VERSION ""

NS_ :

BS_:

BU_: CH DIPF DIPR ETH FC HVI HVS PARTY SDCV VEH VIRT

BO_ 1824 DAS_debug: 8 CH
 SG_ DAS_ACC_BCW m20 : 63|1@1+ (1,0) [0|1] ""  X
 SG_ DAS_driver_interaction_detected m45 : 63|1@1+ (1,0) [0|1] ""  X
 SG_ DAS_LC_Hands_On_Caused_By_Curve m40 : 63|1@1+ (1,0) [0|1] ""  X
 SG_ DAS_FCM_SL_radarMatchConfOK m32 : 62|1@1+ (1,0) [0|1] ""  X
 SG_ DAS_ACC_BCW_decelCheck m20 : 62|1@1+ (1,0) [0|1] ""  X
 SG_ DAS_FCM_CIPV_radarMatchConfOK m30 : 62|1@1+ (1,0) [0|1] ""  X
 SG_ DAS_pp_laneChange_freesp_avail_r m48 : 62|1@1+ (1,0) [0|1] ""  X
 SG_ DAS_VL_egoLaneChange m51 : 62|2@1+ (1,0) [0|3] ""  X
 SG_ DAS_LCM_CIPV_valid m37 : 62|1@1+ (1,0) [0|1] ""  X
 SG_ DAS_FCM_MCP_radarMatchConfOK m31 : 62|1@1+ (1,0) [0|1] ""  X
 SG_ DAS_SCA_egoCentered m45 : 62|1@1+ (1,0) [0|1] ""  X
 SG_ DAS_FCM_TA_mode m33 : 62|2@1+ (1,0) [0|3] ""  X
 SG_ DAS_FCM_MCP_valid m31 : 61|1@1+ (1,0) [0|1] ""  X
 SG_ DAS_HmVlNoInputsOAL m42 : 61|3@1+ (1,0) [0|7] ""  X
 SG_ DAS_FCM_SL_valid m32 : 61|1@1+ (1,0) [0|1] ""  X
 SG_ DAS_VL_V5_fuse m51 : 61|1@1+ (1,0) [0|1] ""  X
 SG_ DAS_pp_laneChange_freesp_avail_l m48 : 61|1@1+ (1,0) [0|1] ""  X
 SG_ DAS_accTimeGap m6 : 61|3@1+ (0.2,0.8) [0.8|2.2] "s"  X
 SG_ DAS_SCA_polyValid m45 : 61|1@1+ (1,0) [0|1] ""  X
 SG_ DAS_FCM_CIPV_valid m30 : 61|1@1+ (1,0) [0|1] ""  X
 SG_ DAS_ACC_tgt_mcvl_delay m24 : 60|4@1+ (20,0) [0|300] "ms"  X
 SG_ DAS_VL_LinePreference m50 : 60|3@1+ (1,0) [0|7] ""  X
 SG_ DAS_SCA_egoMovingRight m45 : 60|1@1+ (1,0) [0|1] ""  X
 SG_ DAS_ACC_tgt_cutin_delay m26 : 60|4@1+ (20,0) [0|300] "ms"  X
 SG_ DAS_ACC_tgt_cipv_delay m22 : 60|4@1+ (20,0) [0|300] "ms"  X
 SG_ DAS_ACC_tgt_cipv2_delay m23 : 60|4@1+ (20,0) [0|300] "ms"  X
 SG_ DAS_freespaceRightNearZ m2 : 60|4@1+ (4,0) [0|60] "m"  X
 SG_ DAS_LCM_CIPV_type m37 : 60|2@1+ (1,0) [0|3] ""  X
 SG_ DAS_ACC_tgt_mcvr_delay m25 : 60|4@1+ (20,0) [0|300] "ms"  X
 SG_ DAS_VL_V4_fuse m51 : 60|1@1+ (1,0) [0|1] ""  X
 SG_ DAS_ACC_overtakeMode m20 : 59|2@1+ (1,0) [0|3] ""  X
 SG_ DAS_ACC_tgt_cipv_blinkerRight m22 : 59|1@1+ (1,0) [0|1] ""  X
 SG_ DAS_ACC_Activate_pedestrian m28 : 59|1@1+ (1,0) [0|1] ""  X
 SG_ DAS_ACC_tgt_cipv2_blinkerRight m23 : 59|1@1+ (1,0) [0|1] ""  X
 SG_ DAS_VL_V3_fuse m51 : 59|1@1+ (1,0) [0|1] ""  X
 SG_ DAS_ACC_tgt_cutin_blinkerRight m26 : 59|1@1+ (1,0) [0|1] ""  X
 SG_ DAS_ACC_Target6_delay m27 : 59|4@1+ (20,0) [0|300] "ms"  X
 SG_ DAS_ACC_tgt_mcvr_blinkerRight m25 : 59|1@1+ (1,0) [0|1] ""  X
 SG_ DAS_ACC_tgt_mcvl_blinkerRight m24 : 59|1@1+ (1,0) [0|1] ""  X
 SG_ DAS_hands_on_warning_cipv_valid m45 : 59|1@1+ (1,0) [0|1] ""  X
 SG_ DAS_ACC_Activate_freespace m28 : 58|1@1+ (1,0) [0|1] ""  X
 SG_ DAS_ACC_tgt_cipv2_blinkerLeft m23 : 58|1@1+ (1,0) [0|1] ""  X
 SG_ DAS_ACC_Target6_stop_line_raw m27 : 58|1@1+ (1,0) [0|1] ""  X
 SG_ DAS_ACC_tgt_cipv_blinkerLeft m22 : 58|1@1+ (1,0) [0|1] ""  X
 SG_ DAS_LCM_CIPV_headway_time m38 : 58|6@1+ (0.1,0) [0|6.3] "s"  X
 SG_ DAS_ACC_tgt_mcvr_blinkerLeft m25 : 58|1@1+ (1,0) [0|1] ""  X
 SG_ DAS_ACC_tgt_cutin_blinkerLeft m26 : 58|1@1+ (1,0) [0|1] ""  X
 SG_ DAS_VL_V2_fuse m51 : 58|1@1+ (1,0) [0|1] ""  X
 SG_ DAS_ACC_tgt_mcvl_blinkerLeft m24 : 58|1@1+ (1,0) [0|1] ""  X
 SG_ DAS_hands_on_detected_offset m45 : 58|1@1+ (1,0) [0|1] ""  X
 SG_ DAS_ACC_tgt_cipv_brakeLights m22 : 57|1@1+ (1,0) [0|1] ""  X
 SG_ DAS_ACC_Target6_new m27 : 57|1@1+ (1,0) [0|1] ""  X
 SG_ DAS_hands_on_detected_default m45 : 57|1@1+ (1,0) [0|1] ""  X
 SG_ DAS_ACC_tgt_cutin_brakeLights m26 : 57|1@1+ (1,0) [0|1] ""  X
 SG_ DAS_VL_V1_fuse m51 : 57|1@1+ (1,0) [0|1] ""  X
 SG_ DAS_ACC_tgt_mcvl_brakeLights m24 : 57|1@1+ (1,0) [0|1] ""  X
 SG_ DAS_ACC_Activate_ultra_obs m28 : 57|1@1+ (1,0) [0|1] ""  X
 SG_ DAS_ACC_tgt_mcvr_brakeLights m25 : 57|1@1+ (1,0) [0|1] ""  X
 SG_ DAS_ACC_tgt_cipv2_brakeLights m23 : 57|1@1+ (1,0) [0|1] ""  X
 SG_ DAS_VWall_Right_c3 m44 : 56|8@1+ (2.4e-07,-3e-05) [-3e-05|3e-05] "m-2"  X
 SG_ DAS_ACC_tgt_mcvr_copied m25 : 56|1@1+ (1,0) [0|1] ""  X
 SG_ DAS_LCM_required_driver_accel m39 : 56|8@1- (0.1,-6.3) [-12.7|0] "m/s^2"  X
 SG_ DAS_freespaceLeftNearZ m2 : 56|4@1+ (4,0) [0|60] "m"  X
 SG_ DAS_appMobileyeStatus m0 : 56|8@1+ (1,0) [0|255] ""  X
 SG_ DAS_ACC_tgt_mcvl_copied m24 : 56|1@1+ (1,0) [0|1] ""  X
 SG_ DAS_ACC_controlType m20 : 56|3@1+ (1,0) [0|4] ""  X
 SG_ DAS_csa_desiredVelMeas m47 : 56|8@1+ (0.29,15) [15|88.95] "MPH"  X
 SG_ DAS_Planner_c3 m46 : 56|8@1+ (2.4e-07,-3e-05) [-3e-05|3e-05] "m-2"  X
 SG_ DAS_ACC_tgt_cutin_copied m26 : 56|1@1+ (1,0) [0|1] ""  X
 SG_ DAS_ACC_Target6_valid m27 : 56|1@1+ (1,0) [0|1] ""  X
 SG_ DAS_TFL_mainID m4 : 56|8@1+ (1,0) [0|255] ""  X
 SG_ DAS_ACC_tgt_cipv_copied m22 : 56|1@1+ (1,0) [0|1] ""  X
 SG_ DAS_FCM_DBG_ass_age m35 : 56|6@1+ (100,0) [0|6300] "FIXME"  X
 SG_ DAS_ACC_tgt_cipv2_copied m23 : 56|1@1+ (1,0) [0|1] ""  X
 SG_ DAS_unusedW0 m3 : 56|8@1+ (1,0) [0|255] ""  X
 SG_ DAS_VL_NAV_fuse m51 : 56|1@1+ (1,0) [0|1] ""  X
 SG_ DAS_VL_Mode m50 : 56|4@1+ (1,0) [0|15] ""  X
 SG_ DAS_ACC_Activate_rad_tar_5 m28 : 56|1@1+ (1,0) [0|1] ""  X
 SG_ DAS_ACC_tgt_cutin_new m26 : 55|1@1+ (1,0) [0|1] ""  X
 SG_ DAS_ACC_tgt_mcvr_new m25 : 55|1@1+ (1,0) [0|1] ""  X
 SG_ DAS_VL_HPP_fuse m51 : 55|1@1+ (1,0) [0|1] ""  X
 SG_ DAS_ACC_tgt_mcvl_new m24 : 55|1@1+ (1,0) [0|1] ""  X
 SG_ DAS_ACC_Activate_stw_angle m28 : 55|1@1+ (1,0) [0|1] ""  X
 SG_ DAS_ACC_tgt_cipv_new m22 : 55|1@1+ (1,0) [0|1] ""  X
 SG_ DAS_VL_V5_quality m50 : 55|1@1+ (1,0) [0|1] ""  X
 SG_ DAS_ACC_tgt_cipv2_new m23 : 55|1@1+ (1,0) [0|1] ""  X
 SG_ DAS_ACC_tgt_cipv2_valid m23 : 54|1@1+ (1,0) [0|1] ""  X
 SG_ DAS_FCM_TA_distDiffSteerAeb m33 : 54|8@1+ (0.1,0) [0|25.5] "m"  X
 SG_ DAS_TFL_warning m4 : 54|1@1+ (1,0) [0|1] ""  X
 SG_ DAS_ACC_tgt_cipv_valid m22 : 54|1@1+ (1,0) [0|1] ""  X
 SG_ DAS_ACC_tgt_mcvr_valid m25 : 54|1@1+ (1,0) [0|1] ""  X
 SG_ DAS_ACC_tgt_cutin_valid m26 : 54|1@1+ (1,0) [0|1] ""  X
 SG_ DAS_ACC_Activate_road_class m28 : 54|1@1+ (1,0) [0|1] ""  X
 SG_ DAS_VL_RL_fuse m51 : 54|1@1+ (1,0) [0|1] ""  X
 SG_ DAS_ACC_radInFrontOfCIPVRel m20 : 54|1@1+ (1,0) [0|1] ""  X
 SG_ DAS_ACC_tgt_mcvl_valid m24 : 54|1@1+ (1,0) [0|1] ""  X
 SG_ DAS_laneMerge m2 : 54|2@1+ (1,0) [0|3] ""  X
 SG_ DAS_VL_V4_quality m50 : 54|1@1+ (1,0) [0|1] ""  X
 SG_ DAS_eldw m2 : 53|1@1+ (1,0) [0|1] ""  X
 SG_ DAS_ACC_camInFrontOfCIPVRel m20 : 53|1@1+ (1,0) [0|1] ""  X
 SG_ DAS_ACC_pathOverlapWTarget m21 : 53|5@1+ (0.2,-2) [-2|4.2] "m"  X
 SG_ DAS_VL_LL_fuse m51 : 53|1@1+ (1,0) [0|1] ""  X
 SG_ DAS_VL_V3_quality m50 : 53|1@1+ (1,0) [0|1] ""  X
 SG_ DAS_ACC_Activate_travel_dist m28 : 53|1@1+ (1,0) [0|1] ""  X
 SG_ DAS_ACC_rightLaneExists m20 : 52|1@1+ (1,0) [0|1] ""  X
 SG_ DAS_LC_EgoPitchMotionRate m29 : 52|10@1+ (0.05,-25) [-25|25] "deg/s"  X
 SG_ DAS_LCM_fcw_unavailable_reason m36 : 52|4@1+ (1,0) [0|13] ""  X
 SG_ DAS_VL_V4_V5_crossCheck m51 : 52|1@1+ (1,0) [0|1] ""  X
 SG_ DAS_ACC_camPedestriansPresent m21 : 52|1@1+ (1,0) [0|1] ""  X
 SG_ DAS_ACC_Activate_healthy m28 : 52|1@1+ (1,0) [0|1] ""  X
 SG_ DAS_LCM_CIPV_ttc m38 : 52|6@1+ (0.05,0) [0|3.15] "s"  X
 SG_ DAS_LCM_CIPV_vy m37 : 52|8@1- (0.1,0.0) [-12.8|12.7] "m/s"  X
 SG_ DAS_VL_V2_quality m50 : 52|1@1+ (1,0) [0|1] ""  X
 SG_ DAS_lanesValid m2 : 52|1@1+ (1,0) [0|1] ""  X
 SG_ DAS_ACC_Target6_type m27 : 52|4@1+ (1,0) [0|11] ""  X
 SG_ DAS_FCM_CIPV_relAccel m30 : 51|10@1+ (0.03125,-16) [-16|15.96875] "m/s^2"  X
 SG_ DAS_ACC_camRightCloseCutin m21 : 51|1@1+ (1,0) [0|1] ""  X
 SG_ DAS_VL_V3_V5_crossCheck m51 : 51|1@1+ (1,0) [0|1] ""  X
 SG_ DAS_ACC_leftLaneExists m20 : 51|1@1+ (1,0) [0|1] ""  X
 SG_ DAS_FCM_MCP_relAccel m31 : 51|10@1+ (0.03125,-16) [-16|15.96875] "m/s^2"  X
 SG_ DAS_VL_NAV_rejectCounter m50 : 51|1@1+ (1,0) [0|1] ""  X
 SG_ DAS_FCM_SL_relAccel m32 : 51|10@1+ (0.03125,-16) [-16|15.96875] "m/s^2"  X
 SG_ DAS_resumeSpeed m6 : 51|10@1+ (0.2,0) [0|102.2] "mph"  X
 SG_ DAS_ACC_tgt_cipv2_type m23 : 50|4@1+ (1,0) [0|11] ""  X
 SG_ DAS_FCM_DBG_dist_check m35 : 50|6@1+ (0.05,0) [0|3.15] "probability"  X
 SG_ DAS_PF_PercentConsistency m41 : 50|14@1+ (0.01,0) [0|163.83] "%"  X
 SG_ DAS_ACC_tgt_mcvl_type m24 : 50|4@1+ (1,0) [0|11] ""  X
 SG_ DAS_VL_NAV_rejectAge m50 : 50|1@1+ (1,0) [0|1] ""  X
 SG_ DAS_freespaceLDW m2 : 50|2@1+ (1,0) [0|3] ""  X
 SG_ DAS_VL_V3_V4_crossCheck m51 : 50|1@1+ (1,0) [0|1] ""  X
 SG_ DAS_ACC_camLeftCloseCutin m21 : 50|1@1+ (1,0) [0|1] ""  X
 SG_ DAS_ACC_tgt_cutin_type m26 : 50|4@1+ (1,0) [0|11] ""  X
 SG_ DAS_ACC_tgt_mcvr_type m25 : 50|4@1+ (1,0) [0|11] ""  X
 SG_ DAS_PMM_rearThreat m11 : 50|2@1+ (1,0) [0|3] ""  X
 SG_ DAS_ACC_tgt_cipv_type m22 : 50|4@1+ (1,0) [0|11] ""  X
 SG_ DAS_VL_NAV_rejectHealth m50 : 49|1@1+ (1,0) [0|1] ""  X
 SG_ DAS_VL_V2_V5_crossCheck m51 : 49|1@1+ (1,0) [0|1] ""  X
 SG_ DAS_VL_HPP_rejectCipvClose m50 : 48|1@1+ (1,0) [0|1] ""  X
 SG_ DAS_VWall_Right_c2 m44 : 48|8@1+ (2e-05,-0.0025) [-0.0025|0.0025] "m-1"  X
 SG_ DAS_i2c_sensor_cmd m12 : 48|16@1+ (1,0) [0|65535] ""  X
 SG_ DAS_Planner_c2 m46 : 48|8@1+ (2e-05,-0.0025) [-0.0025|0.0025] "m-1"  X
 SG_ DAS_csa_measuredLatAccel m47 : 48|8@1+ (0.08,-10.24) [-10.24|10] "m/s^2"  X
 SG_ DAS_rawLDW m2 : 48|2@1+ (1,0) [0|3] ""  X
 SG_ DAS_ACC_camStopAndGoStatus m21 : 48|2@1+ (1,0) [0|3] ""  X
 SG_ DAS_PMM_frontThreat m11 : 48|2@1+ (1,0) [0|3] ""  X
 SG_ DAS_pp_offset_objDurationRight m49 : 48|8@1+ (4,0) [0|1000] "s"  X
 SG_ DAS_numOfCrcErrs m3 : 48|8@1+ (1,0) [0|255] ""  X
 SG_ DAS_VL_V2_V4_crossCheck m51 : 48|1@1+ (1,0) [0|1] ""  X
 SG_ DAS_LCM_aeb_evading_distance m39 : 48|8@1- (0.1,0.1) [-12.7|12.8] "m"  X
 SG_ DAS_ACC_Target6_controlState m27 : 48|4@1+ (1,0) [0|10] ""  X
 SG_ DAS_pp_offset_desired m0 : 48|8@1- (0.01,0.0) [-1.28|1.27] "m"  X
 SG_ DAS_VL_HPP_rejectNight m50 : 47|1@1+ (1,0) [0|1] ""  X
 SG_ DAS_VL_V2_V3_crossCheck m51 : 47|1@1+ (1,0) [0|1] ""  X
 SG_ DAS_LC_Crit_Right_Lane m40 : 47|8@1+ (0.2,-25.5) [-25.5|25.5] "m"  X
 SG_ DAS_FCM_DBG_ID m34 : 47|16@1+ (1,0) [0|65535] ""  X
 SG_ DAS_LCM_aeb_unavailable_reason m36 : 47|5@1+ (1,0) [0|17] ""  X
 SG_ DAS_ACC_tgt_cipv2_controlState m23 : 46|4@1+ (1,0) [0|10] ""  X
 SG_ DAS_VL_HPP_rejectWiper m50 : 46|1@1+ (1,0) [0|1] ""  X
 SG_ DAS_ACC_tgt_mcvl_controlState m24 : 46|4@1+ (1,0) [0|10] ""  X
 SG_ DAS_FCM_TA_distDiffSteerDrvr m33 : 46|8@1+ (0.1,0) [0|25.5] "m"  X
 SG_ DAS_ACC_camCIPVFreeSpace m21 : 46|2@1+ (1,0) [0|3] ""  X
 SG_ DAS_VL_V1_V5_crossCheck m51 : 46|1@1+ (1,0) [0|1] ""  X
 SG_ DAS_ACC_tgt_cutin_controlState m26 : 46|4@1+ (1,0) [0|10] ""  X
 SG_ DAS_ACC_tgt_mcvr_controlState m25 : 46|4@1+ (1,0) [0|10] ""  X
 SG_ DAS_FCM_DBG_ACC5_fused m34 : 46|1@1+ (1,0) [0|1] ""  X
 SG_ DAS_ACC_tgt_cipv_controlState m22 : 46|4@1+ (1,0) [0|10] ""  X
 SG_ DAS_VL_V1_V4_crossCheck m51 : 45|1@1+ (1,0) [0|1] ""  X
 SG_ DAS_TFL_ttc m4 : 45|9@1+ (0.01,0) [0|5.11] "seconds"  X
 SG_ DAS_VL_HPP_rejectRange m50 : 45|1@1+ (1,0) [0|1] ""  X
 SG_ DAS_IDF_measurementState m36 : 45|2@1+ (1,0) [0|2] ""  X
 SG_ DAS_csa_offramp_usage_duration m48 : 45|8@1+ (256,0) [0|65535] "FIXME"  X
 SG_ DAS_TBT_offset m45 : 45|11@1+ (0.001,-1) [-1|1] "Nm"  X
 SG_ DAS_FCM_DBG_ACC1_fused m34 : 45|1@1+ (1,0) [0|1] ""  X
 SG_ DAS_FCM_DBG_rvl_check m35 : 44|6@1+ (0.05,0) [0|3.15] "probability"  X
 SG_ DAS_ACC_deadbandMultiplier m20 : 44|7@1+ (0.008,0) [0|1.016] "1"  X
 SG_ DAS_freespaceRightFarZ m2 : 44|4@1+ (4,0) [0|60] "m"  X
 SG_ DAS_VL_V1_V3_crossCheck m51 : 44|1@1+ (1,0) [0|1] ""  X
 SG_ DAS_FCM_DBG_aeb_fault m34 : 44|1@1+ (1,0) [0|1] ""  X
 SG_ DAS_ACC_camCIPVLost m21 : 44|2@1+ (1,0) [0|3] ""  X
 SG_ DAS_IDF_checkLateralAcceleration m36 : 44|1@1+ (1,0) [0|1] ""  X
 SG_ DAS_SP_endPosY m8 : 44|12@1+ (0.01,-20.48) [-20.48|20.48] "m"  X
 SG_ DAS_hands_on_detected m45 : 44|1@1+ (1,0) [0|1] ""  X
 SG_ DAS_LCM_CIPV_overlap m38 : 44|8@1- (0.05,0.05) [-6.3|6.4] "m"  X
 SG_ DAS_VL_HPP_rejectError m50 : 44|1@1+ (1,0) [0|1] ""  X
 SG_ DAS_FCM_DBG_aeb_cancel m34 : 43|1@1+ (1,0) [0|1] ""  X
 SG_ DAS_VL_V1_V2_crossCheck m51 : 43|1@1+ (1,0) [0|1] ""  X
 SG_ DAS_IDF_checkCameraTTC m36 : 43|1@1+ (1,0) [0|1] ""  X
 SG_ DAS_VL_RL_rejectCounter m50 : 43|1@1+ (1,0) [0|1] ""  X
 SG_ DAS_ACC_Restrict_deltaV_deriv m29 : 42|10@1+ (0.01,-5) [-5|5.23] "m/s^2"  X
 SG_ DAS_IDF_checkImpactVelocity m36 : 42|1@1+ (1,0) [0|1] ""  X
 SG_ DAS_VL_NAV_V5_crossCheck m51 : 42|1@1+ (1,0) [0|1] ""  X
 SG_ DAS_VL_RL_rejectHWExit m50 : 42|1@1+ (1,0) [0|1] ""  X
 SG_ DAS_ACC_Control_deltaV_deriv m28 : 42|10@1+ (0.01,-5) [-5|5.23] "m/s^2"  X
 SG_ DAS_estimatedSpeedLimit m6 : 41|10@1+ (0.2,0) [0|102.2] "mph"  X
 SG_ DAS_FCM_DBG_me_flag m34 : 41|1@1+ (1,0) [0|1] ""  X
 SG_ DAS_VL_NAV_V4_crossCheck m51 : 41|1@1+ (1,0) [0|1] ""  X
 SG_ DAS_LCM_required_system_accel m39 : 41|7@1- (0.20158730158730157,-6.249206349206348) [-12.7|0] "m/s^2"  X
 SG_ DAS_VL_RL_rejectPrediction m50 : 41|1@1+ (1,0) [0|1] ""  X
 SG_ DAS_ACC_camCIPVMotionStatus m21 : 40|4@1+ (1,0) [0|15] ""  X
 SG_ DAS_pp_offset_objDurationLeft m49 : 40|8@1+ (4,0) [0|1000] "s"  X
 SG_ DAS_Planner_c1 m46 : 40|8@1+ (0.0016,-0.2) [-0.2|0.2] "rad"  X
 SG_ DAS_csa_desiredVelPred m47 : 40|8@1+ (0.29,15) [15|88.95] "MPH"  X
 SG_ DAS_PMM_totalThreat m11 : 40|8@1+ (1,0) [0|255] ""  X
 SG_ DAS_ACC_Target6_accel m27 : 40|8@1+ (0.06,-10) [-10|5.3] "m/s^2"  X
 SG_ DAS_SYNC_DASLocalTimeStamp m100 : 47|24@0+ (1,0) [0|16777215] ""  X
 SG_ DAS_LCM_CIPV_vx m37 : 40|12@1- (0.0625,0.0) [-128|127.9375] "m/s"  X
 SG_ DAS_SP_cDesired m7 : 40|8@1+ (0.0025,-0.32) [-0.32|0.31] "1/m"  X
 SG_ DAS_VWall_Right_c1 m44 : 40|8@1+ (0.0016,-0.2) [-0.2|0.2] "rad"  X
 SG_ DAS_VL_NAV_V3_crossCheck m51 : 40|1@1+ (1,0) [0|1] ""  X
 SG_ DAS_VL_RL_rejectLatDiffAtCP m50 : 40|1@1+ (1,0) [0|1] ""  X
 SG_ DAS_FCM_DBG_suppressed m34 : 40|1@1+ (1,0) [0|1] ""  X
 SG_ DAS_freespaceLeftFarZ m2 : 40|4@1+ (4,0) [0|60] "m"  X
 SG_ DAS_HmLaneViewRangeOAL m42 : 40|3@1+ (1,0) [0|7] ""  X
 SG_ DAS_i2c_bytes_written m12 : 40|8@1+ (1,0) [0|255] ""  X
 SG_ DAS_numOfSeqErrs m3 : 40|8@1+ (1,0) [0|255] ""  X
 SG_ DAS_VL_NAV_V2_crossCheck m51 : 39|1@1+ (1,0) [0|1] ""  X
 SG_ DAS_FCM_MCP_relSpeed m31 : 39|12@1+ (0.0625,-128) [-128|127.9375] "m/s"  X
 SG_ DAS_rampType m6 : 39|2@1+ (1,0) [0|3] ""  X
 SG_ DAS_FCM_TA_reqAccelAeb m33 : 39|7@1+ (0.1,-12.7) [-12.7|0] "m/s^2"  X
 SG_ DAS_VL_RL_rejectDyingLine m50 : 39|1@1+ (1,0) [0|1] ""  X
 SG_ DAS_FCM_CIPV_relSpeed m30 : 39|12@1+ (0.0625,-128) [-128|127.9375] "m/s"  X
 SG_ DAS_FCM_SL_relSpeed m32 : 39|12@1+ (0.0625,-128) [-128|127.9375] "m/s"  X
 SG_ DAS_ACC_tgt_cipv2_accel m23 : 38|8@1+ (0.06,-10) [-10|5.3] "m/s^2"  X
 SG_ DAS_ACC_tgt_cutin_accel m26 : 38|8@1+ (0.06,-10) [-10|5.3] "m/s^2"  X
 SG_ DAS_VL_NAV_V1_crossCheck m51 : 38|1@1+ (1,0) [0|1] ""  X
 SG_ DAS_ACC_tgt_mcvl_accel m24 : 38|8@1+ (0.06,-10) [-10|5.3] "m/s^2"  X
 SG_ DAS_FCM_DBG_trust m35 : 38|6@1+ (0.05,0) [0|3.15] "probability"  X
 SG_ DAS_ACC_tgt_mcvr_accel m25 : 38|8@1+ (0.06,-10) [-10|5.3] "m/s^2"  X
 SG_ DAS_VL_RL_rejectFreespace m50 : 38|1@1+ (1,0) [0|1] ""  X
 SG_ DAS_ACC_tgt_cipv_accel m22 : 38|8@1+ (0.06,-10) [-10|5.3] "m/s^2"  X
 SG_ DAS_csa_mpp_jump_up_distance m48 : 37|8@1+ (10,0) [0|2550] "m"  X
 SG_ DAS_LCM_state m39 : 37|4@1+ (1,0) [0|10] ""  X
 SG_ DAS_VL_RL_rejectRange m50 : 37|1@1+ (1,0) [0|1] ""  X
 SG_ DAS_VL_HPP_V5_crossCheck m51 : 37|1@1+ (1,0) [0|1] ""  X
 SG_ DAS_PF_VirtualLane_STW m41 : 37|13@1+ (0.1,-409.6) [-409.6|409.5] "deg"  X
 SG_ DAS_VL_HPP_V4_crossCheck m51 : 36|1@1+ (1,0) [0|1] ""  X
 SG_ DAS_VL_RL_rejectType m50 : 36|1@1+ (1,0) [0|1] ""  X
 SG_ DAS_csa_mpp_jumped_up m48 : 36|1@1+ (1,0) [0|1] ""  X
 SG_ DAS_ACC_Ego_accel m20 : 36|8@1+ (0.06,-10) [-10|5.3] "m/s^2"  X
 SG_ DAS_ACC_camCIPVBrakeLight m21 : 36|4@1+ (1,0) [0|15] ""  X
 SG_ DAS_LCM_fcw_rel_vel m39 : 36|1@1+ (1,0) [0|1] ""  X
 SG_ DAS_VL_HPP_V3_crossCheck m51 : 35|1@1+ (1,0) [0|1] ""  X
 SG_ DAS_VL_RL_rejectQuality m50 : 35|1@1+ (1,0) [0|1] ""  X
 SG_ DAS_LCM_fcw_evading_dist m39 : 35|1@1+ (1,0) [0|1] ""  X
 SG_ DAS_csa_using_frozen_offramp m48 : 35|1@1+ (1,0) [0|1] ""  X
 SG_ DAS_VL_LL_rejectCounter m50 : 34|1@1+ (1,0) [0|1] ""  X
 SG_ DAS_VL_HPP_V2_crossCheck m51 : 34|1@1+ (1,0) [0|1] ""  X
 SG_ DAS_ACC_Target6_radID m27 : 34|6@1+ (1,0) [0|63] ""  X
 SG_ DAS_LCM_fcw_delayed_accel m39 : 34|1@1+ (1,0) [0|1] ""  X
 SG_ DAS_IDF_predictedOverlap m36 : 34|8@1+ (0.5,0) [0|127.5] "percent"  X
 SG_ DAS_csa_using_offramp m48 : 34|1@1+ (1,0) [0|1] ""  X
 SG_ DAS_TFL_stop_line_dist m4 : 34|11@1+ (0.1,-50) [-50|102.3] "m"  X
 SG_ DAS_estimatedSpeedLimitType m6 : 33|3@1+ (1,0) [0|7] ""  X
 SG_ DAS_VL_HPP_V1_crossCheck m51 : 33|1@1+ (1,0) [0|1] ""  X
 SG_ DAS_VL_LL_rejectHWExit m50 : 33|1@1+ (1,0) [0|1] ""  X
 SG_ DAS_LCM_fcw_current_accel m39 : 33|1@1+ (1,0) [0|1] ""  X
 SG_ DAS_PMM_radarDistance m11 : 32|8@1+ (1,0) [0|255] "m"  X
 SG_ DAS_SP_collisionDist m9 : 32|12@1+ (0.01,-20.48) [-20.48|20.48] "m"  X
 SG_ DAS_VL_LL_rejectPrediction m50 : 32|1@1+ (1,0) [0|1] ""  X
 SG_ DAS_LCM_CIPV_width m37 : 32|8@1+ (0.05,0) [0|12.7] "m"  X
 SG_ DAS_SP_interCMax m7 : 32|8@1+ (0.0025,-0.32) [-0.32|0.31] "1/m"  X
 SG_ DAS_ACC_tgt_mcvl_radID m24 : 32|6@1+ (1,0) [0|63] ""  X
 SG_ DAS_FCM_CIPV_width m30 : 32|7@1+ (0.05,0) [0|6.35] "m"  X
 SG_ DAS_freespaceRightC1 m2 : 32|8@1+ (0.0016,-0.2) [-0.2|0.2] "rad"  X
 SG_ DAS_FCM_TA_reqAccelDrvr m33 : 32|7@1+ (0.1,-12.7) [-12.7|0] "m/s^2"  X
 SG_ DAS_ACC_tgt_mcvr_radID m25 : 32|6@1+ (1,0) [0|63] ""  X
 SG_ DAS_FCM_DBG_probability m35 : 32|6@1+ (0.05,0) [0|3.15] "probability"  X
 SG_ DAS_VL_HPP_NAV_crossCheck m51 : 32|1@1+ (1,0) [0|1] ""  X
 SG_ DAS_LCM_fcw_overlap m39 : 32|1@1+ (1,0) [0|1] ""  X
 SG_ DAS_autoWipersValid m60 : 32|1@1+ (1,0) [0|1] ""  X
 SG_ DAS_ACC_Restrict_severity m29 : 32|10@1+ (0.005,-2.56) [-2.56|2.555] "1"  X
 SG_ DAS_ACC_Control_severity m28 : 32|10@1+ (0.005,-2.56) [-2.56|2.555] "1"  X
 SG_ DAS_ACC_tgt_cipv2_radID m23 : 32|6@1+ (1,0) [0|63] ""  X
 SG_ DAS_torque_filt_0p5Hz m45 : 32|12@1+ (0.01,-20.5) [-20.5|20.45] "Nm"  X
 SG_ DAS_FCM_MCP_width m31 : 32|7@1+ (0.05,0) [0|6.35] "m"  X
 SG_ DAS_SP_endPosX m8 : 32|12@1+ (0.01,-20.48) [-20.48|20.48] "m"  X
 SG_ DAS_ACC_tgt_cipv_radID m22 : 32|6@1+ (1,0) [0|63] ""  X
 SG_ DAS_FCM_TA_stage3Checks m34 : 32|8@1+ (1,0) [0|255] ""  X
 SG_ DAS_ACC_camCIPVLaneStatus m21 : 32|4@1+ (1,0) [0|15] ""  X
 SG_ DAS_numOfOldPktErrs m3 : 32|8@1+ (1,0) [0|255] ""  X
 SG_ DAS_FCM_SL_width m32 : 32|7@1+ (0.05,0) [0|6.35] "m"  X
 SG_ DAS_VWall_Right_c0 m44 : 32|8@1+ (0.035,0) [0|7] "m"  X
 SG_ DAS_ACC_tgt_cutin_radID m26 : 32|6@1+ (1,0) [0|63] ""  X
 SG_ DAS_Planner_c0 m46 : 32|8@1- (0.1,0.0) [-12.8|12.7] "m"  X
 SG_ DAS_LCM_CIPV_track_age m38 : 32|12@1+ (0.01,0) [0|40.95] "s"  X
 SG_ DAS_pp_offset_offsetObjectRight m49 : 32|8@1- (0.01,0.0) [-1.28|1.27] "m"  X
 SG_ DAS_SP_autoSummonRequest m6 : 32|1@1+ (1,0) [0|1] ""  X
 SG_ DAS_VL_RL_V5_crossCheck m51 : 31|1@1+ (1,0) [0|1] ""  X
 SG_ DAS_LCM_fcw_abs_accel m39 : 31|1@1+ (1,0) [0|1] ""  X
 SG_ DAS_VL_LL_rejectLatDiffAtCP m50 : 31|1@1+ (1,0) [0|1] ""  X
 SG_ DAS_LC_Crit_Left_Lane m40 : 31|8@1+ (0.2,-25.5) [-25.5|25.5] "m"  X
 SG_ DAS_LCM_jerk_rel_vel m39 : 30|1@1+ (1,0) [0|1] ""  X
 SG_ DAS_LC_Speed_Ctrl_Active m40 : 30|1@1+ (1,0) [0|1] ""  X
 SG_ DAS_VL_LL_rejectDyingLine m50 : 30|1@1+ (1,0) [0|1] ""  X
 SG_ DAS_VL_RL_V4_crossCheck m51 : 30|1@1+ (1,0) [0|1] ""  X
 SG_ DAS_LCM_jerk_evading_dist m39 : 29|1@1+ (1,0) [0|1] ""  X
 SG_ DAS_VL_RL_V3_crossCheck m51 : 29|1@1+ (1,0) [0|1] ""  X
 SG_ DAS_VL_LL_rejectFreespace m50 : 29|1@1+ (1,0) [0|1] ""  X
 SG_ DAS_SP_status m6 : 28|4@1+ (1,0) [0|15] ""  X
 SG_ DAS_LCM_jerk_delayed_accel m39 : 28|1@1+ (1,0) [0|1] ""  X
 SG_ DAS_VL_RL_V2_crossCheck m51 : 28|1@1+ (1,0) [0|1] ""  X
 SG_ DAS_ACC_camCIPVLane m21 : 28|4@1+ (1,0) [0|15] ""  X
 SG_ DAS_VL_LL_rejectRange m50 : 28|1@1+ (1,0) [0|1] ""  X
 SG_ DAS_IDF_predictedImpactVelocity m36 : 27|7@1+ (0.5,0) [0|63.5] "m/s"  X
 SG_ DAS_LCM_jerk_current_accel m39 : 27|1@1+ (1,0) [0|1] ""  X
 SG_ DAS_VL_RL_V1_crossCheck m51 : 27|1@1+ (1,0) [0|1] ""  X
 SG_ DAS_VL_LL_rejectType m50 : 27|1@1+ (1,0) [0|1] ""  X
 SG_ DAS_VL_RL_NAV_crossCheck m51 : 26|1@1+ (1,0) [0|1] ""  X
 SG_ DAS_VL_LL_rejectQuality m50 : 26|1@1+ (1,0) [0|1] ""  X
 SG_ DAS_LCM_jerk_overlap m39 : 26|1@1+ (1,0) [0|1] ""  X
 SG_ DAS_LC_AutopilotInternalState m40 : 26|4@1+ (1,0) [0|15] ""  X
 SG_ DAS_ACC_Ego_speed m20 : 26|10@1+ (0.05,0) [0|51.15] "m/s"  X
 SG_ DAS_VL_RL_HPP_crossCheck m51 : 25|1@1+ (1,0) [0|1] ""  X
 SG_ DAS_LCM_jerk_abs_accel m39 : 25|1@1+ (1,0) [0|1] ""  X
 SG_ DAS_VL_Reinitialized m50 : 25|1@1+ (1,0) [0|1] ""  X
 SG_ DAS_ACC_camCIPVRelevancy m21 : 24|4@1+ (1,0) [0|15] ""  X
 SG_ DAS_PMM_radarConfidence m11 : 24|8@1+ (1,0) [0|255] ""  X
 SG_ DAS_autofixYaw m1 : 24|8@1- (1,0) [-128|127] ""  X
 SG_ DAS_i2c_cmd_idx m12 : 24|16@1+ (1,0) [0|65535] ""  X
 SG_ DAS_csa_filteredCurvature m47 : 24|16@1- (1e-06,0.0) [-0.032768|0.032767] "1/m"  X
 SG_ DAS_ACC_tgt_mcvl_speed m24 : 24|8@1+ (0.2,-5) [-5|46] "m/s"  X
 SG_ DAS_ACC_Target6_speed m27 : 24|8@1+ (0.2,-5) [-5|46] "m/s"  X
 SG_ DAS_SP_interCMin m7 : 24|8@1+ (0.0025,-0.32) [-0.32|0.31] "1/m"  X
 SG_ DAS_SP_instruction m6 : 24|4@1+ (1,0) [0|15] ""  X
 SG_ DAS_freespaceRightC0 m2 : 24|8@1+ (0.1,-12.8) [-12.8|12.7] "m"  X
 SG_ DAS_ACC_tgt_cutin_speed m26 : 24|8@1+ (0.2,-5) [-5|46] "m/s"  X
 SG_ DAS_TFL_jnc_dist m4 : 24|10@1+ (0.25,-50) [-50|205.75] "m"  X
 SG_ DAS_FCM_TA_stage2Checks m34 : 24|8@1+ (1,0) [0|255] ""  X
 SG_ DAS_pp_offset_offsetObjectLeft m49 : 24|8@1- (0.01,0.0) [-1.28|1.27] "m"  X
 SG_ DAS_ACC_tgt_cipv2_speed m23 : 24|8@1+ (0.2,-5) [-5|46] "m/s"  X
 SG_ DAS_IDF_objectClass m36 : 24|3@1+ (1,0) [0|5] ""  X
 SG_ DAS_LCM_aeb_rel_vel m39 : 24|1@1+ (1,0) [0|1] ""  X
 SG_ DAS_LC_PathFollowerAngle m42 : 24|13@1- (0.1,0.0) [-409.6|409.5] "deg"  X
 SG_ DAS_ACC_tgt_cipv_speed m22 : 24|8@1+ (0.2,-5) [-5|46] "m/s"  X
 SG_ DAS_SCA_TWC_Right m45 : 24|8@1+ (0.01,0) [0|2.55] "s"  X
 SG_ DAS_ACC_tgt_mcvr_speed m25 : 24|8@1+ (0.2,-5) [-5|46] "m/s"  X
 SG_ DAS_FCM_TA_rstCollStRsn m33 : 24|8@1+ (1,0) [0|255] ""  X
 SG_ DAS_autoWipersPerMinute m60 : 24|8@1+ (1,0) [0|100] ""  X
 SG_ DAS_PF_Navigation_STW m41 : 24|13@1+ (0.1,-409.6) [-409.6|409.5] "deg"  X
 SG_ DAS_LCM_CIPV_id m38 : 24|8@1+ (1,0) [0|255] ""  X
 SG_ DAS_VL_LL_V5_crossCheck m51 : 24|1@1+ (1,0) [0|1] ""  X
 SG_ DAS_VL_LL_V4_crossCheck m51 : 23|1@1+ (1,0) [0|1] ""  X
 SG_ DAS_LCM_aeb_evading_dist m39 : 23|1@1+ (1,0) [0|1] ""  X
 SG_ DAS_pp_offset_activeRight m49 : 23|1@1+ (1,0) [0|1] ""  X
 SG_ DAS_HmSecondaryVlInput m41 : 23|1@1+ (1,0) [0|1] ""  X
 SG_ DAS_pp_offset_activeLeft m49 : 22|1@1+ (1,0) [0|1] ""  X
 SG_ DAS_ACC_Control_ve_d m28 : 22|10@1+ (0.05,0) [0|51.15] "m/s"  X
 SG_ DAS_ACC_Restrict_ve_d m29 : 22|10@1+ (0.05,0) [0|51.15] "m/s"  X
 SG_ DAS_VL_LL_V3_crossCheck m51 : 22|1@1+ (1,0) [0|1] ""  X
 SG_ DAS_torque_filt_0p05Hz m48 : 22|12@1+ (0.01,-20.5) [-20.5|20.45] "Nm"  X
 SG_ DAS_LCM_aeb_delayed_accel m39 : 22|1@1+ (1,0) [0|1] ""  X
 SG_ DAS_VL_WidthMeasType m50 : 22|3@1+ (1,0) [0|7] ""  X
 SG_ DAS_VL_V1_quality m50 : 21|1@1+ (1,0) [0|1] ""  X
 SG_ DAS_LCM_aeb_current_accel m39 : 21|1@1+ (1,0) [0|1] ""  X
 SG_ DAS_VL_LL_V2_crossCheck m51 : 21|1@1+ (1,0) [0|1] ""  X
 SG_ DAS_ACC_drivingOnHighway m20 : 21|1@1+ (1,0) [0|1] ""  X
 SG_ DAS_Planner_externalstate m46 : 21|4@1+ (1,0) [0|15] ""  X
 SG_ DAS_pp_laneChange_blinkerCheck m48 : 21|1@1+ (1,0) [0|1] ""  X
 SG_ DAS_TFL_jnc_status m4 : 21|3@1+ (1,0) [0|7] ""  X
 SG_ DAS_LCM_aeb_overlap m39 : 20|1@1+ (1,0) [0|1] ""  X
 SG_ DAS_SP_vehPosY m8 : 20|12@1+ (0.01,-20.48) [-20.48|20.48] "m"  X
 SG_ DAS_VL_LL_V1_crossCheck m51 : 20|1@1+ (1,0) [0|1] ""  X
 SG_ DAS_Stop_Sign_warning m4 : 20|1@1+ (1,0) [0|1] ""  X
 SG_ DAS_FCM_MCP_latDistance m31 : 20|12@1- (0.05,0.0) [-102.4|102.35] "m"  X
 SG_ DAS_ACC_camCIPVClass m21 : 20|4@1+ (1,0) [0|15] ""  X
 SG_ DAS_LCM_CIPV_dy m37 : 20|12@1- (0.05,0.0) [-102.4|102.35] "m"  X
 SG_ DAS_VL_NAV_quality m50 : 20|1@1+ (1,0) [0|1] ""  X
 SG_ DAS_FCM_DBG_cam_relvel m35 : 20|12@1+ (0.0625,-128) [-128|127.9375] "m/s"  X
 SG_ DAS_FCM_SL_latDistance m32 : 20|12@1- (0.05,0.0) [-102.4|102.35] "m"  X
 SG_ DAS_pp_laneChange_LC_healthy m48 : 20|1@1+ (1,0) [0|1] ""  X
 SG_ DAS_SP_sprecordY m9 : 20|12@1+ (0.01,-20.48) [-20.48|20.48] "m"  X
 SG_ DAS_errorFrameNum m3 : 20|12@1+ (1,0) [0|4095] ""  X
 SG_ DAS_FCM_CIPV_latDistance m30 : 20|12@1- (0.05,0.0) [-102.4|102.35] "m"  X
 SG_ DAS_VL_HPP_quality m50 : 19|1@1+ (1,0) [0|1] ""  X
 SG_ DAS_LCM_aeb_abs_accel m39 : 19|1@1+ (1,0) [0|1] ""  X
 SG_ DAS_ACC_pedestrianStatus m20 : 19|2@1+ (1,0) [0|3] ""  X
 SG_ DAS_pp_offset_objectStateRight m49 : 19|3@1+ (1,0) [0|7] ""  X
 SG_ DAS_pp_laneChange_closeObstacle m48 : 19|1@1+ (1,0) [0|1] ""  X
 SG_ DAS_VL_LL_NAV_crossCheck m51 : 19|1@1+ (1,0) [0|1] ""  X
 SG_ DAS_Stop_Sign_detected m4 : 19|1@1+ (1,0) [0|1] ""  X
 SG_ DAS_LCM_override_brake_aeb m39 : 18|1@1+ (1,0) [0|1] ""  X
 SG_ DAS_ACC_tgt_cipv_camID m22 : 18|6@1+ (1,0) [0|63] ""  X
 SG_ DAS_pp_laneChange_anyObstacle m48 : 18|1@1+ (1,0) [0|1] ""  X
 SG_ DAS_ACC_Target6_camID m27 : 18|6@1+ (1,0) [0|63] ""  X
 SG_ DAS_ACC_radObstacleRelevant m20 : 18|1@1+ (1,0) [0|1] ""  X
 SG_ DAS_ACC_tgt_cutin_camID m26 : 18|6@1+ (1,0) [0|63] ""  X
 SG_ DAS_ACC_tgt_mcvl_camID m24 : 18|6@1+ (1,0) [0|63] ""  X
 SG_ DAS_LC_VirtualLaneWidth m40 : 18|8@1+ (0.025,0) [0|6.375] "m"  X
 SG_ DAS_VL_RL_quality m50 : 18|1@1+ (1,0) [0|1] ""  X
 SG_ DAS_ACC_tgt_mcvr_camID m25 : 18|6@1+ (1,0) [0|63] ""  X
 SG_ DAS_VL_LL_HPP_crossCheck m51 : 18|1@1+ (1,0) [0|1] ""  X
 SG_ DAS_ACC_tgt_cipv2_camID m23 : 18|6@1+ (1,0) [0|63] ""  X
 SG_ DAS_VL_LL_RL_crossCheck m51 : 17|1@1+ (1,0) [0|1] ""  X
 SG_ DAS_Planner_internalstate m46 : 17|4@1+ (1,0) [0|15] ""  X
 SG_ DAS_LCM_override_accelerator_aeb m39 : 17|1@1+ (1,0) [0|1] ""  X
 SG_ DAS_VL_LL_quality m50 : 17|1@1+ (1,0) [0|1] ""  X
 SG_ DAS_pp_laneChange_egoLaneValid m48 : 17|1@1+ (1,0) [0|1] ""  X
 SG_ DAS_FCM_state m33 : 16|8@1+ (1,0) [0|255] ""  X
 SG_ DAS_absoluteFrame m0 : 16|32@1+ (1,0) [0|4294967295] ""  X
 SG_ DAS_SCA_TWC_Left m45 : 16|8@1+ (0.01,0) [0|2.55] "s"  X
 SG_ DAS_freespaceLeftC1 m2 : 16|8@1+ (0.0016,-0.2) [-0.2|0.2] "rad"  X
 SG_ DAS_IDF_timeToCollision m36 : 16|8@1+ (10,0) [0|2550] "ms"  X
 SG_ DAS_SP_cMax m7 : 16|8@1+ (0.0025,-0.32) [-0.32|0.31] "1/m"  X
 SG_ DAS_VWall_Right_ultra_dist m44 : 16|9@1+ (0.01,0) [0|5.11] "m"  X
 SG_ DAS_LCM_CIPV_ay m38 : 16|8@1- (0.1,0.0) [-12.8|12.7] "m/s^2"  X
 SG_ DAS_pp_laneChange_destLanesValid m48 : 16|1@1+ (1,0) [0|1] ""  X
 SG_ DAS_autofixHorizon m1 : 16|8@1- (1,0) [-128|127] ""  X
 SG_ DAS_i2c_dev_data m12 : 16|8@1+ (1,0) [0|255] ""  X
 SG_ DAS_HmGeneralActivationCtr m41 : 16|7@1+ (1,0) [0|127] ""  X
 SG_ DAS_PMM_ussDistance m11 : 16|8@1+ (1,0) [0|255] "m"  X
 SG_ DAS_pp_offset_objectStateLeft m49 : 16|3@1+ (1,0) [0|7] ""  X
 SG_ DAS_csa_predictedLatAccel m47 : 16|8@1+ (0.08,-10.24) [-10.24|10] "m/s^2"  X
 SG_ DAS_VL_M_V5_crossCheck m51 : 16|1@1+ (1,0) [0|1] ""  X
 SG_ DAS_LCM_override_blinker m39 : 16|1@1+ (1,0) [0|1] ""  X
 SG_ DAS_dbg_image_data m10 : 16|48@1+ (1,0) [0|281474976710655] ""  X
 SG_ DAS_VL_rightFsParallelRightLane m50 : 16|1@1+ (1,0) [0|1] ""  X
 SG_ DAS_ACC_camCIPVRadMatchConf m21 : 16|4@1+ (1,0) [0|15] ""  X
 SG_ DAS_IDF_checkEgoSpeed m36 : 15|1@1+ (1,0) [0|1] ""  X
 SG_ DAS_VL_M_V4_crossCheck m51 : 15|1@1+ (1,0) [0|1] ""  X
 SG_ DAS_SCA_egoMovingLeft m45 : 15|1@1+ (1,0) [0|1] ""  X
 SG_ DAS_VL_rightFsParallelLeftLane m50 : 15|1@1+ (1,0) [0|1] ""  X
 SG_ DAS_ACC_radCIPVStatus m20 : 15|3@1+ (1,0) [0|7] ""  X
 SG_ DAS_LCM_override_brake m39 : 15|1@1+ (1,0) [0|1] ""  X
 SG_ DAS_SCA_egoLeftOfCenter m45 : 14|1@1+ (1,0) [0|1] ""  X
 SG_ DAS_LCM_override_accelerator m39 : 14|1@1+ (1,0) [0|1] ""  X
 SG_ DAS_pp_lanechange_side m48 : 14|2@1+ (1,0) [0|3] ""  X
 SG_ DAS_IDF_checkBrakingAvoidance m36 : 14|1@1+ (1,0) [0|1] ""  X
 SG_ DAS_VL_leftFsParallelRightLane m50 : 14|1@1+ (1,0) [0|1] ""  X
 SG_ DAS_VL_M_V3_crossCheck m51 : 14|1@1+ (1,0) [0|1] ""  X
 SG_ DAS_VL_M_V2_crossCheck m51 : 13|1@1+ (1,0) [0|1] ""  X
 SG_ DAS_LCM_override_stw_rate m39 : 13|1@1+ (1,0) [0|1] ""  X
 SG_ DAS_SCA_egoRightOfCenter m45 : 13|1@1+ (1,0) [0|1] ""  X
 SG_ DAS_IDF_checkSteeringAvoidance m36 : 13|1@1+ (1,0) [0|1] ""  X
 SG_ DAS_pp_lanechange_inputsValid m48 : 13|1@1+ (1,0) [0|1] ""  X
 SG_ DAS_VL_leftFsParallelLeftLane m50 : 13|1@1+ (1,0) [0|1] ""  X
 SG_ DAS_ACC_camCIPVStatus m20 : 12|3@1+ (1,0) [0|7] ""  X
 SG_ DAS_SCA_angleActive m45 : 12|1@1+ (1,0) [0|1] ""  X
 SG_ DAS_IDF_checkTargetProbability m36 : 12|1@1+ (1,0) [0|1] ""  X
 SG_ DAS_LCM_override_stw_angle m39 : 12|1@1+ (1,0) [0|1] ""  X
 SG_ DAS_VL_M_V1_crossCheck m51 : 12|1@1+ (1,0) [0|1] ""  X
 SG_ DAS_pp_lanechange_fwdObst m48 : 12|1@1+ (1,0) [0|1] ""  X
 SG_ DAS_SP_distance m6 : 12|12@1+ (1,0) [0|4095] "cm"  X
 SG_ DAS_ACC_Control_sl_d m28 : 12|10@1+ (0.2,0) [0|204.6] "m"  X
 SG_ DAS_ACC_Restrict_sl_d m29 : 12|10@1+ (0.2,0) [0|204.6] "m"  X
 SG_ DAS_calType m1 : 12|4@1+ (1,0) [0|15] ""  X
 SG_ DAS_IDF_checkTimeToCollision m36 : 11|1@1+ (1,0) [0|1] ""  X
 SG_ DAS_VL_M_NAV_crossCheck m51 : 11|1@1+ (1,0) [0|1] ""  X
 SG_ DAS_VL_exitChecks_BLINKER_RGHT m52 : 11|1@1+ (1,0) [0|1] ""  X
 SG_ DAS_VL_M_HPP_crossCheck m51 : 10|1@1+ (1,0) [0|1] ""  X
 SG_ DAS_IDF_checkOverlap m36 : 10|1@1+ (1,0) [0|1] ""  X
 SG_ DAS_FCM_TA_collisionOverlap m33 : 10|6@1+ (0.1,0) [0|6.3] "m"  X
 SG_ DAS_VL_exitChecks_BLINKER_LEFT m52 : 10|1@1+ (1,0) [0|1] ""  X
 SG_ DAS_IDF_checkClass m36 : 9|1@1+ (1,0) [0|1] ""  X
 SG_ DAS_VL_M_RL_crossCheck m51 : 9|1@1+ (1,0) [0|1] ""  X
 SG_ DAS_VL_exitChecks_EGO_LNE_RGHT m52 : 9|1@1+ (1,0) [0|1] ""  X
 SG_ DAS_VWall_Right_type m44 : 8|3@1+ (1,0) [0|7] ""  X
 SG_ DAS_freespaceLeftC0 m2 : 8|8@1+ (0.1,-12.8) [-12.8|12.7] "m"  X
 SG_ DAS_SYNC_EyeQGlobalFrameNum m100 : 15|32@0+ (1,0) [0|4294967295] ""  X
 SG_ DAS_VWall_Left_ultra_dist m43 : 8|9@1+ (0.01,0) [0|5.11] "m"  X
 SG_ DAS_ACC_tgt_cipv_dist m22 : 8|10@1+ (0.2,0) [0|204.6] "m"  X
 SG_ DAS_FCM_TA_collisionStage m33 : 8|2@1+ (1,0) [0|3] ""  X
 SG_ DAS_IDF_checkSensors m36 : 8|1@1+ (1,0) [0|1] ""  X
 SG_ DAS_i2c_dev_reg m12 : 8|8@1+ (1,0) [0|255] ""  X
 SG_ DAS_ACC_intState m20 : 8|4@1+ (1,0) [0|11] ""  X
 SG_ DAS_LCM_CIPV_dx m37 : 8|12@1+ (0.0625,0) [0|255.9375] "m"  X
 SG_ DAS_ACC_Control_targetID m28 : 8|4@1+ (1,0) [0|15] ""  X
 SG_ DAS_Stop_Sign_dist m4 : 8|11@1+ (0.1,-50) [-50|102.3] "m"  X
 SG_ DAS_VL_HPP_rejectCounter m50 : 8|1@1+ (1,0) [0|1] ""  X
 SG_ DAS_csa_internal_state m48 : 8|4@1+ (1,0) [0|15] ""  X
 SG_ DAS_ACC_Restrict_targetID m29 : 8|4@1+ (1,0) [0|15] ""  X
 SG_ DAS_FCM_SL_distance m32 : 8|12@1+ (0.0625,0) [0|255.9375] "m"  X
 SG_ DAS_autofixStatus m1 : 8|2@1+ (1,0) [0|3] ""  X
 SG_ DAS_SP_vehPosX m8 : 8|12@1+ (0.01,-20.48) [-20.48|20.48] "m"  X
 SG_ DAS_dbg_msg_count m10 : 8|8@1+ (1,0) [0|255] ""  X
 SG_ DAS_eyeQMode m0 : 8|8@1+ (1,0) [0|255] ""  X
 SG_ DAS_LC_SteeringOffsetEstimate m42 : 8|8@1- (0.1,0.0) [-12.8|12.7] "deg"  X
 SG_ DAS_PMM_ussConfidence m11 : 8|8@1+ (1,0) [0|255] ""  X
 SG_ DAS_VL_exitChecks_EGO_LNE_LEFT m52 : 8|1@1+ (1,0) [0|1] ""  X
 SG_ DAS_csa_accel_max m47 : 8|8@1+ (0.08,-10.24) [-10.24|10] "m/s^2"  X
 SG_ DAS_VL_M_LL_crossCheck m51 : 8|1@1+ (1,0) [0|1] ""  X
 SG_ DAS_highestSeqRcvd m3 : 8|12@1+ (1,0) [0|4095] ""  X
 SG_ DAS_ACC_camCIPVRadObjID m21 : 8|8@1+ (1,0) [0|255] ""  X
 SG_ DAS_LCM_CIPV_ax m38 : 8|8@1- (0.1,0.0) [-12.8|12.7] "m/s^2"  X
 SG_ DAS_ACC_tgt_mcvl_dist m24 : 8|10@1+ (0.2,0) [0|204.6] "m"  X
 SG_ DAS_FCM_CIPV_distance m30 : 8|12@1+ (0.0625,0) [0|255.9375] "m"  X
 SG_ DAS_LCM_driver_reaction_time m39 : 8|4@1+ (0.1,0.8) [0.8|2.3] "s"  X
 SG_ DAS_Planner_viewRange m46 : 8|9@1+ (0.5,0) [0|255.5] "m"  X
 SG_ DAS_SP_sprecordX m9 : 8|12@1+ (0.01,-20.48) [-20.48|20.48] "m"  X
 SG_ DAS_ACC_tgt_mcvr_dist m25 : 8|10@1+ (0.2,0) [0|204.6] "m"  X
 SG_ DAS_SCA_state m45 : 8|4@1+ (1,0) [0|15] ""  X
 SG_ DAS_tbt_filtered m5 : 8|12@1+ (0.01,-20.5) [-20.5|20.45] "Nm"  X
 SG_ DAS_ACC_Target6_dist m27 : 8|10@1+ (0.2,0) [0|204.6] "m"  X
 SG_ DAS_FCM_DBG_cam_dist m35 : 8|12@1+ (0.0625,0) [0|255.9375] "m"  X
 SG_ DAS_autoWipersNetwork m60 : 8|16@1+ (0.01,0) [0|1] "probability"  X
 SG_ DAS_HmViewRangeActivationCtr m41 : 8|7@1+ (1,0) [0|127] ""  X
 SG_ DAS_apcIntState m6 : 8|4@1+ (1,0) [0|15] ""  X
 SG_ DAS_ACC_tgt_cutin_dist m26 : 8|10@1+ (0.2,0) [0|204.6] "m"  X
 SG_ DAS_SP_cMin m7 : 8|8@1+ (0.0025,-0.32) [-0.32|0.31] "1/m"  X
 SG_ DAS_ACC_tgt_cipv2_dist m23 : 8|10@1+ (0.2,0) [0|204.6] "m"  X
 SG_ DAS_FCM_MCP_distance m31 : 8|12@1+ (0.0625,0) [0|255.9375] "m"  X
 SG_ DAS_LC_VirtualLaneViewRange m40 : 8|10@1+ (0.5,0) [0|511.5] "m"  X
 SG_ DAS_debugMultiplexer M : 0|8@1+ (1,0) [0|100] ""  X

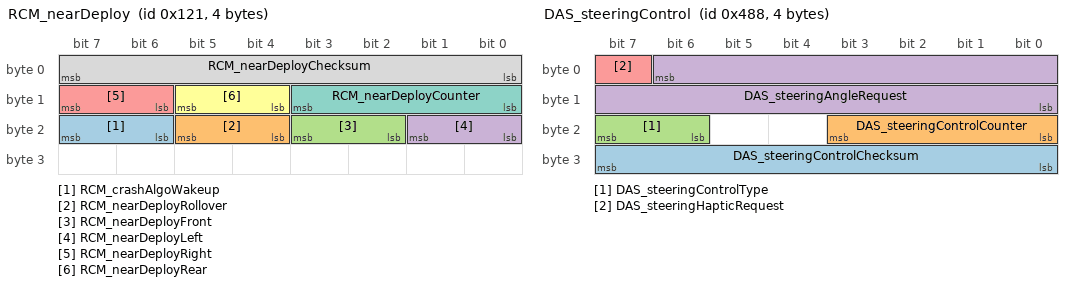
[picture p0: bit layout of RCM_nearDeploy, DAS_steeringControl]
BO_ 289 RCM_nearDeploy: 4 CH
 SG_ RCM_crashAlgoWakeup : 22|2@1+ (1,0) [0|3] ""  gtw
 SG_ RCM_nearDeployRollover : 20|2@1+ (1,0) [0|3] ""  das
 SG_ RCM_nearDeployFront : 18|2@1+ (1,0) [0|3] ""  das
 SG_ RCM_nearDeployLeft : 16|2@1+ (1,0) [0|3] ""  das
 SG_ RCM_nearDeployRight : 14|2@1+ (1,0) [0|3] ""  das
 SG_ RCM_nearDeployRear : 12|2@1+ (1,0) [0|3] ""  das
 SG_ RCM_nearDeployCounter : 8|4@1+ (1,0) [0|15] ""  gtw
 SG_ RCM_nearDeployChecksum : 0|8@1+ (1,0) [0|255] ""  gtw

BO_ 1293 TAS_alertLog: 8 CH
 SG_ TAS_a107_UsageNVMMTask m107 : 56|8@1+ (1,0) [0|255] ""  gtw
 SG_ TAS_a106_CPULoadNVMMTask m106 : 56|8@1+ (1,0) [0|255] ""  gtw
 SG_ TAS_a022_TaskInitError4 m22 : 56|8@1+ (1,0) [0|255] ""  gtw
 SG_ TAS_a031_PWMfaultFR m31 : 48|3@1+ (1,0) [0|6] ""  gtw
 SG_ TAS_a038_PWMfaultFL m38 : 48|3@1+ (1,0) [0|6] ""  gtw
 SG_ TAS_a229_PWMfaultRR m229 : 48|3@1+ (1,0) [0|6] ""  gtw
 SG_ TAS_a032_PWMfaultRL m32 : 48|3@1+ (1,0) [0|6] ""  gtw
 SG_ TAS_a033_PWMfaultRR m33 : 48|3@1+ (1,0) [0|6] ""  gtw
 SG_ TAS_a039_PWMfaultFR m39 : 48|3@1+ (1,0) [0|6] ""  gtw
 SG_ TAS_a228_PWMfaultRL m228 : 48|3@1+ (1,0) [0|6] ""  gtw
 SG_ TAS_a030_PWMfaultFL m30 : 48|3@1+ (1,0) [0|6] ""  gtw
 SG_ TAS_a037_PWMfaultRR m37 : 48|3@1+ (1,0) [0|6] ""  gtw
 SG_ TAS_a107_UsageUDSTask m107 : 48|8@1+ (1,0) [0|255] ""  gtw
 SG_ TAS_a022_TaskInitError3 m22 : 48|8@1+ (1,0) [0|255] ""  gtw
 SG_ TAS_a226_PWMfaultFL m226 : 48|3@1+ (1,0) [0|6] ""  gtw
 SG_ TAS_a013_signalX3 m13 : 48|16@1+ (1,0) [0|65535] ""  gtw
 SG_ TAS_a035_PWMfaultFR m35 : 48|3@1+ (1,0) [0|6] ""  gtw
 SG_ TAS_a040_PWMfaultRL m40 : 48|3@1+ (1,0) [0|6] ""  gtw
 SG_ TAS_a106_CPULoad1000msTask m106 : 48|8@1+ (1,0) [0|255] ""  gtw
 SG_ TAS_a034_PWMfaultFL m34 : 48|3@1+ (1,0) [0|6] ""  gtw
 SG_ TAS_a041_PWMfaultRR m41 : 48|3@1+ (1,0) [0|6] ""  gtw
 SG_ TAS_a000_alertDataW2 m0 : 48|16@1+ (1,0) [0|65535] ""  X
 SG_ TAS_a036_PWMfaultRL m36 : 48|3@1+ (1,0) [0|6] ""  gtw
 SG_ TAS_a227_PWMfaultFR m227 : 48|3@1+ (1,0) [0|6] ""  gtw
 SG_ TAS_a160_valveCurrent m160 : 40|16@1+ (0.001,0) [0|32] "A"  gtw
 SG_ TAS_a142_valveCurrent m142 : 40|16@1+ (0.001,0) [0|32] "A"  gtw
 SG_ TAS_a107_Usage1000msTask m107 : 40|8@1+ (1,0) [0|255] ""  gtw
 SG_ TAS_a145_valveCurrent m145 : 40|16@1+ (0.001,0) [0|32] "A"  gtw
 SG_ TAS_a151_valveCurrent m151 : 40|16@1+ (0.001,0) [0|32] "A"  gtw
 SG_ TAS_a148_valveCurrent m148 : 40|16@1+ (0.001,0) [0|32] "A"  gtw
 SG_ TAS_a137_valveCurrent m137 : 40|16@1+ (0.001,0) [0|32] "A"  gtw
 SG_ TAS_a152_valveCurrent m152 : 40|16@1+ (0.001,0) [0|32] "A"  gtw
 SG_ TAS_a134_valveCurrent m134 : 40|16@1+ (0.001,0) [0|32] "A"  gtw
 SG_ TAS_a157_valveCurrent m157 : 40|16@1+ (0.001,0) [0|32] "A"  gtw
 SG_ TAS_a131_valveCurrent m131 : 40|16@1+ (0.001,0) [0|32] "A"  gtw
 SG_ TAS_a141_valveCurrent m141 : 40|16@1+ (0.001,0) [0|32] "A"  gtw
 SG_ TAS_a158_valveCurrent m158 : 40|16@1+ (0.001,0) [0|32] "A"  gtw
 SG_ TAS_a106_CPULoad100msTask m106 : 40|8@1+ (1,0) [0|255] ""  gtw
 SG_ TAS_a144_valveCurrent m144 : 40|16@1+ (0.001,0) [0|32] "A"  gtw
 SG_ TAS_a147_valveCurrent m147 : 40|16@1+ (0.001,0) [0|32] "A"  gtw
 SG_ TAS_a138_valveCurrent m138 : 40|16@1+ (0.001,0) [0|32] "A"  gtw
 SG_ TAS_a135_valveCurrent m135 : 40|16@1+ (0.001,0) [0|32] "A"  gtw
 SG_ TAS_a153_valveCurrent m153 : 40|16@1+ (0.001,0) [0|32] "A"  gtw
 SG_ TAS_a132_valveCurrent m132 : 40|16@1+ (0.001,0) [0|32] "A"  gtw
 SG_ TAS_a154_valveCurrent m154 : 40|16@1+ (0.001,0) [0|32] "A"  gtw
 SG_ TAS_a140_valveCurrent m140 : 40|16@1+ (0.001,0) [0|32] "A"  gtw
 SG_ TAS_a159_valveCurrent m159 : 40|16@1+ (0.001,0) [0|32] "A"  gtw
 SG_ TAS_a143_valveCurrent m143 : 40|16@1+ (0.001,0) [0|32] "A"  gtw
 SG_ TAS_a146_valveCurrent m146 : 40|16@1+ (0.001,0) [0|32] "A"  gtw
 SG_ TAS_a139_valveCurrent m139 : 40|16@1+ (0.001,0) [0|32] "A"  gtw
 SG_ TAS_a210_heightSensorDeltaRR m210 : 40|8@1+ (1,-128) [-128|127] "mm"  gtw
 SG_ TAS_a022_TaskInitError2 m22 : 40|8@1+ (1,0) [0|255] ""  gtw
 SG_ TAS_a150_valveCurrent m150 : 40|16@1+ (0.001,0) [0|32] "A"  gtw
 SG_ TAS_a149_valveCurrent m149 : 40|16@1+ (0.001,0) [0|32] "A"  gtw
 SG_ TAS_a136_valveCurrent m136 : 40|16@1+ (0.001,0) [0|32] "A"  gtw
 SG_ TAS_a133_valveCurrent m133 : 40|16@1+ (0.001,0) [0|32] "A"  gtw
 SG_ TAS_a155_valveCurrent m155 : 40|16@1+ (0.001,0) [0|32] "A"  gtw
 SG_ TAS_a156_valveCurrent m156 : 40|16@1+ (0.001,0) [0|32] "A"  gtw
 SG_ TAS_a130_valveCurrent m130 : 40|16@1+ (0.001,0) [0|32] "A"  gtw
 SG_ TAS_a129_valveCurrent m129 : 40|16@1+ (0.001,0) [0|32] "A"  gtw
 SG_ TAS_a123_12VtoValve m123 : 32|16@1+ (0.001,0) [0|32] "V"  gtw
 SG_ TAS_a022_TaskInitError1 m22 : 32|8@1+ (1,0) [0|255] ""  gtw
 SG_ TAS_a032_PWMfrequencyRL m32 : 32|16@1+ (0.025,0) [0|1000] "Hz"  gtw
 SG_ TAS_a124_12VtoValve m124 : 32|16@1+ (0.001,0) [0|32] "V"  gtw
 SG_ TAS_a210_heightSensorDeltaRL m210 : 32|8@1+ (1,-128) [-128|127] "mm"  gtw
 SG_ TAS_a035_PWMfrequencyFR m35 : 32|16@1+ (0.025,0) [0|1000] "Hz"  gtw
 SG_ TAS_a040_PWMfrequencyRL m40 : 32|16@1+ (0.025,0) [0|1000] "Hz"  gtw
 SG_ TAS_a229_PWMfrequencyRR m229 : 32|16@1+ (0.025,0) [0|1000] "%"  gtw
 SG_ TAS_a038_PWMfrequencyFL m38 : 32|16@1+ (0.025,0) [0|1000] "Hz"  gtw
 SG_ TAS_a037_PWMfrequencyRR m37 : 32|16@1+ (0.025,0) [0|1000] "Hz"  gtw
 SG_ TAS_a226_PWMfrequencyFL m226 : 32|16@1+ (0.025,0) [0|1000] "%"  gtw
 SG_ TAS_a227_PWMfrequencyFR m227 : 32|16@1+ (0.025,0) [0|1000] "%"  gtw
 SG_ TAS_a036_PWMfrequencyRL m36 : 32|16@1+ (0.025,0) [0|1000] "Hz"  gtw
 SG_ TAS_a039_PWMfrequencyFR m39 : 32|16@1+ (0.025,0) [0|1000] "Hz"  gtw
 SG_ TAS_a000_alertDataW1 m0 : 32|16@1+ (1,0) [0|65535] ""  X
 SG_ TAS_a228_PWMfrequencyRL m228 : 32|16@1+ (0.025,0) [0|1000] "%"  gtw
 SG_ TAS_a125_12VtoValve m125 : 32|16@1+ (0.001,0) [0|32] "V"  gtw
 SG_ TAS_a034_PWMfrequencyFL m34 : 32|16@1+ (0.025,0) [0|1000] "Hz"  gtw
 SG_ TAS_a041_PWMfrequencyRR m41 : 32|16@1+ (0.025,0) [0|1000] "Hz"  gtw
 SG_ TAS_a126_12VtoValve m126 : 32|16@1+ (0.001,0) [0|32] "V"  gtw
 SG_ TAS_a013_signalX2 m13 : 32|16@1+ (1,0) [0|65535] ""  gtw
 SG_ TAS_a033_PWMfrequencyRR m33 : 32|16@1+ (0.025,0) [0|1000] "Hz"  gtw
 SG_ TAS_a107_Usage100msTask m107 : 32|8@1+ (1,0) [0|255] ""  gtw
 SG_ TAS_a121_12VtoValve m121 : 32|16@1+ (0.001,0) [0|32] "V"  gtw
 SG_ TAS_a030_PWMfrequencyFL m30 : 32|16@1+ (0.025,0) [0|1000] "Hz"  gtw
 SG_ TAS_a122_12VtoValve m122 : 32|16@1+ (0.001,0) [0|32] "V"  gtw
 SG_ TAS_a078_sensorRefVoltage m78 : 32|16@1+ (0.001,0) [0|32] "V"  gtw
 SG_ TAS_a127_12VtoValve m127 : 32|16@1+ (0.001,0) [0|32] "V"  gtw
 SG_ TAS_a077_sensorRefVoltage m77 : 32|16@1+ (0.001,0) [0|32] "V"  gtw
 SG_ TAS_a106_CPULoad10msTask m106 : 32|8@1+ (1,0) [0|255] ""  gtw
 SG_ TAS_a128_12VtoValve m128 : 32|16@1+ (0.001,0) [0|32] "V"  gtw
 SG_ TAS_a031_PWMfrequencyFR m31 : 32|16@1+ (0.025,0) [0|1000] "Hz"  gtw
 SG_ TAS_a223_valveOnReservoir m223 : 28|1@1+ (1,0) [0|1] ""  gtw
 SG_ TAS_a224_valveOnReservoir m224 : 28|1@1+ (1,0) [0|1] ""  gtw
 SG_ TAS_a223_valveOnRR m223 : 27|1@1+ (1,0) [0|1] ""  gtw
 SG_ TAS_a224_valveOnRR m224 : 27|1@1+ (1,0) [0|1] ""  gtw
 SG_ TAS_a021_Task1000msMissed m21 : 27|1@1+ (1,0) [0|1] ""  gtw
 SG_ TAS_a223_valveOnRL m223 : 26|1@1+ (1,0) [0|1] ""  gtw
 SG_ TAS_a021_Task1000msStarved m21 : 26|1@1+ (1,0) [0|1] ""  gtw
 SG_ TAS_a224_valveOnRL m224 : 26|1@1+ (1,0) [0|1] ""  gtw
 SG_ TAS_a224_valveOnFR m224 : 25|1@1+ (1,0) [0|1] ""  gtw
 SG_ TAS_a223_valveOnFR m223 : 25|1@1+ (1,0) [0|1] ""  gtw
 SG_ TAS_a021_Task1000msLate m21 : 25|1@1+ (1,0) [0|1] ""  gtw
 SG_ TAS_a121_ambientTemperature m121 : 24|8@1+ (1,-40) [-40|215] "degC"  gtw
 SG_ TAS_a149_valveVoltage m149 : 24|16@1+ (0.001,0) [0|32] "V"  gtw
 SG_ TAS_a136_valveVoltage m136 : 24|16@1+ (0.001,0) [0|32] "V"  gtw
 SG_ TAS_a210_heightSensorDeltaFR m210 : 24|8@1+ (1,-128) [-128|127] "mm"  gtw
 SG_ TAS_a150_valveVoltage m150 : 24|16@1+ (0.001,0) [0|32] "V"  gtw
 SG_ TAS_a157_valveVoltage m157 : 24|16@1+ (0.001,0) [0|32] "V"  gtw
 SG_ TAS_a131_valveVoltage m131 : 24|16@1+ (0.001,0) [0|32] "V"  gtw
 SG_ TAS_a107_Usage10msTask m107 : 24|8@1+ (1,0) [0|255] ""  gtw
 SG_ TAS_a126_ambientTemperature m126 : 24|8@1+ (1,-40) [-40|215] "degC"  gtw
 SG_ TAS_a143_valveVoltage m143 : 24|16@1+ (0.001,0) [0|32] "V"  gtw
 SG_ TAS_a022_TaskInitError0 m22 : 24|8@1+ (1,0) [0|255] ""  gtw
 SG_ TAS_a224_valveOnFL m224 : 24|1@1+ (1,0) [0|1] ""  gtw
 SG_ TAS_a140_valveVoltage m140 : 24|16@1+ (0.001,0) [0|32] "V"  gtw
 SG_ TAS_a159_valveVoltage m159 : 24|16@1+ (0.001,0) [0|32] "V"  gtw
 SG_ TAS_a128_ambientTemperature m128 : 24|8@1+ (1,-40) [-40|215] "degC"  gtw
 SG_ TAS_a145_valveVoltage m145 : 24|16@1+ (0.001,0) [0|32] "V"  gtw
 SG_ TAS_a106_CPULoad1msTask m106 : 24|8@1+ (1,0) [0|255] ""  gtw
 SG_ TAS_a135_valveVoltage m135 : 24|16@1+ (0.001,0) [0|32] "V"  gtw
 SG_ TAS_a122_ambientTemperature m122 : 24|8@1+ (1,-40) [-40|215] "degC"  gtw
 SG_ TAS_a153_valveVoltage m153 : 24|16@1+ (0.001,0) [0|32] "V"  gtw
 SG_ TAS_a130_valveVoltage m130 : 24|16@1+ (0.001,0) [0|32] "V"  gtw
 SG_ TAS_a223_valveOnFL m223 : 24|1@1+ (1,0) [0|1] ""  gtw
 SG_ TAS_a129_valveVoltage m129 : 24|16@1+ (0.001,0) [0|32] "V"  gtw
 SG_ TAS_a156_valveVoltage m156 : 24|16@1+ (0.001,0) [0|32] "V"  gtw
 SG_ TAS_a127_ambientTemperature m127 : 24|8@1+ (1,-40) [-40|215] "degC"  gtw
 SG_ TAS_a133_valveVoltage m133 : 24|16@1+ (0.001,0) [0|32] "V"  gtw
 SG_ TAS_a124_ambientTemperature m124 : 24|8@1+ (1,-40) [-40|215] "degC"  gtw
 SG_ TAS_a155_valveVoltage m155 : 24|16@1+ (0.001,0) [0|32] "V"  gtw
 SG_ TAS_a158_valveVoltage m158 : 24|16@1+ (0.001,0) [0|32] "V"  gtw
 SG_ TAS_a141_valveVoltage m141 : 24|16@1+ (0.001,0) [0|32] "V"  gtw
 SG_ TAS_a146_valveVoltage m146 : 24|16@1+ (0.001,0) [0|32] "V"  gtw
 SG_ TAS_a139_valveVoltage m139 : 24|16@1+ (0.001,0) [0|32] "V"  gtw
 SG_ TAS_a021_Task100msMissed m21 : 24|1@1+ (1,0) [0|1] ""  gtw
 SG_ TAS_a134_valveVoltage m134 : 24|16@1+ (0.001,0) [0|32] "V"  gtw
 SG_ TAS_a152_valveVoltage m152 : 24|16@1+ (0.001,0) [0|32] "V"  gtw
 SG_ TAS_a123_ambientTemperature m123 : 24|8@1+ (1,-40) [-40|215] "degC"  gtw
 SG_ TAS_a137_valveVoltage m137 : 24|16@1+ (0.001,0) [0|32] "V"  gtw
 SG_ TAS_a148_valveVoltage m148 : 24|16@1+ (0.001,0) [0|32] "V"  gtw
 SG_ TAS_a151_valveVoltage m151 : 24|16@1+ (0.001,0) [0|32] "V"  gtw
 SG_ TAS_a221_timeInIdle m221 : 24|32@1+ (1,0) [0|4294967295] ""  gtw
 SG_ TAS_a154_valveVoltage m154 : 24|16@1+ (0.001,0) [0|32] "V"  gtw
 SG_ TAS_a125_ambientTemperature m125 : 24|8@1+ (1,-40) [-40|215] "degC"  gtw
 SG_ TAS_a025_lastCrashEvent m25 : 24|32@1+ (1,0) [0|4294967295] ""  gtw
 SG_ TAS_a132_valveVoltage m132 : 24|16@1+ (0.001,0) [0|32] "V"  gtw
 SG_ TAS_a160_valveVoltage m160 : 24|16@1+ (0.001,0) [0|32] "V"  gtw
 SG_ TAS_a142_valveVoltage m142 : 24|16@1+ (0.001,0) [0|32] "V"  gtw
 SG_ TAS_a147_valveVoltage m147 : 24|16@1+ (0.001,0) [0|32] "V"  gtw
 SG_ TAS_a138_valveVoltage m138 : 24|16@1+ (0.001,0) [0|32] "V"  gtw
 SG_ TAS_a144_valveVoltage m144 : 24|16@1+ (0.001,0) [0|32] "V"  gtw
 SG_ TAS_a164_calibrationVersion m164 : 24|8@1+ (1,0) [0|255] ""  gtw
 SG_ TAS_a021_Task100msStarved m21 : 23|1@1+ (1,0) [0|1] ""  gtw
 SG_ TAS_a021_Task100msLate m21 : 22|1@1+ (1,0) [0|1] ""  gtw
 SG_ TAS_a012_ExternalReset m12 : 21|1@1+ (1,0) [0|1] ""  gtw
 SG_ TAS_a021_Task10msMissed m21 : 21|1@1+ (1,0) [0|1] ""  gtw
 SG_ TAS_a015_NVMMWriteFailed m15 : 21|1@1+ (1,0) [0|1] ""  gtw
 SG_ TAS_a012_DebugReset m12 : 20|1@1+ (1,0) [0|1] ""  gtw
 SG_ TAS_a098_VCFRONT_systemStatus_MI m98 : 20|1@1+ (1,0) [0|1] ""  gtw
 SG_ TAS_a021_Task10msStarved m21 : 20|1@1+ (1,0) [0|1] ""  gtw
 SG_ TAS_a015_NVMMMemOverflow m15 : 20|1@1+ (1,0) [0|1] ""  gtw
 SG_ TAS_a098_VCFRONT_status_MIA m98 : 19|1@1+ (1,0) [0|1] ""  gtw
 SG_ TAS_a021_Task10msLate m21 : 19|1@1+ (1,0) [0|1] ""  gtw
 SG_ TAS_a015_NVMMRecordUpgraded m15 : 19|1@1+ (1,0) [0|1] ""  gtw
 SG_ TAS_a012_CheckstopReset m12 : 19|1@1+ (1,0) [0|1] ""  gtw
 SG_ TAS_a014_BridgeSPIError m14 : 19|1@1+ (1,0) [0|1] ""  gtw
 SG_ TAS_a012_SoftwareReset m12 : 18|1@1+ (1,0) [0|1] ""  gtw
 SG_ TAS_a015_NVMMVersionMismatch m15 : 18|1@1+ (1,0) [0|1] ""  gtw
 SG_ TAS_a098_VCFRONT_sensors_MIA m98 : 18|1@1+ (1,0) [0|1] ""  gtw
 SG_ TAS_a025_appCrashIsActive m25 : 18|1@1+ (1,0) [0|1] ""  gtw
 SG_ TAS_a014_BridgeInitChannel m14 : 18|1@1+ (1,0) [0|1] ""  gtw
 SG_ TAS_a021_Task1msMissed m21 : 18|1@1+ (1,0) [0|1] ""  gtw
 SG_ TAS_a079_GTW m79 : 18|2@1+ (1,0) [0|2] ""  gtw
 SG_ TAS_a025_CANCrashIsActive m25 : 17|1@1+ (1,0) [0|1] ""  gtw
 SG_ TAS_a002_PowerOnReset m2 : 17|1@1+ (1,0) [0|1] ""  gtw
 SG_ TAS_a015_NVMMCRCMismatch m15 : 17|1@1+ (1,0) [0|1] ""  gtw
 SG_ TAS_a014_BridgeInitSPIDev m14 : 17|1@1+ (1,0) [0|1] ""  gtw
 SG_ TAS_a093_IVOR2Exception m93 : 17|1@1+ (1,0) [0|1] ""  gtw
 SG_ TAS_a098_VCFRONT_okToUseHighPowe m98 : 17|1@1+ (1,0) [0|1] ""  gtw
 SG_ TAS_a103_GTW_chNm_MIA m103 : 17|1@1+ (1,0) [0|1] ""  gtw
 SG_ TAS_a021_Task1msStarved m21 : 17|1@1+ (1,0) [0|1] ""  gtw
 SG_ TAS_a102_DI_systemStatus_MIA m102 : 17|1@1+ (1,0) [0|1] ""  gtw
 SG_ TAS_a012_FlashError m12 : 17|1@1+ (1,0) [0|1] ""  gtw
 SG_ TAS_a075_voltage5VOffBoard m75 : 16|16@1+ (0.001,0) [0|32] "V"  gtw
 SG_ TAS_a141_valveFaultType m141 : 16|3@1+ (1,0) [0|7] ""  gtw
 SG_ TAS_a223_galleryPressure m223 : 16|8@1+ (0.1,0) [0|25.5] "bar"  gtw
 SG_ TAS_a002_CPUUndervoltage m2 : 16|1@1+ (1,0) [0|1] ""  gtw
 SG_ TAS_a033_PWMdutyCycleRR m33 : 16|16@1+ (0.0025,0) [0|100] "%"  gtw
 SG_ TAS_a158_valveFaultType m158 : 16|3@1+ (1,0) [0|7] ""  gtw
 SG_ TAS_a073_voltage5VOnBoard m73 : 16|16@1+ (0.001,0) [0|32] "V"  gtw
 SG_ TAS_a164_valveFaultType m164 : 16|3@1+ (1,0) [0|7] ""  gtw
 SG_ TAS_a139_valveFaultType m139 : 16|3@1+ (1,0) [0|7] ""  gtw
 SG_ TAS_a146_valveFaultType m146 : 16|3@1+ (1,0) [0|7] ""  gtw
 SG_ TAS_a102_DI_speed_MIA m102 : 16|1@1+ (1,0) [0|1] ""  gtw
 SG_ TAS_a152_valveFaultType m152 : 16|3@1+ (1,0) [0|7] ""  gtw
 SG_ TAS_a221_galleryPressureDelta m221 : 16|8@1+ (0.1,0) [0|25.5] "bar"  gtw
 SG_ TAS_a022_TaskInitErrorCount m22 : 16|8@1+ (1,0) [0|255] ""  gtw
 SG_ TAS_a291_frontAxleHeight m291 : 16|8@1+ (1,-128) [-128|127] "mm"  gtw
 SG_ TAS_a134_valveFaultType m134 : 16|3@1+ (1,0) [0|7] ""  gtw
 SG_ TAS_a121_dutyCycleFL m121 : 16|8@1+ (1,0) [0|100] "%"  gtw
 SG_ TAS_a077_sensorVoltage m77 : 16|16@1+ (0.001,0) [0|32] "V"  gtw
 SG_ TAS_a151_valveFaultType m151 : 16|3@1+ (1,0) [0|7] ""  gtw
 SG_ TAS_a030_PWMdutyCycleFL m30 : 16|16@1+ (0.0025,0) [0|100] "%"  gtw
 SG_ TAS_a126_dutyCycleExhaust m126 : 16|8@1+ (1,0) [0|100] "%"  gtw
 SG_ TAS_a222_galleryPressureDelta m222 : 16|8@1+ (0.1,0) [0|25.5] "bar"  gtw
 SG_ TAS_a074_voltage5VOffBoard m74 : 16|16@1+ (0.001,0) [0|32] "V"  gtw
 SG_ TAS_a148_valveFaultType m148 : 16|3@1+ (1,0) [0|7] ""  gtw
 SG_ TAS_a137_valveFaultType m137 : 16|3@1+ (1,0) [0|7] ""  gtw
 SG_ TAS_a123_dutyCycleRL m123 : 16|8@1+ (1,0) [0|100] "%"  gtw
 SG_ TAS_a132_valveFaultType m132 : 16|3@1+ (1,0) [0|7] ""  gtw
 SG_ TAS_a015_NVMMRecordNotFound m15 : 16|1@1+ (1,0) [0|1] ""  gtw
 SG_ TAS_a098_VCFRONT_LVPowerState_MI m98 : 16|1@1+ (1,0) [0|1] ""  gtw
 SG_ TAS_a154_valveFaultType m154 : 16|3@1+ (1,0) [0|7] ""  gtw
 SG_ TAS_a106_CPULoadTotal m106 : 16|8@1+ (1,0) [0|255] ""  gtw
 SG_ TAS_a127_dutyCycleBoost m127 : 16|8@1+ (1,0) [0|100] "%"  gtw
 SG_ TAS_a013_signalX1 m13 : 16|16@1+ (1,0) [0|65535] ""  gtw
 SG_ TAS_a160_valveFaultType m160 : 16|3@1+ (1,0) [0|7] ""  gtw
 SG_ TAS_a142_valveFaultType m142 : 16|3@1+ (1,0) [0|7] ""  gtw
 SG_ TAS_a290_twistLevel m290 : 16|8@1+ (1,-128) [-128|127] "mm"  gtw
 SG_ TAS_a147_valveFaultType m147 : 16|3@1+ (1,0) [0|7] ""  gtw
 SG_ TAS_a031_PWMdutyCycleFR m31 : 16|16@1+ (0.0025,0) [0|100] "%"  gtw
 SG_ TAS_a138_valveFaultType m138 : 16|3@1+ (1,0) [0|7] ""  gtw
 SG_ TAS_a295_targetHeight m295 : 16|8@1+ (1,-128) [-128|127] "mm"  gtw
 SG_ TAS_a225_galleryPressure m225 : 16|8@1+ (0.1,0) [0|25.5] "bar"  gtw
 SG_ TAS_a014_BridgeInitInvldCfg m14 : 16|1@1+ (1,0) [0|1] ""  gtw
 SG_ TAS_a144_valveFaultType m144 : 16|3@1+ (1,0) [0|7] ""  gtw
 SG_ TAS_a012_ClockError m12 : 16|1@1+ (1,0) [0|1] ""  gtw
 SG_ TAS_a293_frontAxleHeight m293 : 16|8@1+ (1,-128) [-128|127] "mm"  gtw
 SG_ TAS_a099_UI_chassisControl_MIA m99 : 16|1@1+ (1,0) [0|1] ""  gtw
 SG_ TAS_a150_valveFaultType m150 : 16|3@1+ (1,0) [0|7] ""  gtw
 SG_ TAS_a149_valveFaultType m149 : 16|3@1+ (1,0) [0|7] ""  gtw
 SG_ TAS_a136_valveFaultType m136 : 16|3@1+ (1,0) [0|7] ""  gtw
 SG_ TAS_a032_PWMdutyCycleRL m32 : 16|16@1+ (0.0025,0) [0|100] "%"  gtw
 SG_ TAS_a131_valveFaultType m131 : 16|3@1+ (1,0) [0|7] ""  gtw
 SG_ TAS_a071_voltage12V m71 : 16|16@1+ (0.001,0) [0|32] "V"  gtw
 SG_ TAS_a122_dutyCycleFR m122 : 16|8@1+ (1,0) [0|100] "%"  gtw
 SG_ TAS_a107_Usage1msTask m107 : 16|8@1+ (1,0) [0|255] ""  gtw
 SG_ TAS_a224_galleryPressure m224 : 16|8@1+ (0.1,0) [0|25.5] "bar"  gtw
 SG_ TAS_a157_valveFaultType m157 : 16|3@1+ (1,0) [0|7] ""  gtw
 SG_ TAS_a000_alertDataW0 m0 : 16|16@1+ (1,0) [0|65535] ""  X
 SG_ TAS_a143_valveFaultType m143 : 16|3@1+ (1,0) [0|7] ""  gtw
 SG_ TAS_a128_dutyCycleCompressor m128 : 16|8@1+ (1,0) [0|100] "%"  gtw
 SG_ TAS_a103_GTW_carState_MIA m103 : 16|1@1+ (1,0) [0|1] ""  gtw
 SG_ TAS_a040_PWMdutyCycleRL m40 : 16|16@1+ (0.0025,0) [0|100] "%"  gtw
 SG_ TAS_a035_PWMdutyCycleFR m35 : 16|16@1+ (0.0025,0) [0|100] "%"  gtw
 SG_ TAS_a101_ESP_wheelRotation_MIA m101 : 16|1@1+ (1,0) [0|1] ""  gtw
 SG_ TAS_a294_rearAxleHeight m294 : 16|8@1+ (1,-128) [-128|127] "mm"  gtw
 SG_ TAS_a159_valveFaultType m159 : 16|3@1+ (1,0) [0|7] ""  gtw
 SG_ TAS_a038_PWMdutyCycleFL m38 : 16|16@1+ (0.0025,0) [0|100] "%"  gtw
 SG_ TAS_a140_valveFaultType m140 : 16|3@1+ (1,0) [0|7] ""  gtw
 SG_ TAS_a229_PWMdutyCycleRR m229 : 16|16@1+ (0.0025,0) [0|100] "%"  gtw
 SG_ TAS_a072_voltage5VOnBoard m72 : 16|16@1+ (0.001,0) [0|32] "V"  gtw
 SG_ TAS_a145_valveFaultType m145 : 16|3@1+ (1,0) [0|7] ""  gtw
 SG_ TAS_a292_rearAxleHeight m292 : 16|8@1+ (1,-128) [-128|127] "mm"  gtw
 SG_ TAS_a226_PWMdutyCycleFL m226 : 16|16@1+ (0.0025,0) [0|100] "%"  gtw
 SG_ TAS_a025_vehicleLockAtCrash m25 : 16|1@1+ (1,0) [0|1] ""  gtw
 SG_ TAS_a037_PWMdutyCycleRR m37 : 16|16@1+ (0.0025,0) [0|100] "%"  gtw
 SG_ TAS_a100_RCM_inertial2_MIA m100 : 16|1@1+ (1,0) [0|1] ""  gtw
 SG_ TAS_a135_valveFaultType m135 : 16|3@1+ (1,0) [0|7] ""  gtw
 SG_ TAS_a227_PWMdutyCycleFR m227 : 16|16@1+ (0.0025,0) [0|100] "%"  gtw
 SG_ TAS_a153_valveFaultType m153 : 16|3@1+ (1,0) [0|7] ""  gtw
 SG_ TAS_a036_PWMdutyCycleRL m36 : 16|16@1+ (0.0025,0) [0|100] "%"  gtw
 SG_ TAS_a076_voltage5VOffBoard m76 : 16|16@1+ (0.001,0) [0|32] "V"  gtw
 SG_ TAS_a220_galleryPressure m220 : 16|8@1+ (0.1,0) [0|25.5] "bar"  gtw
 SG_ TAS_a021_Task1msLate m21 : 16|1@1+ (1,0) [0|1] ""  gtw
 SG_ TAS_a129_valveFaultType m129 : 16|3@1+ (1,0) [0|7] ""  gtw
 SG_ TAS_a070_voltage12V m70 : 16|16@1+ (0.001,0) [0|32] "V"  gtw
 SG_ TAS_a210_heightSensorDeltaFL m210 : 16|8@1+ (1,-128) [-128|127] "mm"  gtw
 SG_ TAS_a130_valveFaultType m130 : 16|3@1+ (1,0) [0|7] ""  gtw
 SG_ TAS_a079_NVRAM m79 : 16|2@1+ (1,0) [0|2] ""  gtw
 SG_ TAS_a156_valveFaultType m156 : 16|3@1+ (1,0) [0|7] ""  gtw
 SG_ TAS_a039_PWMdutyCycleFR m39 : 16|16@1+ (0.0025,0) [0|100] "%"  gtw
 SG_ TAS_a093_readError m93 : 16|1@1+ (1,0) [0|1] ""  gtw
 SG_ TAS_a228_PWMdutyCycleRL m228 : 16|16@1+ (0.0025,0) [0|100] "%"  gtw
 SG_ TAS_a034_PWMdutyCycleFL m34 : 16|16@1+ (0.0025,0) [0|100] "%"  gtw
 SG_ TAS_a125_dutyCycleReservoir m125 : 16|8@1+ (1,0) [0|100] "%"  gtw
 SG_ TAS_a001_InternalWatchdog m1 : 16|1@1+ (1,0) [0|1] ""  gtw
 SG_ TAS_a041_PWMdutyCycleRR m41 : 16|16@1+ (0.0025,0) [0|100] "%"  gtw
 SG_ TAS_a155_valveFaultType m155 : 16|3@1+ (1,0) [0|7] ""  gtw
 SG_ TAS_a133_valveFaultType m133 : 16|3@1+ (1,0) [0|7] ""  gtw
 SG_ TAS_a078_sensorVoltage m78 : 16|16@1+ (0.001,0) [0|32] "V"  gtw
 SG_ TAS_a124_dutyCycleRR m124 : 16|8@1+ (1,0) [0|100] "%"  gtw
 SG_ TAS_alertType : 15|1@1+ (1,0) [0|1] ""  gtw
 SG_ TAS_alertID M : 0|9@1+ (1,0) [0|295] ""  gtw

BO_ 1817 DAS_IsotermAP: 8 CH
 SG_ DAS_IsotermAP : 7|64@0+ (1,0) [0|18446744073709551615] ""  dbg

BO_ 1429 OCS1P_alertLog: 8 CH
 SG_ OCS1P_a000_alertDataW2 m0 : 48|16@1+ (1,0) [0|65535] ""  X
 SG_ OCS1P_a000_alertDataW1 m0 : 32|16@1+ (1,0) [0|65535] ""  X
 SG_ OCS1P_a122_sandwichFreq m122 : 16|32@1+ (1,0) [0|4294967295] ""  gtw
 SG_ OCS1P_a126_cushionSelfFreq m126 : 16|32@1+ (1,0) [0|4294967295] ""  gtw
 SG_ OCS1P_a128_seatbackSelfFreq m128 : 16|32@1+ (1,0) [0|4294967295] ""  gtw
 SG_ OCS1P_a135_tempNoCalib m135 : 16|1@1+ (1,0) [0|1] ""  gtw
 SG_ OCS1P_a121_sandwichFreq m121 : 16|32@1+ (1,0) [0|4294967295] ""  gtw
 SG_ OCS1P_a140_tempInvalidCalib m140 : 16|1@1+ (1,0) [0|1] ""  gtw
 SG_ OCS1P_a132_seatbackSelfNoCalib m132 : 16|1@1+ (1,0) [0|1] ""  gtw
 SG_ OCS1P_a137_cushionSelfDuty m137 : 16|32@1+ (1,0) [0|4294967295] ""  gtw
 SG_ OCS1P_a127_seatbackSelfFreq m127 : 16|32@1+ (1,0) [0|4294967295] ""  gtw
 SG_ OCS1P_a139_seatbackSelfDuty m139 : 16|32@1+ (1,0) [0|4294967295] ""  gtw
 SG_ OCS1P_a142_tempHumidityInvalid m142 : 16|1@1+ (1,0) [0|1] ""  gtw
 SG_ OCS1P_a130_sandwichNoCalib m130 : 16|1@1+ (1,0) [0|1] ""  gtw
 SG_ OCS1P_a133_sandwichBadCalib m133 : 16|1@1+ (1,0) [0|1] ""  gtw
 SG_ OCS1P_a129_seatbackSelfFreq m129 : 16|32@1+ (1,0) [0|4294967295] ""  gtw
 SG_ OCS1P_a131_cushionSelfNoCalib m131 : 16|1@1+ (1,0) [0|1] ""  gtw
 SG_ OCS1P_a124_cushionSelfFreq m124 : 16|32@1+ (1,0) [0|4294967295] ""  gtw
 SG_ OCS1P_a141_humidityInvalidCalib m141 : 16|1@1+ (1,0) [0|1] ""  gtw
 SG_ OCS1P_a136_cushionSelfDuty m136 : 16|32@1+ (1,0) [0|4294967295] ""  gtw
 SG_ OCS1P_a000_alertDataW0 m0 : 16|16@1+ (1,0) [0|65535] ""  X
 SG_ OCS1P_a134_uninitializedCalib m134 : 16|1@1+ (1,0) [0|1] ""  gtw
 SG_ OCS1P_a125_cushionSelfFreq m125 : 16|32@1+ (1,0) [0|4294967295] ""  gtw
 SG_ OCS1P_a138_seatbackSelfDuty m138 : 16|32@1+ (1,0) [0|4294967295] ""  gtw
 SG_ OCS1P_a123_sandwichFreq m123 : 16|32@1+ (1,0) [0|4294967295] ""  gtw
 SG_ OCS1P_alertType : 15|1@1+ (1,0) [0|1] ""  gtw
 SG_ OCS1P_alertID M : 0|8@1+ (1,0) [0|142] ""  gtw

BO_ 1160 DAS_steeringControl: 4 CH
 SG_ DAS_steeringControlChecksum : 31|8@0+ (1,0) [0|255] ""  aps
 SG_ DAS_steeringControlCounter : 19|4@0+ (1,0) [0|15] ""  aps
 SG_ DAS_steeringControlType : 23|2@0+ (1,0) [0|3] ""  aps
 SG_ DAS_steeringAngleRequest : 6|15@0+ (0.1,-1638.35) [-1638.35|1638.35] "deg"  aps
 SG_ DAS_steeringHapticRequest : 7|1@0+ (1,0) [0|1] ""  aps

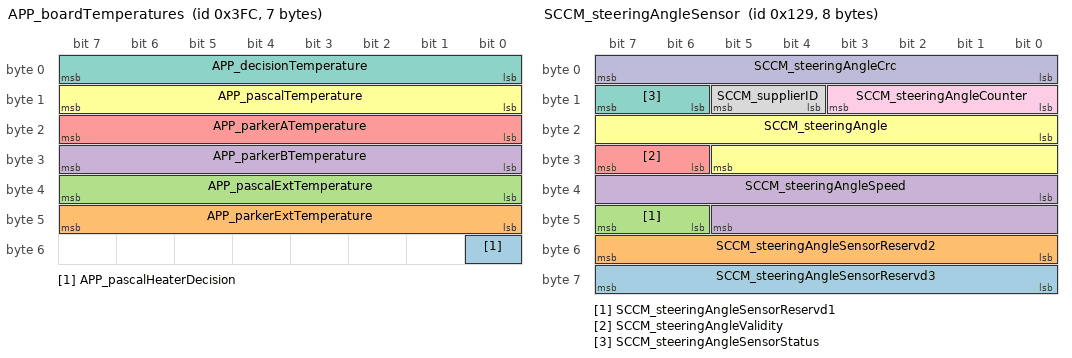
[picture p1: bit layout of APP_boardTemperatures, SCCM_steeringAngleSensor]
BO_ 1020 APP_boardTemperatures: 7 CH
 SG_ APP_pascalHeaterDecision : 48|1@1+ (1,0) [0|1] ""  aps
 SG_ APP_parkerExtTemperature : 40|8@1+ (1,-128) [-128|127] "C"  aps
 SG_ APP_pascalExtTemperature : 32|8@1+ (1,-128) [-128|127] "C"  aps
 SG_ APP_parkerBTemperature : 24|8@1+ (1,-128) [-128|127] "C"  aps
 SG_ APP_parkerATemperature : 16|8@1+ (1,-128) [-128|127] "C"  aps
 SG_ APP_pascalTemperature : 8|8@1+ (1,-128) [-128|127] "C"  aps
 SG_ APP_decisionTemperature : 0|8@1+ (1,-128) [-128|127] "C"  aps

BO_ 1465 DAS_alertLog: 8 CH
 SG_ DAS_sw060_accActive m60 : 63|1@1+ (1,0) [0|1] ""  gtw
 SG_ DAS_sw076_accActive m76 : 63|1@1+ (1,0) [0|1] ""  gtw
 SG_ DAS_sw053_a62strRackMismatch m53 : 63|1@1+ (1,0) [0|1] ""  gtw
 SG_ DAS_sw050_accActive m50 : 63|1@1+ (1,0) [0|1] ""  gtw
 SG_ DAS_sw016_accActive m16 : 63|1@1+ (1,0) [0|1] ""  gtw
 SG_ DAS_sw017_Any_FCW_PCW_Msg_Recd m17 : 63|1@1+ (1,0) [0|1] ""  gtw
 SG_ DAS_sw074_autopilotActive m74 : 63|1@1+ (1,0) [0|1] ""  gtw
 SG_ DAS_sw074_cruiseActive m74 : 62|1@1+ (1,0) [0|1] ""  gtw
 SG_ DAS_sw053_a61radPositionMismatch m53 : 62|1@1+ (1,0) [0|1] ""  gtw
 SG_ DAS_sw072_userTimeout m72 : 62|1@1+ (1,0) [0|1] ""  gtw
 SG_ DAS_sw017_Any_Common_Msg_Recd m17 : 62|1@1+ (1,0) [0|1] ""  gtw
 SG_ DAS_sw027_Unused_word m27 : 62|2@1+ (1,0) [0|3] ""  gtw
 SG_ DAS_sw076_fcmModeAtEvent m76 : 61|2@1+ (1,0) [0|3] ""  gtw
 SG_ DAS_sw053_a60drmiInvalidCount m53 : 61|1@1+ (1,0) [0|1] ""  gtw
 SG_ DAS_sw086_driverHandsOn m86 : 61|1@1+ (1,0) [0|1] ""  gtw
 SG_ DAS_sw004_visionNotRunning m4 : 61|1@1+ (1,0) [0|1] ""  gtw
 SG_ DAS_sw017_Any_Hlb_Msg_Recd m17 : 61|1@1+ (1,0) [0|1] ""  gtw
 SG_ DAS_sw016_fcmModeAtEvent m16 : 61|2@1+ (1,0) [0|3] ""  gtw
 SG_ DAS_sw027_PORST m27 : 61|1@1+ (1,0) [0|1] ""  gtw
 SG_ DAS_sw050_fcmModeAtEvent m50 : 61|2@1+ (1,0) [0|3] ""  gtw
 SG_ DAS_sw072_garageOpened m72 : 61|1@1+ (1,0) [0|1] ""  gtw
 SG_ DAS_sw073_freespaceRightFarZ m73 : 60|4@1+ (4,0) [0|60] "m"  gtw
 SG_ DAS_sw199_numShifts m199 : 60|4@1+ (1,0) [0|15] ""  gtw
 SG_ DAS_sw013_numTransportErrors m13 : 60|4@1+ (1,0) [0|15] ""  gtw
 SG_ DAS_sw050_overrideSteer m50 : 60|1@1+ (1,0) [0|1] ""  gtw
 SG_ DAS_sw060_collisionWarningSource m60 : 60|3@1+ (1,0) [0|7] ""  gtw
 SG_ DAS_sw231_predOverlap m231 : 60|4@1+ (10,0) [0|150] "percent"  gtw
 SG_ DAS_sw076_overrideSteer m76 : 60|1@1+ (1,0) [0|1] ""  gtw
 SG_ DAS_sw004_SelfGlare m4 : 60|1@1+ (1,0) [0|1] ""  gtw
 SG_ DAS_sw072_keyfobPress m72 : 60|1@1+ (1,0) [0|1] ""  gtw
 SG_ DAS_sw016_overrideSteer m16 : 60|1@1+ (1,0) [0|1] ""  gtw
 SG_ DAS_sw017_Any_Tsr_Msg_Recd m17 : 60|1@1+ (1,0) [0|1] ""  gtw
 SG_ DAS_sw086_controlledAccess m86 : 60|1@1+ (1,0) [0|1] ""  gtw
 SG_ DAS_sw027_STDBY_WDG m27 : 60|1@1+ (1,0) [0|1] ""  gtw
 SG_ DAS_sw053_a59drmiInvalidChkSm m53 : 60|1@1+ (1,0) [0|1] ""  gtw
 SG_ DAS_sw053_a57dimodValidity m53 : 59|1@1+ (1,0) [0|1] ""  gtw
 SG_ DAS_sw004_FoggyLights m4 : 59|1@1+ (1,0) [0|1] ""  gtw
 SG_ DAS_sw076_overrideBrake m76 : 59|1@1+ (1,0) [0|1] ""  gtw
 SG_ DAS_sw103_radAlignment m103 : 59|5@1+ (0.015625,-0.2343) [-0.2343|0.25] "rad"  gtw
 SG_ DAS_sw027_SWD m27 : 59|1@1+ (1,0) [0|1] ""  gtw
 SG_ DAS_sw074_roadClass m74 : 59|3@1+ (1,0) [0|7] ""  gtw
 SG_ DAS_sw083_Targ5_wNonObj m83 : 59|5@1+ (0.03125,0) [0|0.96875] "%"  gtw
 SG_ DAS_sw016_overrideBrake m16 : 59|1@1+ (1,0) [0|1] ""  gtw
 SG_ DAS_sw231_steeringOverride m231 : 59|1@1+ (1,0) [0|1] ""  gtw
 SG_ DAS_sw060_overrideSteer m60 : 59|1@1+ (1,0) [0|1] ""  gtw
 SG_ DAS_sw072_handlePress m72 : 59|1@1+ (1,0) [0|1] ""  gtw
 SG_ DAS_sw086_ipsoApproved m86 : 59|1@1+ (1,0) [0|1] ""  gtw
 SG_ DAS_sw050_overrideBrake m50 : 59|1@1+ (1,0) [0|1] ""  gtw
 SG_ DAS_sw050_overrideBlinker m50 : 58|1@1+ (1,0) [0|1] ""  gtw
 SG_ DAS_sw004_SmearedHalos m4 : 58|1@1+ (1,0) [0|1] ""  gtw
 SG_ DAS_sw053_a56bcmodValidity m53 : 58|1@1+ (1,0) [0|1] ""  gtw
 SG_ DAS_sw076_overrideBlinker m76 : 58|1@1+ (1,0) [0|1] ""  gtw
 SG_ DAS_sw016_overrideBlinker m16 : 58|1@1+ (1,0) [0|1] ""  gtw
 SG_ DAS_sw072_guidanceTimer m72 : 58|1@1+ (1,0) [0|1] ""  gtw
 SG_ DAS_sw027_EVR33 m27 : 58|1@1+ (1,0) [0|1] ""  gtw
 SG_ DAS_sw047_unused m47 : 58|6@1+ (1,0) [0|63] ""  gtw
 SG_ DAS_sw060_overrideBrake m60 : 58|1@1+ (1,0) [0|1] ""  gtw
 SG_ DAS_sw006_timeOfDay m6 : 58|2@1+ (1,0) [0|3] ""  gtw
 SG_ DAS_sw085_freeSpaceC0Right m85 : 58|5@1+ (1,-15) [-15|16] "m"  gtw
 SG_ DAS_sw053_a55stwmodValidity m53 : 57|1@1+ (1,0) [0|1] ""  gtw
 SG_ DAS_sw076_overrideAccelPed m76 : 57|1@1+ (1,0) [0|1] ""  gtw
 SG_ DAS_sw072_guidanceRunaway m72 : 57|1@1+ (1,0) [0|1] ""  gtw
 SG_ DAS_sw103_constArea m103 : 57|2@1+ (1,0) [0|3] ""  gtw
 SG_ DAS_sw016_overrideAccelPed m16 : 57|1@1+ (1,0) [0|1] ""  gtw
 SG_ DAS_sw050_aebEnable m50 : 57|1@1+ (1,0) [0|1] ""  gtw
 SG_ DAS_sw026_veh_mean_utilization m26 : 57|7@1+ (1,0) [0|127] "percent"  gtw
 SG_ DAS_sw060_overrideBlinker m60 : 57|1@1+ (1,0) [0|1] ""  gtw
 SG_ DAS_sw006_trailerMode m6 : 57|1@1+ (1,0) [0|1] ""  gtw
 SG_ DAS_sw004_FullBlockage m4 : 57|1@1+ (1,0) [0|1] ""  gtw
 SG_ DAS_sw027_EVR13 m27 : 57|1@1+ (1,0) [0|1] ""  gtw
 SG_ DAS_sw103_ipsoApproved m103 : 56|1@1+ (1,0) [0|1] ""  gtw
 SG_ DAS_sw006_brakeLights m6 : 56|1@1+ (1,0) [0|1] ""  gtw
 SG_ DAS_sw027_CBS_APP m27 : 56|1@1+ (1,0) [0|1] ""  gtw
 SG_ DAS_sw016_driverPressedBrakePed m16 : 56|1@1+ (1,0) [0|1] ""  gtw
 SG_ DAS_sw072_guidanceComplete m72 : 56|1@1+ (1,0) [0|1] ""  gtw
 SG_ DAS_sw067_offsetEstimator m67 : 56|8@1+ (0.1,-12.8) [-12.8|12.8] "deg"  gtw
 SG_ DAS_sw205_rrRightMiddle m205 : 56|8@1+ (1,0) [0|255] "cm"  gtw
 SG_ DAS_sw076_driverPressedBrakePed m76 : 56|1@1+ (1,0) [0|1] ""  gtw
 SG_ DAS_sw042_road_class m42 : 56|3@1+ (1,0) [0|7] ""  gtw
 SG_ DAS_sw015_NarrowCameraBadAssoc m15 : 56|2@1+ (1,0) [0|3] ""  gtw
 SG_ DAS_sw011_laneWidth m11 : 56|8@1+ (0.025,0) [0|6.375] "m"  gtw
 SG_ DAS_sw078_radarTarg1_VxRel m78 : 56|8@1+ (0.2,-25.6) [-25.6|25.4] "m/s"  gtw
 SG_ DAS_sw060_overrideAccelPed m60 : 56|1@1+ (1,0) [0|1] ""  gtw
 SG_ DAS_sw050_driverPressedBrakePed m50 : 56|1@1+ (1,0) [0|1] ""  gtw
 SG_ DAS_sw047_edrLoggerBuffer m47 : 56|2@1+ (1,0) [0|3] ""  gtw
 SG_ DAS_sw004_AutofixOutOfCalibYaw m4 : 56|1@1+ (1,0) [0|1] ""  gtw
 SG_ DAS_sw040_view_range m40 : 56|8@1+ (1,0) [0|255] "m"  gtw
 SG_ DAS_sw063_detectedSubMinorVer m63 : 56|8@1+ (1,0) [0|255] ""  gtw
 SG_ DAS_sw071_activationType m71 : 56|2@1+ (1,0) [0|2] ""  gtw
 SG_ DAS_sw086_roadClass m86 : 56|3@1+ (1,0) [0|7] ""  gtw
 SG_ DAS_sw073_freespaceLeftFarZ m73 : 56|4@1+ (4,0) [0|60] "m"  gtw
 SG_ DAS_sw204_maxSpeed m204 : 56|8@1+ (0.1,-12.2) [-12.2|12.2] "mph"  gtw
 SG_ DAS_sw053_a54gtwmodValidity m53 : 56|1@1+ (1,0) [0|1] ""  gtw
 SG_ DAS_sw050_driverPressedAccelPed m50 : 55|1@1+ (1,0) [0|1] ""  gtw
 SG_ DAS_sw027_CBS_DEBUG m27 : 55|1@1+ (1,0) [0|1] ""  gtw
 SG_ DAS_sw004_AutofixOutOfCalibHorzn m4 : 55|1@1+ (1,0) [0|1] ""  gtw
 SG_ DAS_sw006_DIaebStateUnavailable m6 : 55|1@1+ (1,0) [0|1] ""  gtw
 SG_ DAS_sw076_driverPressedAccelPed m76 : 55|1@1+ (1,0) [0|1] ""  gtw
 SG_ DAS_sw016_driverPressedAccelPed m16 : 55|1@1+ (1,0) [0|1] ""  gtw
 SG_ DAS_sw053_a53espmodValidity m53 : 55|1@1+ (1,0) [0|1] ""  gtw
 SG_ DAS_sw042_controlled_access m42 : 55|1@1+ (1,0) [0|1] ""  gtw
 SG_ DAS_sw060_driverPressedBrakePed m60 : 55|1@1+ (1,0) [0|1] ""  gtw
 SG_ DAS_sw015_MainCameraBadAssoc m15 : 54|2@1+ (1,0) [0|3] ""  gtw
 SG_ DAS_sw231_egoVehicleSpeed m231 : 54|5@1+ (5,0) [0|155] "kph"  gtw
 SG_ DAS_sw086_mcvrValid m86 : 54|1@1+ (1,0) [0|1] ""  gtw
 SG_ DAS_sw027_CBS_SYSTEM m27 : 54|1@1+ (1,0) [0|1] ""  gtw
 SG_ DAS_sw053_a51yawSanity m53 : 54|1@1+ (1,0) [0|1] ""  gtw
 SG_ DAS_sw006_DIaebState_SNA m6 : 54|1@1+ (1,0) [0|1] ""  gtw
 SG_ DAS_sw083_Targ5_wObj m83 : 54|5@1+ (0.03125,0) [0|0.96875] "%"  gtw
 SG_ DAS_sw074_ipsowExist m74 : 54|5@1+ (1,0) [0|31] ""  gtw
 SG_ DAS_sw077_oocOffCourseDist_cm m77 : 54|10@1- (1,0) [-512|511] ""  gtw
 SG_ DAS_sw042_road_match m42 : 54|1@1+ (1,0) [0|1] ""  gtw
 SG_ DAS_sw069_drivingLaneRight m69 : 54|8@1+ (1,0) [0|255] ""  gtw
 SG_ DAS_sw004_AutofixOutOfCalib m4 : 54|1@1+ (1,0) [0|1] ""  gtw
 SG_ DAS_sw086_mcvlValid m86 : 53|1@1+ (1,0) [0|1] ""  gtw
 SG_ DAS_sw080_cruise_speed_check m80 : 53|1@1+ (1,0) [0|1] ""  gtw
 SG_ DAS_sw011_scaReasonEldw m11 : 53|1@1+ (1,0) [0|1] ""  gtw
 SG_ DAS_sw053_a50velocitySanity m53 : 53|1@1+ (1,0) [0|1] ""  gtw
 SG_ DAS_sw085_freeSpaceC0Left m85 : 53|5@1+ (1,-15) [-15|16] "m"  gtw
 SG_ DAS_sw012_freescaleTemp m12 : 53|8@1- (1,0) [-128|127] "degC"  gtw
 SG_ DAS_sw006_yawRate m6 : 53|1@1+ (1,0) [0|1] ""  gtw
 SG_ DAS_sw231_targetIsACar m231 : 53|1@1+ (1,0) [0|1] ""  gtw
 SG_ DAS_sw042_cam_OutofFocus m42 : 53|1@1+ (1,0) [0|1] ""  gtw
 SG_ DAS_sw027_STM2 m27 : 53|1@1+ (1,0) [0|1] ""  gtw
 SG_ DAS_sw004_PartialBlockage m4 : 53|1@1+ (1,0) [0|1] ""  gtw
 SG_ DAS_sw006_longAccel m6 : 52|1@1+ (1,0) [0|1] ""  gtw
 SG_ DAS_sw015_NarrowCameraLowLight m15 : 52|2@1+ (1,0) [0|3] ""  gtw
 SG_ DAS_sw004_SmearedSpots m4 : 52|1@1+ (1,0) [0|1] ""  gtw
 SG_ DAS_sw027_STM1 m27 : 52|1@1+ (1,0) [0|1] ""  gtw
 SG_ DAS_sw203_vehicleSkew m203 : 52|12@1+ (0.002,0) [0|8.19] "radians"  gtw
 SG_ DAS_sw086_cipvValid m86 : 52|1@1+ (1,0) [0|1] ""  gtw
 SG_ DAS_sw199_maxSpeed m199 : 52|8@1+ (0.1,-12.2) [-12.2|12.2] "mph"  gtw
 SG_ DAS_sw011_egoCentered m11 : 52|1@1+ (1,0) [0|1] ""  gtw
 SG_ DAS_sw042_cam_SelfGlare m42 : 52|1@1+ (1,0) [0|1] ""  gtw
 SG_ DAS_sw053_a49tireSizeSanity m53 : 52|1@1+ (1,0) [0|1] ""  gtw
 SG_ DAS_sw011_polyValid m11 : 51|1@1+ (1,0) [0|1] ""  gtw
 SG_ DAS_sw053_a48steerAngOffSanity m53 : 51|1@1+ (1,0) [0|1] ""  gtw
 SG_ DAS_sw027_STM0 m27 : 51|1@1+ (1,0) [0|1] ""  gtw
 SG_ DAS_sw042_cam_FoggySpots m42 : 51|1@1+ (1,0) [0|1] ""  gtw
 SG_ DAS_sw086_activeBraking m86 : 51|1@1+ (1,0) [0|1] ""  gtw
 SG_ DAS_sw060_RadarAssociationAge m60 : 51|4@1+ (100,0) [0|1500] "ms"  gtw
 SG_ DAS_sw004_LowSun m4 : 51|1@1+ (1,0) [0|1] ""  gtw
 SG_ DAS_sw006_camFcwPcwMsg m6 : 51|1@1+ (1,0) [0|1] ""  gtw
 SG_ DAS_sw080_cruise_lever_state m80 : 50|3@1+ (1,0) [0|7] ""  gtw
 SG_ DAS_sw015_MainCameraLowLight m15 : 50|2@1+ (1,0) [0|3] ""  gtw
 SG_ DAS_sw026_mob_mean_utilization m26 : 50|7@1+ (1,0) [0|127] "percent"  gtw
 SG_ DAS_sw004_BlurredImage m4 : 50|1@1+ (1,0) [0|1] ""  gtw
 SG_ DAS_sw027_SW m27 : 50|1@1+ (1,0) [0|1] ""  gtw
 SG_ DAS_sw011_egoMovingLeft m11 : 50|1@1+ (1,0) [0|1] ""  gtw
 SG_ DAS_sw042_cam_SmearedHalos m42 : 50|1@1+ (1,0) [0|1] ""  gtw
 SG_ DAS_sw012_mespDDRTempStatus m12 : 50|3@1+ (1,0) [0|7] ""  gtw
 SG_ DAS_sw053_a44yawValidity m53 : 50|1@1+ (1,0) [0|1] ""  gtw
 SG_ DAS_sw006_camCommonMsg m6 : 50|1@1+ (1,0) [0|1] ""  gtw
 SG_ DAS_sw080_min_speed_check m80 : 49|1@1+ (1,0) [0|1] ""  gtw
 SG_ DAS_sw006_camObjHeader m6 : 49|1@1+ (1,0) [0|1] ""  gtw
 SG_ DAS_sw053_a43yawOffValidity m53 : 49|1@1+ (1,0) [0|1] ""  gtw
 SG_ DAS_sw027_ESR1 m27 : 49|1@1+ (1,0) [0|1] ""  gtw
 SG_ DAS_sw042_cam_FullBlock m42 : 49|1@1+ (1,0) [0|1] ""  gtw
 SG_ DAS_sw011_egoLeftOfCenter m11 : 49|1@1+ (1,0) [0|1] ""  gtw
 SG_ DAS_sw004_Splashes m4 : 49|1@1+ (1,0) [0|1] ""  gtw
 SG_ DAS_sw020_unusedW2 m20 : 48|16@1+ (1,0) [0|65535] ""  gtw
 SG_ DAS_sw082_road_class m82 : 48|3@1+ (1,0) [0|7] ""  gtw
 SG_ DAS_sw103_distanceEllipse m103 : 48|8@1+ (0.5,0) [0|127.5] "m"  gtw
 SG_ DAS_sw035_unusedW1 m35 : 48|16@1+ (1,0) [0|65535] ""  gtw
 SG_ DAS_sw006_camWatchdog m6 : 48|1@1+ (1,0) [0|1] ""  gtw
 SG_ DAS_sw199_internalState m199 : 48|4@1+ (1,0) [0|15] ""  gtw
 SG_ DAS_sw027_ESR0 m27 : 48|1@1+ (1,0) [0|1] ""  gtw
 SG_ DAS_sw013_highestSeqRecd m13 : 48|12@1+ (1,0) [0|4095] ""  gtw
 SG_ DAS_sw065_unusedW1 m65 : 48|16@1+ (1,0) [0|65535] ""  gtw
 SG_ DAS_sw042_cam_AutofixYaw m42 : 48|1@1+ (1,0) [0|1] ""  gtw
 SG_ DAS_sw011_egoMovingRight m11 : 48|1@1+ (1,0) [0|1] ""  gtw
 SG_ DAS_sw071_temperature m71 : 48|8@1+ (0.5,-40) [-40|87.5] "C"  gtw
 SG_ DAS_sw054_unusedW0 m54 : 48|16@1+ (1,0) [0|65535] ""  gtw
 SG_ DAS_sw010_VmaPlausibility m10 : 48|16@1+ (1.52587890625005e-05,0) [0|0.99998474121097] "FIXME"  gtw
 SG_ DAS_sw066_unusedW1 m66 : 48|16@1+ (1,0) [0|65535] ""  gtw
 SG_ DAS_sw014_assertData m14 : 48|16@1+ (1,0) [0|65535] ""  gtw
 SG_ DAS_sw058_unusedW1 m58 : 48|16@1+ (1,0) [0|65535] ""  gtw
 SG_ DAS_sw050_hostLongAccel m50 : 48|7@1+ (0.15625,-10) [-10|10] "m/s^2"  gtw
 SG_ DAS_sw028_multifrm_rx_len m28 : 48|16@1+ (1,0) [0|65535] ""  gtw
 SG_ DAS_sw062_VmaPlausibility m62 : 48|16@1+ (1.52587890625005e-05,0) [0|0.99998474121097] "FIXME"  gtw
 SG_ DAS_sw075_unusedW1 m75 : 48|16@1+ (1,0) [0|65535] ""  gtw
 SG_ DAS_sw015_OutOfFocusImage m15 : 48|2@1+ (1,0) [0|3] ""  gtw
 SG_ DAS_sw053_a42xwdValidity m53 : 48|1@1+ (1,0) [0|1] ""  gtw
 SG_ DAS_sw034_unusedW1 m34 : 48|16@1+ (1,0) [0|65535] ""  gtw
 SG_ DAS_sw080_cipv_valid m80 : 48|1@1+ (1,0) [0|1] ""  gtw
 SG_ DAS_sw049_ffs_version_msw m49 : 48|16@1+ (1,0) [0|65535] ""  gtw
 SG_ DAS_sw043_camLongRunTime_unused m43 : 48|16@1+ (1,0) [0|65535] ""  gtw
 SG_ DAS_sw051_unusedW1 m51 : 48|16@1+ (1,0) [0|65535] ""  gtw
 SG_ DAS_sw004_SunRay m4 : 48|1@1+ (1,0) [0|1] ""  gtw
 SG_ DAS_sw037_unusedW1 m37 : 48|16@1+ (1,0) [0|65535] ""  gtw
 SG_ DAS_sw045_unusedW1 m45 : 48|16@1+ (1,0) [0|65535] ""  gtw
 SG_ DAS_sw032_errorData2 m32 : 48|16@1+ (1,0) [0|65535] ""  gtw
 SG_ DAS_sw201_viewRangeOAL m201 : 48|3@1+ (1,0) [0|7] ""  gtw
 SG_ DAS_sw076_hostLongAccel m76 : 48|7@1+ (0.15625,-10) [-10|10] "m/s^2"  gtw
 SG_ DAS_sw077_oocUntrackedTime m77 : 48|6@1+ (0.1,0) [0|6.3] "s"  gtw
 SG_ DAS_sw081_pedalPosition m81 : 48|7@1+ (1,0) [0|127] "%"  gtw
 SG_ DAS_sw055_expectedCrcLsw m55 : 48|16@1+ (1,0) [0|65535] ""  gtw
 SG_ DAS_sw025_torsionBarTorque m25 : 48|8@1+ (0.1,-12.8) [-12.8|12.7] "Nm"  gtw
 SG_ DAS_sw078_radarTarg1_dx m78 : 48|8@1+ (0.0625,0) [0|15.9375] "m"  gtw
 SG_ DAS_sw056_unusedW1 m56 : 48|16@1+ (1,0) [0|65535] ""  gtw
 SG_ DAS_sw021_unusedWord m21 : 48|16@1+ (1,0) [0|65535] ""  gtw
 SG_ DAS_sw063_expectedSubMinorVer m63 : 48|8@1+ (1,0) [0|255] ""  gtw
 SG_ DAS_sw029_unusedW1 m29 : 48|16@1+ (1,0) [0|65535] ""  gtw
 SG_ DAS_sw030_unusedW1 m30 : 48|16@1+ (1,0) [0|65535] ""  gtw
 SG_ DAS_sw072_endDistance m72 : 48|8@1+ (1,0) [0|255] "cm"  gtw
 SG_ DAS_sw194_timeInHold m194 : 48|16@1+ (1,0) [0|65535] ""  gtw
 SG_ DAS_sw018_currentVoltage m18 : 48|16@1+ (1,0) [0|6600] "mV"  gtw
 SG_ DAS_sw047_edrStateMachine m47 : 48|8@1+ (1,0) [0|255] ""  gtw
 SG_ DAS_sw074_ipsoConfidence m74 : 48|6@1+ (2,0) [0|126] "percent"  gtw
 SG_ DAS_sw033_unusedW1 m33 : 48|16@1+ (1,0) [0|65535] ""  gtw
 SG_ DAS_sw083_Targ5_dz m83 : 48|6@1+ (0.25,-5) [-5|10.75] "m"  gtw
 SG_ DAS_sw040_torsion_bar_torque m40 : 48|8@1+ (0.1,-12.8) [-12.8|12.7] "Nm"  gtw
 SG_ DAS_sw205_rrRight m205 : 48|8@1+ (1,0) [0|255] "cm"  gtw
 SG_ DAS_sw204_frRightMiddle m204 : 48|8@1+ (1,0) [0|255] "cm"  gtw
 SG_ DAS_sw086_ellipseAge m86 : 48|3@1+ (1,0) [0|7] ""  gtw
 SG_ DAS_sw036_unusedW1 m36 : 48|16@1+ (1,0) [0|65535] ""  gtw
 SG_ DAS_sw039_unusedW1 m39 : 48|16@1+ (1,0) [0|65535] ""  gtw
 SG_ DAS_sw031_errorData2 m31 : 48|16@1+ (1,0) [0|65535] ""  gtw
 SG_ DAS_sw061_unusedW1 m61 : 48|16@1+ (1,0) [0|65535] ""  gtw
 SG_ DAS_sw017_highestSeqRecd m17 : 48|12@1+ (1,0) [0|4095] ""  gtw
 SG_ DAS_sw016_hostLongAccel m16 : 48|7@1+ (0.15625,-10) [-10|10] "m/s^2"  gtw
 SG_ DAS_sw059_unusedW1 m59 : 48|16@1+ (1,0) [0|65535] ""  gtw
 SG_ DAS_sw073_freespaceRightC1 m73 : 48|8@1+ (0.0016,-0.2) [-0.2|0.2] "rad"  gtw
 SG_ DAS_sw053_a41wiperValidity m53 : 47|1@1+ (1,0) [0|1] ""  gtw
 SG_ DAS_sw004_ImpairedVD m4 : 47|1@1+ (1,0) [0|1] ""  gtw
 SG_ DAS_sw006_speedDerivative m6 : 47|1@1+ (1,0) [0|1] ""  gtw
 SG_ DAS_sw011_egoRightOfCenter m11 : 47|1@1+ (1,0) [0|1] ""  gtw
 SG_ DAS_sw085_averageSpeedHist m85 : 47|6@1+ (0.25,0) [0|16] "mps"  gtw
 SG_ DAS_sw060_hostLongAccel m60 : 47|4@1+ (1,-7.5) [-7.5|7.5] "m/s^2"  gtw
 SG_ DAS_sw042_cam_AutofixHorizon m42 : 47|1@1+ (1,0) [0|1] ""  gtw
 SG_ DAS_sw018_railControl m18 : 47|1@1+ (1,0) [0|1] ""  gtw
 SG_ DAS_sw069_drivingLaneLeft m69 : 46|8@1+ (1,0) [0|255] ""  gtw
 SG_ DAS_sw041_unusedW2 m41 : 46|18@1+ (1,0) [0|262143] ""  gtw
 SG_ DAS_sw053_a40whlStndStllValidty m53 : 46|1@1+ (1,0) [0|1] ""  gtw
 SG_ DAS_sw042_cam_Autofix m42 : 46|1@1+ (1,0) [0|1] ""  gtw
 SG_ DAS_sw010_unusedBits m10 : 46|2@1+ (1,0) [0|3] ""  gtw
 SG_ DAS_sw004_OutOfFocusImage m4 : 46|1@1+ (1,0) [0|1] ""  gtw
 SG_ DAS_sw006_dasDisabled m6 : 46|1@1+ (1,0) [0|1] ""  gtw
 SG_ DAS_sw015_SelfGlare m15 : 46|2@1+ (1,0) [0|3] ""  gtw
 SG_ DAS_sw231_targetRelAcceleration m231 : 45|8@1+ (0.1,-12.8) [-12.8|12.7] "m/s2"  gtw
 SG_ DAS_sw053_a39whlSpdValidity m53 : 45|1@1+ (1,0) [0|1] ""  gtw
 SG_ DAS_sw006_stabilityControl m6 : 45|1@1+ (1,0) [0|1] ""  gtw
 SG_ DAS_sw042_cam_PartialBlock m42 : 45|1@1+ (1,0) [0|1] ""  gtw
 SG_ DAS_sw004_RadarMisalignment m4 : 45|1@1+ (1,0) [0|1] ""  gtw
 SG_ DAS_sw005_RadarLowVisibility m5 : 44|1@1+ (1,0) [0|1] ""  gtw
 SG_ DAS_sw053_a38whlRotValidity m53 : 44|1@1+ (1,0) [0|1] ""  gtw
 SG_ DAS_sw042_cam_SmearedSpots m42 : 44|1@1+ (1,0) [0|1] ""  gtw
 SG_ DAS_sw071_airSuspension m71 : 44|3@1+ (1,0) [0|7] ""  gtw
 SG_ DAS_sw006_gear m6 : 44|1@1+ (1,0) [0|1] ""  gtw
 SG_ DAS_sw067_vehSpeed m67 : 44|12@1+ (0.1,-50) [-50|359.6] "kph"  gtw
 SG_ DAS_sw194_reasonForHold m194 : 44|4@1+ (1,0) [0|15] ""  gtw
 SG_ DAS_sw015_ImpairedVD m15 : 44|2@1+ (1,0) [0|3] ""  gtw
 SG_ DAS_sw004_RadarLowVisibility m4 : 44|1@1+ (1,0) [0|1] ""  gtw
 SG_ DAS_sw026_uds_mean_utilization m26 : 43|7@1+ (1,0) [0|127] "percent"  gtw
 SG_ DAS_sw042_cam_LowSun m42 : 43|1@1+ (1,0) [0|1] ""  gtw
 SG_ DAS_sw053_a37vinValidity m53 : 43|1@1+ (1,0) [0|1] ""  gtw
 SG_ DAS_sw004_CamWatchdog m4 : 43|1@1+ (1,0) [0|1] ""  gtw
 SG_ DAS_sw071_driverPresent m71 : 43|1@1+ (1,0) [0|1] ""  gtw
 SG_ DAS_sw006_speed m6 : 43|1@1+ (1,0) [0|1] ""  gtw
 SG_ DAS_sw080_ego_speed m80 : 43|5@1+ (1,0) [0|31] "mph"  gtw
 SG_ DAS_sw005_AutofixOutOfCalibHorzn m5 : 43|1@1+ (1,0) [0|1] ""  gtw
 SG_ DAS_sw005_camWatchdog m5 : 42|1@1+ (1,0) [0|1] ""  gtw
 SG_ DAS_sw004_CamObjectsMIA m4 : 42|1@1+ (1,0) [0|1] ""  gtw
 SG_ DAS_sw042_cam_BlurredImage m42 : 42|1@1+ (1,0) [0|1] ""  gtw
 SG_ DAS_sw062_unusedBits m62 : 42|6@1+ (1,0) [0|63] ""  gtw
 SG_ DAS_sw069_roadClass m69 : 42|4@1+ (1,0) [0|15] ""  gtw
 SG_ DAS_sw012_mespFatalErrDetails m12 : 42|8@1+ (1,0) [0|255] ""  gtw
 SG_ DAS_sw006_steeringAngleRate m6 : 42|1@1+ (1,0) [0|1] ""  gtw
 SG_ DAS_sw053_a36vehStndStllValidty m53 : 42|1@1+ (1,0) [0|1] ""  gtw
 SG_ DAS_sw015_SunRay m15 : 42|2@1+ (1,0) [0|3] ""  gtw
 SG_ DAS_sw004_CamCommonMIA m4 : 41|1@1+ (1,0) [0|1] ""  gtw
 SG_ DAS_sw203_startDistance m203 : 41|11@1+ (1,0) [0|2047] "cm"  gtw
 SG_ DAS_sw006_steeringAngle m6 : 41|1@1+ (1,0) [0|1] ""  gtw
 SG_ DAS_sw042_cam_RoadSpray m42 : 41|1@1+ (1,0) [0|1] ""  gtw
 SG_ DAS_sw085_rightLaneExist m85 : 41|6@1+ (2,0) [0|128] "%"  gtw
 SG_ DAS_sw053_a35indctrValidity m53 : 41|1@1+ (1,0) [0|1] ""  gtw
 SG_ DAS_sw005_speedDerivative m5 : 41|1@1+ (1,0) [0|1] ""  gtw
 SG_ DAS_sw081_cameraTTC m81 : 40|8@1+ (0.02,0) [0|5.11] "seconds"  gtw
 SG_ DAS_sw005_dasDisabled m5 : 40|1@1+ (1,0) [0|1] ""  gtw
 SG_ DAS_sw078_radarTarg5_VxRel m78 : 40|8@1+ (0.2,-25.6) [-25.6|25.4] "m/s"  gtw
 SG_ DAS_sw027_Unused_Byte m27 : 40|8@1+ (1,0) [0|255] ""  gtw
 SG_ DAS_sw068_navigationSTW m68 : 40|14@1+ (0.1,-819.2) [-819.2|819.2] "deg"  gtw
 SG_ DAS_sw042_cam_SunRay m42 : 40|1@1+ (1,0) [0|1] ""  gtw
 SG_ DAS_sw084_ipsoDy m84 : 40|8@1+ (0.1,-12.6) [-12.6|12.9] "meters"  gtw
 SG_ DAS_sw025_offsetSide m25 : 40|2@1+ (1,0) [0|3] ""  gtw
 SG_ DAS_sw082_R_Lane m82 : 40|8@1+ (0.05,-6.4) [-6.4|6.35] "m"  gtw
 SG_ DAS_sw060_hostSpeed m60 : 40|7@1+ (2,0) [0|254] "kph"  gtw
 SG_ DAS_sw070_currentSpeed m70 : 40|12@1+ (0.1,-204.7) [-204.7|204.8] "mph"  gtw
 SG_ DAS_sw205_rrMiddle m205 : 40|8@1+ (1,0) [0|255] "cm"  gtw
 SG_ DAS_sw204_frRight m204 : 40|8@1+ (1,0) [0|255] "cm"  gtw
 SG_ DAS_sw050_hostSpeed m50 : 40|8@1+ (1,0) [0|255] "kph"  gtw
 SG_ DAS_sw195_vehicleSpeed m195 : 40|12@1+ (0.1,0) [0|409.6] "kph"  gtw
 SG_ DAS_sw051_unusedB0 m51 : 40|8@1+ (1,0) [0|255] ""  gtw
 SG_ DAS_sw199_currentSpeed m199 : 40|8@1+ (0.1,-12.2) [-12.2|12.2] "mph"  gtw
 SG_ DAS_sw202_vehicleSpeed m202 : 40|12@1+ (0.1,0) [0|409.6] "kph"  gtw
 SG_ DAS_sw004_appMobileyeNotInVision m4 : 40|1@1+ (1,0) [0|1] ""  gtw
 SG_ DAS_sw194_numPedstrian m194 : 40|4@1+ (1,0) [0|15] ""  gtw
 SG_ DAS_sw053_a34steerAngSpdValidity m53 : 40|1@1+ (1,0) [0|1] ""  gtw
 SG_ DAS_sw017_numTransportErrors m17 : 40|8@1+ (1,0) [0|255] ""  gtw
 SG_ DAS_sw141_temperature m141 : 40|8@1- (1,0) [-128|127] "degC"  gtw
 SG_ DAS_sw063_detectedMinorVer m63 : 40|8@1+ (1,0) [0|255] ""  gtw
 SG_ DAS_sw040_epas_internal_sas m40 : 40|8@1+ (1,-128) [-128|127] "deg"  gtw
 SG_ DAS_sw073_freespaceLeftC1 m73 : 40|8@1+ (0.0016,-0.2) [-0.2|0.2] "rad"  gtw
 SG_ DAS_sw021_currentTemperature m21 : 40|8@1- (1,0) [-128|127] "degC"  gtw
 SG_ DAS_sw227_ambientTemperature m227 : 40|8@1+ (0.5,-40) [-40|87.5] "C"  gtw
 SG_ DAS_sw013_numNaksReceived m13 : 40|8@1+ (1,0) [0|255] ""  gtw
 SG_ DAS_sw074_ipsoRCS m74 : 40|8@1+ (1,0) [0|255] "dB"  gtw
 SG_ DAS_sw080_road_class m80 : 40|3@1+ (1,0) [0|7] ""  gtw
 SG_ DAS_sw015_FoggyLights m15 : 40|2@1+ (1,0) [0|3] ""  gtw
 SG_ DAS_sw103_objectDz m103 : 40|8@1+ (0.25,-5) [-5|10.75] "m"  gtw
 SG_ DAS_sw054_unusedByte m54 : 40|8@1+ (1,0) [0|255] ""  gtw
 SG_ DAS_sw086_ellipseOverlap m86 : 40|8@1+ (0.1,-12.5) [-12.5|12.5] "m"  gtw
 SG_ DAS_sw201_vehSpeed m201 : 40|8@1+ (1,0) [0|255] "kph"  gtw
 SG_ DAS_sw016_hostSpeed m16 : 40|8@1+ (1,0) [0|255] "kph"  gtw
 SG_ DAS_sw071_roadClass m71 : 40|3@1+ (1,0) [0|7] ""  gtw
 SG_ DAS_sw006_brakePedal m6 : 40|1@1+ (1,0) [0|1] ""  gtw
 SG_ DAS_sw076_hostSpeed m76 : 40|8@1+ (1,0) [0|255] "kph"  gtw
 SG_ DAS_sw195_sdiSystemStatus m195 : 39|1@1+ (1,0) [0|1] ""  gtw
 SG_ DAS_sw027_Unused_Bit_4 m27 : 39|1@1+ (1,0) [0|1] ""  gtw
 SG_ DAS_sw005_fcmSensitivity m5 : 39|1@1+ (1,0) [0|1] ""  gtw
 SG_ DAS_sw006_radSGUFailure m6 : 39|1@1+ (1,0) [0|1] ""  gtw
 SG_ DAS_sw202_sdiSystemStatus m202 : 39|1@1+ (1,0) [0|1] ""  gtw
 SG_ DAS_sw053_a33steerAngValidity m53 : 39|1@1+ (1,0) [0|1] ""  gtw
 SG_ DAS_sw004_DASFeaturesDisabled m4 : 39|1@1+ (1,0) [0|1] ""  gtw
 SG_ DAS_sw231_targetRelVelocity m231 : 39|6@1+ (0.5,0) [0|31.5] "m/s"  gtw
 SG_ DAS_sw006_radSensorBlind m6 : 38|1@1+ (1,0) [0|1] ""  gtw
 SG_ DAS_sw025_bottsDotsUsage m25 : 38|2@1+ (1,0) [0|3] ""  gtw
 SG_ DAS_sw027_LVD_2v7_IO m27 : 38|1@1+ (1,0) [0|1] ""  gtw
 SG_ DAS_sw015_SmearedHalos m15 : 38|2@1+ (1,0) [0|3] ""  gtw
 SG_ DAS_sw005_accelPedal m5 : 38|1@1+ (1,0) [0|1] ""  gtw
 SG_ DAS_sw004_diSpeedInvalid m4 : 38|1@1+ (1,0) [0|1] ""  gtw
 SG_ DAS_sw053_a32gearValidity m53 : 38|1@1+ (1,0) [0|1] ""  gtw
 SG_ DAS_sw053_a31odoValidity m53 : 37|1@1+ (1,0) [0|1] ""  gtw
 SG_ DAS_sw005_longAccel m5 : 37|1@1+ (1,0) [0|1] ""  gtw
 SG_ DAS_sw027_LVD_2v7_Flash m27 : 37|1@1+ (1,0) [0|1] ""  gtw
 SG_ DAS_sw077_vehicleSpeed m77 : 37|10@1+ (0.05,-25) [-25|26.15] "MPH"  gtw
 SG_ DAS_sw004_accelerationInvalid m4 : 37|1@1+ (1,0) [0|1] ""  gtw
 SG_ DAS_sw195_sdiSystemNoise m195 : 37|2@1+ (1,0) [0|3] ""  gtw
 SG_ DAS_sw011_scaSteerAngle m11 : 37|10@1+ (0.1,-51.2) [-51.2|51.1] "deg"  gtw
 SG_ DAS_sw202_sdiSystemNoise m202 : 37|2@1+ (1,0) [0|3] ""  gtw
 SG_ DAS_sw006_radHWFailure m6 : 37|1@1+ (1,0) [0|1] ""  gtw
 SG_ DAS_sw010_VerticalMisalignment m10 : 36|10@1+ (0.087977,-45) [-45|45.000471] "deg"  gtw
 SG_ DAS_sw072_vehicleHeading m72 : 36|10@1+ (0.005,-2.56) [-2.56|2.55] "rad"  gtw
 SG_ DAS_sw026_can_mean_utilization m26 : 36|7@1+ (1,0) [0|127] "percent"  gtw
 SG_ DAS_sw025_modelUsage m25 : 36|2@1+ (1,0) [0|3] ""  gtw
 SG_ DAS_sw027_LVD_2v7_VREG m27 : 36|1@1+ (1,0) [0|1] ""  gtw
 SG_ DAS_sw004_stwAngleInvalid m4 : 36|1@1+ (1,0) [0|1] ""  gtw
 SG_ DAS_sw042_epas_error_code m42 : 36|4@1+ (1,0) [0|15] ""  gtw
 SG_ DAS_sw006_radMia m6 : 36|1@1+ (1,0) [0|1] ""  gtw
 SG_ DAS_sw005_yaw m5 : 36|1@1+ (1,0) [0|1] ""  gtw
 SG_ DAS_sw041_ego_speed m41 : 36|10@1+ (0.05,0) [0|51.15] "m/s"  gtw
 SG_ DAS_sw194_numObstacles m194 : 36|4@1+ (1,0) [0|15] ""  gtw
 SG_ DAS_sw053_a30longAccValidity m53 : 36|1@1+ (1,0) [0|1] ""  gtw
 SG_ DAS_sw015_SmearedSpots m15 : 36|2@1+ (1,0) [0|3] ""  gtw
 SG_ DAS_sw005_blinkers m5 : 35|1@1+ (1,0) [0|1] ""  gtw
 SG_ DAS_sw077_oocHeight m77 : 35|2@1+ (1,0) [0|3] ""  gtw
 SG_ DAS_sw004_accelPedalInvalid m4 : 35|1@1+ (1,0) [0|1] ""  gtw
 SG_ DAS_sw027_Unused_Bit_3 m27 : 35|1@1+ (1,0) [0|1] ""  gtw
 SG_ DAS_sw085_leftLaneExist m85 : 35|6@1+ (2,0) [0|128] "%"  gtw
 SG_ DAS_sw006_accelPedal m6 : 35|1@1+ (1,0) [0|1] ""  gtw
 SG_ DAS_sw053_a29longAccOffValidity m53 : 35|1@1+ (1,0) [0|1] ""  gtw
 SG_ DAS_sw177_fisheyeCamExtYawCal m177 : 34|9@1- (0.05,0.0) [-12.5|12.5] "deg"  gtw
 SG_ DAS_sw051_unusedBits m51 : 34|6@1+ (1,0) [0|63] ""  gtw
 SG_ DAS_sw053_a28espValidity m53 : 34|1@1+ (1,0) [0|1] ""  gtw
 SG_ DAS_sw181_rRepeatCamExtYawCal m181 : 34|9@1- (0.05,0.0) [-12.5|12.5] "deg"  gtw
 SG_ DAS_sw006_seatbelt m6 : 34|1@1+ (1,0) [0|1] ""  gtw
 SG_ DAS_sw142_problemCamPosition m142 : 34|4@1+ (1,0) [0|15] ""  gtw
 SG_ DAS_sw178_lPillarCamExtYawCal m178 : 34|9@1- (0.05,0.0) [-12.5|12.5] "deg"  gtw
 SG_ DAS_sw131_mainCamExtYawCal m131 : 34|9@1- (0.05,0.0) [-12.5|12.5] "deg"  gtw
 SG_ DAS_sw005_stabilityControl m5 : 34|1@1+ (1,0) [0|1] ""  gtw
 SG_ DAS_sw015_Splashes m15 : 34|2@1+ (1,0) [0|3] ""  gtw
 SG_ DAS_sw050_targetOverlap m50 : 34|6@1+ (0.1,0) [0|6.3] "m"  gtw
 SG_ DAS_sw012_mespFatalErrCode m12 : 34|8@1+ (1,0) [0|255] ""  gtw
 SG_ DAS_sw076_targetOverlap m76 : 34|6@1+ (0.1,0) [0|6.3] "m"  gtw
 SG_ DAS_sw060_targetOverlap m60 : 34|6@1+ (0.1,0) [0|6.3] "m"  gtw
 SG_ DAS_sw004_diMIA m4 : 34|1@1+ (1,0) [0|1] ""  gtw
 SG_ DAS_sw027_Watchdog m27 : 34|1@1+ (1,0) [0|1] ""  gtw
 SG_ DAS_sw179_rPillarCamExtYawCal m179 : 34|9@1- (0.05,0.0) [-12.5|12.5] "deg"  gtw
 SG_ DAS_sw132_narrowCamExtYawCal m132 : 34|9@1- (0.05,0.0) [-12.5|12.5] "deg"  gtw
 SG_ DAS_sw025_navigationUsage m25 : 34|2@1+ (1,0) [0|3] ""  gtw
 SG_ DAS_sw016_targetOverlap m16 : 34|6@1+ (0.1,0) [0|6.3] "m"  gtw
 SG_ DAS_sw180_lRepeatCamExtYawCal m180 : 34|9@1- (0.05,0.0) [-12.5|12.5] "deg"  gtw
 SG_ DAS_sw004_diCruiseStateFault m4 : 33|1@1+ (1,0) [0|1] ""  gtw
 SG_ DAS_sw006_blinkers m6 : 33|1@1+ (1,0) [0|1] ""  gtw
 SG_ DAS_sw027_Unused_Bit_2 m27 : 33|1@1+ (1,0) [0|1] ""  gtw
 SG_ DAS_sw005_gear m5 : 33|1@1+ (1,0) [0|1] ""  gtw
 SG_ DAS_sw203_slotSizeY m203 : 33|8@1+ (4,0) [0|1020] "cm"  gtw
 SG_ DAS_sw051_SGUFail m51 : 33|1@1+ (1,0) [0|1] ""  gtw
 SG_ DAS_sw053_a27CntryCdValidity m53 : 33|1@1+ (1,0) [0|1] ""  gtw
 SG_ DAS_sw070_temperature m70 : 32|8@1+ (0.5,-40) [-40|87.5] "C"  gtw
 SG_ DAS_sw066_unusedW0 m66 : 32|16@1+ (1,0) [0|65535] ""  gtw
 SG_ DAS_sw031_errorData1 m31 : 32|16@1+ (1,0) [0|65535] ""  gtw
 SG_ DAS_sw085_roadClass m85 : 32|3@1+ (1,0) [0|7] ""  gtw
 SG_ DAS_sw207_lcUnavailableReason m207 : 32|8@1+ (1,0) [0|255] ""  gtw
 SG_ DAS_sw061_unusedW0 m61 : 32|16@1+ (1,0) [0|65535] ""  gtw
 SG_ DAS_sw205_rrLeftMiddle m205 : 32|8@1+ (1,0) [0|255] "cm"  gtw
 SG_ DAS_sw075_unusedW0 m75 : 32|16@1+ (1,0) [0|65535] ""  gtw
 SG_ DAS_sw202_sdiRearCC m202 : 32|5@1+ (1,0) [0|31] ""  gtw
 SG_ DAS_sw028_highestSeqRcvd m28 : 32|16@1+ (1,0) [0|65535] ""  gtw
 SG_ DAS_sw018_maxThreshold m18 : 32|15@1+ (1,50) [50|5500] "mV"  gtw
 SG_ DAS_sw231_targetDistance m231 : 32|7@1+ (0.1,0) [0|12.7] "m"  gtw
 SG_ DAS_sw103_objectDy m103 : 32|8@1+ (0.5,-15.5) [-15.5|16] "m"  gtw
 SG_ DAS_sw086_ellipseWidth m86 : 32|8@1+ (0.1,0) [0|25.5] "m"  gtw
 SG_ DAS_sw005_speed m5 : 32|1@1+ (1,0) [0|1] ""  gtw
 SG_ DAS_sw047_edrReturn m47 : 32|16@1+ (1,0) [0|65535] ""  gtw
 SG_ DAS_sw213_startSpeed m213 : 32|10@1+ (0.1,-10) [-10|92.3] "m/s"  gtw
 SG_ DAS_sw037_unusedW0 m37 : 32|16@1+ (1,0) [0|65535] ""  gtw
 SG_ DAS_sw204_frMiddle m204 : 32|8@1+ (1,0) [0|255] "cm"  gtw
 SG_ DAS_sw046_errorCode m46 : 32|32@1+ (1,0) [0|4294967295] ""  gtw
 SG_ DAS_sw080_stw_angle_deg m80 : 32|8@1+ (1,0) [0|255] "deg"  gtw
 SG_ DAS_sw015_AutofixOOfCalibHorizon m15 : 32|2@1+ (1,0) [0|3] ""  gtw
 SG_ DAS_sw044_timestampms m44 : 32|32@1+ (1,0) [0|4294967295] "ms"  gtw
 SG_ DAS_sw032_errorData1 m32 : 32|16@1+ (1,0) [0|65535] ""  gtw
 SG_ DAS_sw065_unusedW0 m65 : 32|16@1+ (1,0) [0|65535] ""  gtw
 SG_ DAS_sw078_radarTarg5_dx m78 : 32|8@1+ (0.0625,0) [0|15.9375] "m"  gtw
 SG_ DAS_sw063_expectedMinorVer m63 : 32|8@1+ (1,0) [0|255] ""  gtw
 SG_ DAS_sw200_startSpeed m200 : 32|10@1+ (0.1,-10) [-10|92.3] "m/s"  gtw
 SG_ DAS_sw083_Targ5_dx m83 : 32|12@1+ (0.0625,0) [0|255.9375] "m"  gtw
 SG_ DAS_sw019_timeStamp m19 : 32|32@1+ (1,0) [0|4294967295] "ms"  gtw
 SG_ DAS_sw058_unusedW0 m58 : 32|16@1+ (1,0) [0|65535] ""  gtw
 SG_ DAS_sw053_a26brakeValidity m53 : 32|1@1+ (1,0) [0|1] ""  gtw
 SG_ DAS_sw218_pedalPosition m218 : 32|7@1+ (1,0) [0|127] "%"  gtw
 SG_ DAS_sw081_cameraDistance m81 : 32|8@1+ (0.0625,0) [0|15.9375] "m"  gtw
 SG_ DAS_sw033_unusedW0 m33 : 32|16@1+ (1,0) [0|65535] ""  gtw
 SG_ DAS_sw141_tempSensorId m141 : 32|8@1+ (1,0) [0|255] ""  gtw
 SG_ DAS_sw024_taskProgramCounter m24 : 32|32@1+ (1,0) [0|4294967295] ""  gtw
 SG_ DAS_sw043_mesp_health_main_state m43 : 32|16@1+ (1,0) [0|65535] ""  gtw
 SG_ DAS_sw011_scaSonicDist m11 : 32|5@1+ (0.05,0) [0|1.5] "m"  gtw
 SG_ DAS_sw029_highestSeqRcvd m29 : 32|16@1+ (1,0) [0|65535] ""  gtw
 SG_ DAS_sw017_numSeqErrors m17 : 32|8@1+ (1,0) [0|255] ""  gtw
 SG_ DAS_sw034_unusedW0 m34 : 32|16@1+ (1,0) [0|65535] ""  gtw
 SG_ DAS_sw027_LVD_1v2 m27 : 32|1@1+ (1,0) [0|1] ""  gtw
 SG_ DAS_sw201_timeHorizon m201 : 32|8@1+ (0.1,0) [0|25.5] "s"  gtw
 SG_ DAS_sw039_unusedW0 m39 : 32|16@1+ (1,0) [0|65535] ""  gtw
 SG_ DAS_sw040_das_steering_req m40 : 32|8@1+ (1,-128) [-128|127] "deg"  gtw
 SG_ DAS_sw054_Autofix_yaw m54 : 32|8@1+ (1,0) [0|255] ""  gtw
 SG_ DAS_sw051_HWFail m51 : 32|1@1+ (1,0) [0|1] ""  gtw
 SG_ DAS_sw042_state_before_abort m42 : 32|4@1+ (1,0) [0|15] ""  gtw
 SG_ DAS_sw014_lineNumberInCode m14 : 32|16@1+ (1,0) [0|65535] ""  gtw
 SG_ DAS_sw045_unusedW0 m45 : 32|16@1+ (1,0) [0|65535] ""  gtw
 SG_ DAS_sw025_hppUsage m25 : 32|2@1+ (1,0) [0|3] ""  gtw
 SG_ DAS_sw059_unusedW0 m59 : 32|16@1+ (1,0) [0|65535] ""  gtw
 SG_ DAS_sw012_bootDDRTempStatus m12 : 32|2@1+ (1,0) [0|3] ""  gtw
 SG_ DAS_sw073_freespaceRightC0 m73 : 32|8@1+ (0.1,-12.8) [-12.8|12.7] "m"  gtw
 SG_ DAS_sw195_sdiRearCC m195 : 32|5@1+ (1,0) [0|31] ""  gtw
 SG_ DAS_sw049_app_version_msw m49 : 32|16@1+ (1,0) [0|65535] ""  gtw
 SG_ DAS_sw082_L_Lane m82 : 32|8@1+ (0.05,-6.4) [-6.4|6.35] "m"  gtw
 SG_ DAS_sw006_SelfGlare m6 : 32|1@1+ (1,0) [0|1] ""  gtw
 SG_ DAS_sw030_unusedW0 m30 : 32|16@1+ (1,0) [0|65535] ""  gtw
 SG_ DAS_sw021_maxThreshold m21 : 32|8@1- (1,0) [-128|127] "degC"  gtw
 SG_ DAS_sw013_numSeqErrors m13 : 32|8@1+ (1,0) [0|255] ""  gtw
 SG_ DAS_sw074_ipsoDz m74 : 32|6@1+ (0.2,-6.4) [-6.4|6.2] "m"  gtw
 SG_ DAS_sw020_unusedW1 m20 : 32|16@1+ (1,0) [0|65535] ""  gtw
 SG_ DAS_sw056_unusedW0 m56 : 32|16@1+ (1,0) [0|65535] ""  gtw
 SG_ DAS_sw084_ipsoDx m84 : 32|8@1+ (0.1,0) [0|25.5] "meters"  gtw
 SG_ DAS_sw022_errorCode m22 : 32|32@1+ (1,0) [0|4294967295] ""  gtw
 SG_ DAS_sw035_unusedW0 m35 : 32|16@1+ (1,0) [0|65535] ""  gtw
 SG_ DAS_sw062_VerticalMisalignment m62 : 32|10@1+ (0.087977,-45) [-45|45.000471] "deg"  gtw
 SG_ DAS_sw036_unusedW0 m36 : 32|16@1+ (1,0) [0|65535] ""  gtw
 SG_ DAS_sw077_oocCollisionSide m77 : 32|3@1+ (1,0) [0|7] ""  gtw
 SG_ DAS_sw005_steeringAngleRate m5 : 31|1@1+ (1,0) [0|1] ""  gtw
 SG_ DAS_sw200_epasHandsOnDetected m200 : 31|1@1+ (1,0) [0|1] ""  gtw
 SG_ DAS_sw213_epasHandsOnDetected m213 : 31|1@1+ (1,0) [0|1] ""  gtw
 SG_ DAS_sw006_FoggyLights m6 : 31|1@1+ (1,0) [0|1] ""  gtw
 SG_ DAS_sw018_powerSequnceError m18 : 31|1@1+ (1,0) [0|1] ""  gtw
 SG_ DAS_sw053_a25ambTValidity m53 : 31|1@1+ (1,0) [0|1] ""  gtw
 SG_ DAS_sw069_torsionBar m69 : 30|12@1+ (0.01,-20.5) [-20.5|20.45] "Nm"  gtw
 SG_ DAS_sw015_AutofixOutOfCalibYaw m15 : 30|2@1+ (1,0) [0|3] ""  gtw
 SG_ DAS_sw047_edrBlackBox m47 : 30|2@1+ (1,0) [0|3] ""  gtw
 SG_ DAS_sw006_SmearedHalos m6 : 30|1@1+ (1,0) [0|1] ""  gtw
 SG_ DAS_sw227_sensorMeasurement m227 : 30|9@1+ (1,0) [0|511] "cm"  gtw
 SG_ DAS_sw053_a24absValidity m53 : 30|1@1+ (1,0) [0|1] ""  gtw
 SG_ DAS_sw071_endPosY m71 : 30|10@1+ (0.05,-25.6) [-25.6|25.5] "m"  gtw
 SG_ DAS_sw005_steeringAngle m5 : 30|1@1+ (1,0) [0|1] ""  gtw
 SG_ DAS_sw067_epasSTW m67 : 30|14@1+ (0.1,-819.2) [-819.2|819] "deg"  gtw
 SG_ DAS_sw194_leadVx m194 : 30|6@1- (0.2,0.0) [-6|6] "m/s"  gtw
 SG_ DAS_sw025_vehiclesUsage m25 : 29|2@1+ (1,0) [0|3] ""  gtw
 SG_ DAS_sw069_parkCal m69 : 29|1@1+ (1,0) [0|1] ""  gtw
 SG_ DAS_sw218_mcuAutosteerRestricted m218 : 29|1@1+ (1,0) [0|1] ""  gtw
 SG_ DAS_sw006_FullBlockage m6 : 29|1@1+ (1,0) [0|1] ""  gtw
 SG_ DAS_sw018_railID m18 : 29|2@1+ (1,0) [0|3] ""  gtw
 SG_ DAS_sw053_a23sccmInvalidChkSm m53 : 29|1@1+ (1,0) [0|1] ""  gtw
 SG_ DAS_sw005_brakePedal m5 : 29|1@1+ (1,0) [0|1] ""  gtw
 SG_ DAS_sw006_AutofixOutOfCalibYaw m6 : 28|1@1+ (1,0) [0|1] ""  gtw
 SG_ DAS_sw044_meMainState m44 : 28|4@1+ (1,0) [0|15] ""  gtw
 SG_ DAS_sw048_parkerIssue m48 : 28|1@1+ (1,0) [0|1] ""  gtw
 SG_ DAS_sw027_Unused_Nibble m27 : 28|4@1+ (1,0) [0|15] ""  gtw
 SG_ DAS_sw015_AutofixOutOfCalib m15 : 28|2@1+ (1,0) [0|3] ""  gtw
 SG_ DAS_sw140_backupCamHDMISerFault m140 : 28|1@1+ (1,0) [0|1] ""  gtw
 SG_ DAS_sw005_radCalibration m5 : 28|1@1+ (1,0) [0|1] ""  gtw
 SG_ DAS_sw070_accRail m70 : 28|1@1+ (1,0) [0|1] ""  gtw
 SG_ DAS_sw004_appMobileyeStatus m4 : 28|5@1+ (1,0) [0|31] ""  gtw
 SG_ DAS_sw053_a22sccmInvalidChkSm m53 : 28|1@1+ (1,0) [0|1] ""  gtw
 SG_ DAS_sw025_rightLaneUsage m25 : 27|2@1+ (1,0) [0|3] ""  gtw
 SG_ DAS_sw230_sensor12Blocked m230 : 27|1@1+ (1,0) [0|1] ""  gtw
 SG_ DAS_sw026_execution_time m26 : 27|9@1+ (0.125,0) [0|65.411] "ms"  gtw
 SG_ DAS_sw027_f_PLL_1_Off m27 : 27|1@1+ (1,0) [0|1] ""  gtw
 SG_ DAS_sw048_camIssue m48 : 27|1@1+ (1,0) [0|1] ""  gtw
 SG_ DAS_sw005_radMia m5 : 27|1@1+ (1,0) [0|1] ""  gtw
 SG_ DAS_sw070_driveRail m70 : 27|1@1+ (1,0) [0|1] ""  gtw
 SG_ DAS_sw053_a21espInvalidChkSm m53 : 27|1@1+ (1,0) [0|1] ""  gtw
 SG_ DAS_sw140_backupCamUARTbusFault m140 : 27|1@1+ (1,0) [0|1] ""  gtw
 SG_ DAS_sw006_AutofixOutOfCalibHorzn m6 : 27|1@1+ (1,0) [0|1] ""  gtw
 SG_ DAS_sw072_vehicleY m72 : 26|10@1+ (0.05,-25.6) [-25.6|25.5] "m"  gtw
 SG_ DAS_sw068_virtualLaneSTW m68 : 26|14@1+ (0.1,-819.2) [-819.2|819.2] "deg"  gtw
 SG_ DAS_sw017_numCrcErrors m17 : 26|6@1+ (1,0) [0|63] ""  gtw
 SG_ DAS_sw015_PartialBlockage m15 : 26|2@1+ (1,0) [0|3] ""  gtw
 SG_ DAS_sw005_radSGUFailure m5 : 26|1@1+ (1,0) [0|1] ""  gtw
 SG_ DAS_sw006_AutofixOutOfCalib m6 : 26|1@1+ (1,0) [0|1] ""  gtw
 SG_ DAS_sw041_max_rate m41 : 26|10@1- (1,0) [-512|511] "deg/s"  gtw
 SG_ DAS_sw048_eyeQVersionMismatch m48 : 26|1@1+ (1,0) [0|1] ""  gtw
 SG_ DAS_sw230_sensor11Blocked m230 : 26|1@1+ (1,0) [0|1] ""  gtw
 SG_ DAS_sw027_Unused_Bit_1 m27 : 26|1@1+ (1,0) [0|1] ""  gtw
 SG_ DAS_sw199_currentSTW m199 : 26|14@1+ (0.1,-819.2) [-819.2|819] "deg"  gtw
 SG_ DAS_sw053_a20bdyInvalidChkSm m53 : 26|1@1+ (1,0) [0|1] ""  gtw
 SG_ DAS_sw060_targetRelSpeed m60 : 25|9@1+ (0.0625,-31) [-31|0.9375] "m/s"  gtw
 SG_ DAS_sw177_fisheyeCamExtRollCal m177 : 25|9@1- (0.05,0.0) [-12.5|12.5] "deg"  gtw
 SG_ DAS_sw005_radSensorBlind m5 : 25|1@1+ (1,0) [0|1] ""  gtw
 SG_ DAS_sw179_rPillarCamExtRollCal m179 : 25|9@1- (0.05,0.0) [-12.5|12.5] "deg"  gtw
 SG_ DAS_sw132_narrowCamExtRollCal m132 : 25|9@1- (0.05,0.0) [-12.5|12.5] "deg"  gtw
 SG_ DAS_sw016_targetRelSpeed m16 : 25|9@1+ (0.0625,-31) [-31|0.9375] "m/s"  gtw
 SG_ DAS_sw025_leftLaneUsage m25 : 25|2@1+ (1,0) [0|3] ""  gtw
 SG_ DAS_sw006_PartialBlockage m6 : 25|1@1+ (1,0) [0|1] ""  gtw
 SG_ DAS_sw077_oocConfidence m77 : 25|7@1+ (1,0) [0|100] "%"  gtw
 SG_ DAS_sw131_mainCamExtRollCal m131 : 25|9@1- (0.05,0.0) [-12.5|12.5] "deg"  gtw
 SG_ DAS_sw178_lPillarCamExtRollCal m178 : 25|9@1- (0.05,0.0) [-12.5|12.5] "deg"  gtw
 SG_ DAS_sw230_sensor10Blocked m230 : 25|1@1+ (1,0) [0|1] ""  gtw
 SG_ DAS_sw053_a19sccmInvalidCount m53 : 25|1@1+ (1,0) [0|1] ""  gtw
 SG_ DAS_sw142_pitchOffsetAtmptVal m142 : 25|9@1+ (1,-256) [-256|255] "pixels"  gtw
 SG_ DAS_sw027_PLL_1_Failure m27 : 25|1@1+ (1,0) [0|1] ""  gtw
 SG_ DAS_sw076_targetRelSpeed m76 : 25|9@1+ (0.0625,-31) [-31|0.9375] "m/s"  gtw
 SG_ DAS_sw069_diAPState m69 : 25|4@1+ (1,0) [0|9] ""  gtw
 SG_ DAS_sw180_lRepeatCamExtRollCal m180 : 25|9@1- (0.05,0.0) [-12.5|12.5] "deg"  gtw
 SG_ DAS_sw057_phoneLocStatusMia m57 : 25|1@1+ (1,0) [0|1] ""  gtw
 SG_ DAS_sw017_Any_TFL_Msg_Recd m17 : 25|1@1+ (1,0) [0|1] ""  gtw
 SG_ DAS_sw203_slotSizeX m203 : 25|8@1+ (4,0) [0|1020] "cm"  gtw
 SG_ DAS_sw050_targetRelSpeed m50 : 25|9@1+ (0.0625,-31) [-31|0.9375] "m/s"  gtw
 SG_ DAS_sw181_rRepeatCamExtRollCal m181 : 25|9@1- (0.05,0.0) [-12.5|12.5] "deg"  gtw
 SG_ DAS_sw048_radcMia m48 : 25|1@1+ (1,0) [0|1] ""  gtw
 SG_ DAS_sw218_handsOnState m218 : 25|4@1+ (1,0) [0|15] ""  gtw
 SG_ DAS_sw231_predImpactVelocity m231 : 25|7@1+ (0.5,0) [0|63.5] "m/s"  gtw
 SG_ DAS_sw136_lPillarCamSerFault m136 : 24|3@1+ (1,0) [0|7] ""  gtw
 SG_ DAS_sw074_ipsoDy m74 : 24|6@1+ (0.1,-3.2) [-3.2|3.1] "m"  gtw
 SG_ DAS_sw042_view_range m42 : 24|8@1+ (1,0) [0|255] ""  gtw
 SG_ DAS_sw070_diGear m70 : 24|3@1+ (1,0) [0|7] ""  gtw
 SG_ DAS_sw135_fisheyeCamSerFault m135 : 24|3@1+ (1,0) [0|7] ""  gtw
 SG_ DAS_sw084_ipsoRCS m84 : 24|8@1+ (1,0) [0|255] ""  gtw
 SG_ DAS_sw019_numFreeBytes m19 : 24|8@1+ (1,-191) [-191|64] "# of bytes"  gtw
 SG_ DAS_sw036_unusedByte m36 : 24|8@1+ (1,0) [0|255] ""  gtw
 SG_ DAS_sw065_mobileye_main_state m65 : 24|8@1+ (1,0) [0|255] ""  gtw
 SG_ DAS_sw075_unusedByte m75 : 24|8@1+ (1,0) [0|255] ""  gtw
 SG_ DAS_sw201_stwAngleReq m201 : 24|8@1- (1,0) [-128|127] "deg"  gtw
 SG_ DAS_sw006_SmearedSpots m6 : 24|1@1+ (1,0) [0|1] ""  gtw
 SG_ DAS_sw078_ttc m78 : 24|8@1+ (0.02,0) [0|5.11] "seconds"  gtw
 SG_ DAS_sw205_rrLeft m205 : 24|8@1+ (1,0) [0|255] "cm"  gtw
 SG_ DAS_sw061_unusedByte m61 : 24|8@1+ (1,0) [0|255] ""  gtw
 SG_ DAS_sw032_errorType m32 : 24|8@1+ (1,0) [0|2] ""  gtw
 SG_ DAS_sw063_detectedMajorVer m63 : 24|8@1+ (1,0) [0|255] ""  gtw
 SG_ DAS_sw054_Autofix_horizon m54 : 24|8@1+ (1,0) [0|255] ""  gtw
 SG_ DAS_sw195_sdiFrontCC m195 : 24|5@1+ (1,0) [0|31] ""  gtw
 SG_ DAS_sw059_unusedByte m59 : 24|8@1+ (1,0) [0|255] ""  gtw
 SG_ DAS_sw218_drivingOnHighway m218 : 24|1@1+ (1,0) [0|1] ""  gtw
 SG_ DAS_sw207_eyeq3MainState m207 : 24|8@1+ (1,0) [0|255] ""  gtw
 SG_ DAS_sw048_radcCalibration m48 : 24|1@1+ (1,0) [0|1] ""  gtw
 SG_ DAS_sw202_sdiFrontCC m202 : 24|5@1+ (1,0) [0|31] ""  gtw
 SG_ DAS_sw086_distanceEllipse m86 : 24|8@1+ (0.5,0) [0|127.5] "m"  gtw
 SG_ DAS_sw045_unusedByte m45 : 24|8@1+ (1,0) [0|255] ""  gtw
 SG_ DAS_sw134_narrowCamSerFault m134 : 24|3@1+ (1,0) [0|7] ""  gtw
 SG_ DAS_sw035_unusedByte m35 : 24|8@1+ (1,0) [0|255] ""  gtw
 SG_ DAS_sw138_lRepeatCamSerFault m138 : 24|3@1+ (1,0) [0|7] ""  gtw
 SG_ DAS_sw056_unusedByte m56 : 24|8@1+ (1,0) [0|255] ""  gtw
 SG_ DAS_sw082_R_VL m82 : 24|8@1+ (0.05,-6.4) [-6.4|6.35] "m"  gtw
 SG_ DAS_sw030_unusedByte m30 : 24|8@1+ (1,0) [0|255] ""  gtw
 SG_ DAS_sw044_appStatus m44 : 24|4@1+ (1,0) [0|15] ""  gtw
 SG_ DAS_sw015_FullBlockage m15 : 24|2@1+ (1,0) [0|3] ""  gtw
 SG_ DAS_sw040_ego_veh_speed m40 : 24|8@1+ (0.2,0) [0|51] "m/s"  gtw
 SG_ DAS_sw051_SCUTemperature m51 : 24|8@1- (1,0) [-128|127] ""  gtw
 SG_ DAS_sw021_minThreshold m21 : 24|8@1- (1,0) [-128|127] "degC"  gtw
 SG_ DAS_sw033_unusedByte m33 : 24|8@1+ (1,0) [0|255] ""  gtw
 SG_ DAS_sw081_radarTTC m81 : 24|8@1+ (0.02,0) [0|5.11] "seconds"  gtw
 SG_ DAS_sw011_scaSpeed m11 : 24|7@1+ (1,0) [0|127] "MPH"  gtw
 SG_ DAS_sw027_Flash_Fatal_Error m27 : 24|1@1+ (1,0) [0|1] ""  gtw
 SG_ DAS_sw133_mainCamSerFault m133 : 24|3@1+ (1,0) [0|7] ""  gtw
 SG_ DAS_sw058_unusedByte m58 : 24|8@1+ (1,0) [0|255] ""  gtw
 SG_ DAS_sw039_unusedByte m39 : 24|8@1+ (1,0) [0|255] ""  gtw
 SG_ DAS_sw204_frLeftMiddle m204 : 24|8@1+ (1,0) [0|255] "cm"  gtw
 SG_ DAS_sw073_freespaceLeftC0 m73 : 24|8@1+ (0.1,-12.8) [-12.8|12.7] "m"  gtw
 SG_ DAS_sw137_rPillarCamSerFault m137 : 24|3@1+ (1,0) [0|7] ""  gtw
 SG_ DAS_sw034_unusedByte m34 : 24|8@1+ (1,0) [0|255] ""  gtw
 SG_ DAS_sw141_minThreshold m141 : 24|8@1- (1,0) [-128|127] "degC"  gtw
 SG_ DAS_sw004_accState m4 : 24|4@1+ (1,0) [0|11] ""  gtw
 SG_ DAS_sw031_errorType m31 : 24|8@1+ (1,0) [0|8] ""  gtw
 SG_ DAS_sw053_a18espInvalidCount m53 : 24|1@1+ (1,0) [0|1] ""  gtw
 SG_ DAS_sw085_radarTTC m85 : 24|8@1+ (0.02,0) [0|5.11] "seconds"  gtw
 SG_ DAS_sw057_telemetryControlMia m57 : 24|1@1+ (1,0) [0|1] ""  gtw
 SG_ DAS_sw047_edrType m47 : 24|6@1+ (1,0) [0|63] ""  gtw
 SG_ DAS_sw080_rad_tar_5_dist m80 : 24|6@1+ (1,0) [0|63] "m"  gtw
 SG_ DAS_sw139_rhtRptrCamSerFault m139 : 24|3@1+ (1,0) [0|7] ""  gtw
 SG_ DAS_sw017_Any_Objects_Msg_Recd m17 : 24|1@1+ (1,0) [0|1] ""  gtw
 SG_ DAS_sw140_backupCamSensorFault m140 : 24|3@1+ (1,0) [0|7] ""  gtw
 SG_ DAS_sw144_selfieCamSerFault m144 : 24|3@1+ (1,0) [0|7] ""  gtw
 SG_ DAS_sw066_mobileye_main_state m66 : 24|8@1+ (1,0) [0|255] ""  gtw
 SG_ DAS_sw013_numCrcErrors m13 : 24|8@1+ (1,0) [0|255] ""  gtw
 SG_ DAS_sw037_issue m37 : 24|8@1+ (1,0) [0|255] ""  gtw
 SG_ DAS_sw005_radHWFailure m5 : 24|1@1+ (1,0) [0|1] ""  gtw
 SG_ DAS_sw103_objectRCS m103 : 24|8@1+ (1,0) [0|255] ""  gtw
 SG_ DAS_sw025_controlled_access m25 : 24|1@1+ (1,0) [0|1] ""  gtw
 SG_ DAS_sw024_currentVehicleApp m24 : 24|8@1+ (1,0) [0|161] ""  gtw
 SG_ DAS_sw230_sensor9Blocked m230 : 24|1@1+ (1,0) [0|1] ""  gtw
 SG_ DAS_sw025_road_match m25 : 23|1@1+ (1,0) [0|1] ""  gtw
 SG_ DAS_sw027_LVD_4v5 m27 : 23|1@1+ (1,0) [0|1] ""  gtw
 SG_ DAS_sw017_Any_Lanes_Msg_Recd m17 : 23|1@1+ (1,0) [0|1] ""  gtw
 SG_ DAS_sw053_a17adasInvalidCount m53 : 23|1@1+ (1,0) [0|1] ""  gtw
 SG_ DAS_sw052_sensorBlocked m52 : 23|1@1+ (1,0) [0|1] ""  gtw
 SG_ DAS_sw006_LowSun m6 : 23|1@1+ (1,0) [0|1] ""  gtw
 SG_ DAS_sw230_sensor8Blocked m230 : 23|1@1+ (1,0) [0|1] ""  gtw
 SG_ DAS_sw047_controlledAccess m47 : 23|1@1+ (1,0) [0|1] ""  gtw
 SG_ DAS_sw011_scaThreshold m11 : 23|1@1+ (1,0) [0|1] ""  gtw
 SG_ DAS_sw080_pedestrian_check m80 : 23|1@1+ (1,0) [0|1] ""  gtw
 SG_ DAS_sw057_csaOfframpCurvMia m57 : 23|1@1+ (1,0) [0|1] ""  gtw
 SG_ DAS_sw005_camFcwPcwMsg m5 : 23|1@1+ (1,0) [0|1] ""  gtw
 SG_ DAS_sw048_radcVersionMismatch m48 : 23|1@1+ (1,0) [0|1] ""  gtw
 SG_ DAS_sw080_freespace_check m80 : 22|1@1+ (1,0) [0|1] ""  gtw
 SG_ DAS_sw140_backupCamI2CbusFault m140 : 22|1@1+ (1,0) [0|1] ""  gtw
 SG_ DAS_sw048_ecuReset m48 : 22|1@1+ (1,0) [0|1] ""  gtw
 SG_ DAS_sw004_espMIA m4 : 22|1@1+ (1,0) [0|1] ""  gtw
 SG_ DAS_sw203_roadClass m203 : 22|3@1+ (1,0) [0|7] ""  gtw
 SG_ DAS_sw230_sensor7Blocked m230 : 22|1@1+ (1,0) [0|1] ""  gtw
 SG_ DAS_sw053_a16bdyInvalidCount m53 : 22|1@1+ (1,0) [0|1] ""  gtw
 SG_ DAS_sw052_rspError m52 : 22|1@1+ (1,0) [0|1] ""  gtw
 SG_ DAS_sw073_freespaceLDW m73 : 22|2@1+ (1,0) [0|3] ""  gtw
 SG_ DAS_sw006_BlurredImage m6 : 22|1@1+ (1,0) [0|1] ""  gtw
 SG_ DAS_sw194_leadDx m194 : 22|8@1+ (0.1,0) [0|25] "m"  gtw
 SG_ DAS_sw057_csaRoadCurvMia m57 : 22|1@1+ (1,0) [0|1] ""  gtw
 SG_ DAS_sw027_Clock_Monitor_0_Off m27 : 22|1@1+ (1,0) [0|1] ""  gtw
 SG_ DAS_sw193_smearedSpots m193 : 22|1@1+ (1,0) [0|1] ""  gtw
 SG_ DAS_sw015_BlurredImage m15 : 22|2@1+ (1,0) [0|3] ""  gtw
 SG_ DAS_sw038_TooManyResets m38 : 22|1@1+ (1,0) [0|1] ""  gtw
 SG_ DAS_sw017_Camera_Msg_TFL_MIA m17 : 22|1@1+ (1,0) [0|1] ""  gtw
 SG_ DAS_sw005_camCommonMsg m5 : 22|1@1+ (1,0) [0|1] ""  gtw
 SG_ DAS_sw193_smearedHalos m193 : 21|1@1+ (1,0) [0|1] ""  gtw
 SG_ DAS_sw011_scaBlinker m11 : 21|2@1+ (1,0) [0|3] ""  gtw
 SG_ DAS_sw005_camObjHeader m5 : 21|1@1+ (1,0) [0|1] ""  gtw
 SG_ DAS_sw038_FullBlockage m38 : 21|1@1+ (1,0) [0|1] ""  gtw
 SG_ DAS_sw200_endSpeed m200 : 21|10@1+ (0.1,-10) [-10|92.3] "m/s"  gtw
 SG_ DAS_sw027_Clock_Monitor_0_Low m27 : 21|1@1+ (1,0) [0|1] ""  gtw
 SG_ DAS_sw057_radarMapDataMia m57 : 21|1@1+ (1,0) [0|1] ""  gtw
 SG_ DAS_sw052_chirpError m52 : 21|1@1+ (1,0) [0|1] ""  gtw
 SG_ DAS_sw202_s12Blocked m202 : 21|1@1+ (1,0) [0|1] ""  gtw
 SG_ DAS_sw213_endSpeed m213 : 21|10@1+ (0.1,-10) [-10|92.3] "m/s"  gtw
 SG_ DAS_sw195_s12Blocked m195 : 21|1@1+ (1,0) [0|1] ""  gtw
 SG_ DAS_sw017_Camera_Msg_FCW_PCW_MIA m17 : 21|1@1+ (1,0) [0|1] ""  gtw
 SG_ DAS_sw006_Splashes m6 : 21|1@1+ (1,0) [0|1] ""  gtw
 SG_ DAS_sw069_eacStatus m69 : 21|4@1+ (1,0) [0|15] ""  gtw
 SG_ DAS_sw230_sensor6Blocked m230 : 21|1@1+ (1,0) [0|1] ""  gtw
 SG_ DAS_sw053_a15adasMIA m53 : 21|1@1+ (1,0) [0|1] ""  gtw
 SG_ DAS_sw048_ecuWatchdog m48 : 21|1@1+ (1,0) [0|1] ""  gtw
 SG_ DAS_sw028_unusedBits m28 : 21|11@1+ (1,0) [0|2047] ""  gtw
 SG_ DAS_sw013_numEyeqResets m13 : 21|3@1+ (1,0) [0|7] ""  gtw
 SG_ DAS_sw051_unused m51 : 21|3@1+ (1,0) [0|7] ""  gtw
 SG_ DAS_sw004_radDynamicsError m4 : 21|1@1+ (1,0) [0|1] ""  gtw
 SG_ DAS_sw199_abortCodePARK m199 : 21|5@1+ (1,0) [0|31] ""  gtw
 SG_ DAS_sw080_ultrasonic_obs_check m80 : 21|1@1+ (1,0) [0|1] ""  gtw
 SG_ DAS_sw069_parkMismatch m69 : 20|1@1+ (1,0) [0|1] ""  gtw
 SG_ DAS_sw202_s11Blocked m202 : 20|1@1+ (1,0) [0|1] ""  gtw
 SG_ DAS_sw024_numVirtualLaneVeh m24 : 20|4@1+ (1,0) [0|15] ""  gtw
 SG_ DAS_sw006_SunRay m6 : 20|1@1+ (1,0) [0|1] ""  gtw
 SG_ DAS_sw080_rad_tar_5_check m80 : 20|1@1+ (1,0) [0|1] ""  gtw
 SG_ DAS_sw028_inv_multifrm_next m28 : 20|1@1+ (1,0) [0|1] ""  gtw
 SG_ DAS_sw133_mainCamSensorFault m133 : 20|3@1+ (1,0) [0|7] ""  gtw
 SG_ DAS_sw053_a14sccmMIA m53 : 20|1@1+ (1,0) [0|1] ""  gtw
 SG_ DAS_sw011_scaRight m11 : 20|1@1+ (1,0) [0|1] ""  gtw
 SG_ DAS_sw134_narrowCamSensorFault m134 : 20|3@1+ (1,0) [0|7] ""  gtw
 SG_ DAS_sw048_checkStop m48 : 20|1@1+ (1,0) [0|1] ""  gtw
 SG_ DAS_sw138_lRepeatCamSensorFault m138 : 20|3@1+ (1,0) [0|7] ""  gtw
 SG_ DAS_sw220_vehicleSpeed m220 : 20|12@1+ (0.05,-25) [-25|179.75] "mph"  gtw
 SG_ DAS_sw015_LowSun m15 : 20|2@1+ (1,0) [0|3] ""  gtw
 SG_ DAS_sw022_recordId m22 : 20|12@1+ (1,0) [0|4095] ""  gtw
 SG_ DAS_sw027_PLL_0_Failure m27 : 20|1@1+ (1,0) [0|1] ""  gtw
 SG_ DAS_sw071_endPosX m71 : 20|10@1+ (0.05,-25.6) [-25.6|25.5] "m"  gtw
 SG_ DAS_sw137_rPillarCamSensorFault m137 : 20|3@1+ (1,0) [0|7] ""  gtw
 SG_ DAS_sw195_s11Blocked m195 : 20|1@1+ (1,0) [0|1] ""  gtw
 SG_ DAS_sw200_autopilotRestricted m200 : 20|1@1+ (1,0) [0|1] ""  gtw
 SG_ DAS_sw038_AutofixOutOfCalibYaw m38 : 20|1@1+ (1,0) [0|1] ""  gtw
 SG_ DAS_sw073_rawMobileyeLDW m73 : 20|2@1+ (1,0) [0|3] ""  gtw
 SG_ DAS_sw052_underTemperature m52 : 20|1@1+ (1,0) [0|1] ""  gtw
 SG_ DAS_sw005_fullBlockage m5 : 20|1@1+ (1,0) [0|1] ""  gtw
 SG_ DAS_sw213_autopilotRestricted m213 : 20|1@1+ (1,0) [0|1] ""  gtw
 SG_ DAS_sw051_a52radomeHtrInop m51 : 20|1@1+ (1,0) [0|1] ""  gtw
 SG_ DAS_sw136_lPillarCamSensorFault m136 : 20|3@1+ (1,0) [0|7] ""  gtw
 SG_ DAS_sw017_Camera_Msg_Common_MIA m17 : 20|1@1+ (1,0) [0|1] ""  gtw
 SG_ DAS_sw135_fisheyeCamSensorFault m135 : 20|3@1+ (1,0) [0|7] ""  gtw
 SG_ DAS_sw144_selfieCamSensorFault m144 : 20|3@1+ (1,0) [0|7] ""  gtw
 SG_ DAS_sw057_dasRoadSignMia m57 : 20|1@1+ (1,0) [0|1] ""  gtw
 SG_ DAS_sw193_partialBlockage m193 : 20|1@1+ (1,0) [0|1] ""  gtw
 SG_ DAS_sw230_sensor5Blocked m230 : 20|1@1+ (1,0) [0|1] ""  gtw
 SG_ DAS_sw139_rhtRptrCamSensorFault m139 : 20|3@1+ (1,0) [0|7] ""  gtw
 SG_ DAS_sw203_curbType m203 : 20|2@1+ (1,0) [0|3] ""  gtw
 SG_ DAS_sw010_HorizontalMisalignment m10 : 20|16@1+ (0.00137332,-45) [-45|45.0005262] "deg"  gtw
 SG_ DAS_sw219_vehicleSpeed m219 : 20|12@1+ (0.05,-25) [-25|179.75] "mph"  gtw
 SG_ DAS_sw047_roadClass m47 : 20|3@1+ (1,0) [0|7] ""  gtw
 SG_ DAS_sw025_road_class m25 : 20|3@1+ (1,0) [0|7] ""  gtw
 SG_ DAS_sw004_radMia m4 : 20|1@1+ (1,0) [0|1] ""  gtw
 SG_ DAS_sw136_lPillarCamI2CbusFault m136 : 19|1@1+ (1,0) [0|1] ""  gtw
 SG_ DAS_sw135_fisheyeCamI2CbusFault m135 : 19|1@1+ (1,0) [0|1] ""  gtw
 SG_ DAS_sw230_sensor4Blocked m230 : 19|1@1+ (1,0) [0|1] ""  gtw
 SG_ DAS_sw201_steeringErrorOAL m201 : 19|3@1+ (1,0) [0|7] ""  gtw
 SG_ DAS_sw005_partialBlockage m5 : 19|1@1+ (1,0) [0|1] ""  gtw
 SG_ DAS_sw137_rPillarCamI2CbusFault m137 : 19|1@1+ (1,0) [0|1] ""  gtw
 SG_ DAS_sw017_Camera_Msg_Hlb_MIA m17 : 19|1@1+ (1,0) [0|1] ""  gtw
 SG_ DAS_sw051_a09configMismatch m51 : 19|1@1+ (1,0) [0|1] ""  gtw
 SG_ DAS_sw006_OutOfFocusImage m6 : 19|1@1+ (1,0) [0|1] ""  gtw
 SG_ DAS_sw011_scaLeft m11 : 19|1@1+ (1,0) [0|1] ""  gtw
 SG_ DAS_sw057_gpsVehSpeedMia m57 : 19|1@1+ (1,0) [0|1] ""  gtw
 SG_ DAS_sw042_abort_reason m42 : 19|5@1+ (1,0) [0|25] ""  gtw
 SG_ DAS_sw080_stw_angle_check m80 : 19|1@1+ (1,0) [0|1] ""  gtw
 SG_ DAS_sw139_rhtRptrCamI2CbusFault m139 : 19|1@1+ (1,0) [0|1] ""  gtw
 SG_ DAS_sw144_selfieCamI2CbusFault m144 : 19|1@1+ (1,0) [0|1] ""  gtw
 SG_ DAS_sw198_tsrMsgInvalid m198 : 19|1@1+ (1,0) [0|1] ""  gtw
 SG_ DAS_sw195_s8Blocked m195 : 19|1@1+ (1,0) [0|1] ""  gtw
 SG_ DAS_sw028_inv_multifrm_id m28 : 19|1@1+ (1,0) [0|1] ""  gtw
 SG_ DAS_sw133_mainCamI2CbusFault m133 : 19|1@1+ (1,0) [0|1] ""  gtw
 SG_ DAS_sw140_backupCamDeserFault m140 : 19|3@1+ (1,0) [0|7] ""  gtw
 SG_ DAS_sw202_s8Blocked m202 : 19|1@1+ (1,0) [0|1] ""  gtw
 SG_ DAS_sw069_sccmMia m69 : 19|1@1+ (1,0) [0|1] ""  gtw
 SG_ DAS_sw010_a08PlantMode m10 : 19|1@1+ (1,0) [0|1] ""  gtw
 SG_ DAS_sw053_a13gtwMIA m53 : 19|1@1+ (1,0) [0|1] ""  gtw
 SG_ DAS_sw004_radSGUFailure m4 : 19|1@1+ (1,0) [0|1] ""  gtw
 SG_ DAS_sw193_outOfFocusImage m193 : 19|1@1+ (1,0) [0|1] ""  gtw
 SG_ DAS_sw038_AutofixOutOfCalibHorzn m38 : 19|1@1+ (1,0) [0|1] ""  gtw
 SG_ DAS_sw138_lRepeatCamI2CbusFault m138 : 19|1@1+ (1,0) [0|1] ""  gtw
 SG_ DAS_sw134_narrowCamI2CbusFault m134 : 19|1@1+ (1,0) [0|1] ""  gtw
 SG_ DAS_sw027_CPU_Checkstop_Error m27 : 19|1@1+ (1,0) [0|1] ""  gtw
 SG_ DAS_sw052_overTemperature m52 : 19|1@1+ (1,0) [0|1] ""  gtw
 SG_ DAS_sw070_lastTireFitment m70 : 19|3@1+ (1,0) [0|7] ""  gtw
 SG_ DAS_sw048_stackOverflow m48 : 19|1@1+ (1,0) [0|1] ""  gtw
 SG_ DAS_sw202_s7Blocked m202 : 18|1@1+ (1,0) [0|1] ""  gtw
 SG_ DAS_sw230_sensor3Blocked m230 : 18|1@1+ (1,0) [0|1] ""  gtw
 SG_ DAS_sw017_Camera_Msg_Tsr_MIA m17 : 18|1@1+ (1,0) [0|1] ""  gtw
 SG_ DAS_sw195_s7Blocked m195 : 18|1@1+ (1,0) [0|1] ""  gtw
 SG_ DAS_sw051_a03vBatHigh m51 : 18|1@1+ (1,0) [0|1] ""  gtw
 SG_ DAS_sw069_parkMia m69 : 18|1@1+ (1,0) [0|1] ""  gtw
 SG_ DAS_sw053_a12espMIA m53 : 18|1@1+ (1,0) [0|1] ""  gtw
 SG_ DAS_sw015_RadarMisalignment m15 : 18|2@1+ (1,0) [0|3] ""  gtw
 SG_ DAS_sw080_road_class_check m80 : 18|1@1+ (1,0) [0|1] ""  gtw
 SG_ DAS_sw009_DI_MIA m9 : 18|1@1+ (1,0) [0|1] ""  gtw
 SG_ DAS_sw006_radCalibration m6 : 18|1@1+ (1,0) [0|1] ""  gtw
 SG_ DAS_sw057_locStatusMia m57 : 18|1@1+ (1,0) [0|1] ""  gtw
 SG_ DAS_sw005_RadarMisalignment m5 : 18|1@1+ (1,0) [0|1] ""  gtw
 SG_ DAS_sw038_AutofixOutOfCalib m38 : 18|1@1+ (1,0) [0|1] ""  gtw
 SG_ DAS_sw048_powerIssue m48 : 18|1@1+ (1,0) [0|1] ""  gtw
 SG_ DAS_sw052_HWFail m52 : 18|1@1+ (1,0) [0|1] ""  gtw
 SG_ DAS_sw010_a06calibNotOK m10 : 18|1@1+ (1,0) [0|1] ""  gtw
 SG_ DAS_sw073_escalateLDWreason m73 : 18|2@1+ (1,0) [0|3] ""  gtw
 SG_ DAS_sw227_vehicleSpeed m227 : 18|12@1+ (0.05,-25) [-25|179.75] "mph"  gtw
 SG_ DAS_sw004_radSensorBlind m4 : 18|1@1+ (1,0) [0|1] ""  gtw
 SG_ DAS_sw028_inv_multifrm_1st m28 : 18|1@1+ (1,0) [0|1] ""  gtw
 SG_ DAS_sw026_tardiness m26 : 18|9@1+ (0.25,0) [0|127.75] "ms"  gtw
 SG_ DAS_sw193_impairedVD m193 : 18|1@1+ (1,0) [0|1] ""  gtw
 SG_ DAS_sw027_Unused_Bit_0 m27 : 18|1@1+ (1,0) [0|1] ""  gtw
 SG_ DAS_sw198_tflMsgInvalid m198 : 18|1@1+ (1,0) [0|1] ""  gtw
 SG_ DAS_sw029_unusedBits m29 : 17|15@1+ (1,0) [0|32767] ""  gtw
 SG_ DAS_sw219_roadClass m219 : 17|3@1+ (1,0) [0|7] ""  gtw
 SG_ DAS_sw069_espMia m69 : 17|1@1+ (1,0) [0|1] ""  gtw
 SG_ DAS_sw227_sensorNumber m227 : 17|1@1+ (1,0) [0|1] ""  gtw
 SG_ DAS_sw193_fullBlockage m193 : 17|1@1+ (1,0) [0|1] ""  gtw
 SG_ DAS_sw010_a05calibReqd m10 : 17|1@1+ (1,0) [0|1] ""  gtw
 SG_ DAS_sw051_a02flashPerformance m51 : 17|1@1+ (1,0) [0|1] ""  gtw
 SG_ DAS_sw005_AutofixOutOfCalibYaw m5 : 17|1@1+ (1,0) [0|1] ""  gtw
 SG_ DAS_sw230_sensor2Blocked m230 : 17|1@1+ (1,0) [0|1] ""  gtw
 SG_ DAS_sw057_dasMapDataMia m57 : 17|1@1+ (1,0) [0|1] ""  gtw
 SG_ DAS_sw202_s6Blocked m202 : 17|1@1+ (1,0) [0|1] ""  gtw
 SG_ DAS_sw053_a11bdyMIA m53 : 17|1@1+ (1,0) [0|1] ""  gtw
 SG_ DAS_sw220_roadClass m220 : 17|3@1+ (1,0) [0|7] ""  gtw
 SG_ DAS_sw052_sensorDirty m52 : 17|1@1+ (1,0) [0|1] ""  gtw
 SG_ DAS_sw027_Core_Reset m27 : 17|1@1+ (1,0) [0|1] ""  gtw
 SG_ DAS_sw004_radHWFailure m4 : 17|1@1+ (1,0) [0|1] ""  gtw
 SG_ DAS_sw080_dist_travelled_check m80 : 17|1@1+ (1,0) [0|1] ""  gtw
 SG_ DAS_sw006_RadarMisaligned m6 : 17|1@1+ (1,0) [0|1] ""  gtw
 SG_ DAS_sw198_partialBlockage m198 : 17|1@1+ (1,0) [0|1] ""  gtw
 SG_ DAS_sw017_Camera_Msg_Objects_MIA m17 : 17|1@1+ (1,0) [0|1] ""  gtw
 SG_ DAS_sw038_OutOfFocusImage m38 : 17|1@1+ (1,0) [0|1] ""  gtw
 SG_ DAS_sw195_s6Blocked m195 : 17|1@1+ (1,0) [0|1] ""  gtw
 SG_ DAS_sw009_DI_aeb_unresponsive m9 : 17|1@1+ (1,0) [0|1] ""  gtw
 SG_ DAS_sw048_thermalIssue m48 : 17|1@1+ (1,0) [0|1] ""  gtw
 SG_ DAS_sw073_silentEscalatedLDW m73 : 17|1@1+ (1,0) [0|1] ""  gtw
 SG_ DAS_sw064_status m64 : 17|1@1+ (1,0) [0|1] ""  gtw
 SG_ DAS_sw028_rx_inv_len m28 : 17|1@1+ (1,0) [0|1] ""  gtw
 SG_ DAS_sw068_percentConsistency m68 : 16|10@1+ (0.1,0) [0|100] "%"  gtw
 SG_ DAS_sw030_heaterState m30 : 16|8@1+ (1,0) [0|2] ""  gtw
 SG_ DAS_sw103_objectDx m103 : 16|8@1+ (0.5,0) [0|127.5] "m"  gtw
 SG_ DAS_sw219_controlledAccess m219 : 16|1@1+ (1,0) [0|1] ""  gtw
 SG_ DAS_sw018_minThreshold m18 : 16|13@1+ (1,0) [0|4500] "mV"  gtw
 SG_ DAS_sw207_appMobileyeStatus m207 : 16|8@1+ (1,0) [0|255] ""  gtw
 SG_ DAS_sw040_accel_pedal_pos m40 : 16|8@1+ (0.5,0) [0|127.5] "%"  gtw
 SG_ DAS_sw024_Task_ID m24 : 16|4@1+ (1,0) [0|15] ""  gtw
 SG_ DAS_sw059_parkMia m59 : 16|8@1+ (1,0) [0|11] ""  gtw
 SG_ DAS_sw106_torsionBarOffset m106 : 16|8@1+ (0.005,-0.64) [-0.64|0.63] "Nm"  gtw
 SG_ DAS_sw051_a01ecuInternalPerf m51 : 16|1@1+ (1,0) [0|1] ""  gtw
 SG_ DAS_sw013_stateBeforeWatchdog m13 : 16|5@1+ (1,0) [0|31] ""  gtw
 SG_ DAS_sw033_gtwMia m33 : 16|8@1+ (1,0) [0|8] ""  gtw
 SG_ DAS_sw194_leadAx m194 : 16|6@1- (0.2,0.0) [-6|6] "m/s^2"  gtw
 SG_ DAS_sw039_sdm_rcm_Mia m39 : 16|8@1+ (1,0) [0|255] ""  gtw
 SG_ DAS_sw012_bootTestResults m12 : 16|16@1+ (1,0) [0|65535] ""  gtw
 SG_ DAS_sw132_narrowCamExtPitchCal m132 : 16|9@1- (0.05,0.0) [-12.5|12.5] "deg"  gtw
 SG_ DAS_sw138_lRepeatCamDeserFault m138 : 16|3@1+ (1,0) [0|7] ""  gtw
 SG_ DAS_sw179_rPillarCamExtPitchCal m179 : 16|9@1- (0.05,0.0) [-12.5|12.5] "deg"  gtw
 SG_ DAS_sw063_expectedMajorVer m63 : 16|8@1+ (1,0) [0|255] ""  gtw
 SG_ DAS_sw134_narrowCamDeserFault m134 : 16|3@1+ (1,0) [0|7] ""  gtw
 SG_ DAS_sw053_a10canBusOff m53 : 16|1@1+ (1,0) [0|1] ""  gtw
 SG_ DAS_sw086_distanceException m86 : 16|8@1+ (1,90) [90|165] "m"  gtw
 SG_ DAS_sw065_app_mobileye_status m65 : 16|8@1+ (1,0) [0|255] ""  gtw
 SG_ DAS_sw136_lPillarCamDeserFault m136 : 16|3@1+ (1,0) [0|7] ""  gtw
 SG_ DAS_sw004_radIssue m4 : 16|1@1+ (1,0) [0|1] ""  gtw
 SG_ DAS_sw173_rPillarCamExtNoCalFile m173 : 16|1@1+ (1,0) [0|1] ""  gtw
 SG_ DAS_sw015_RadarLowVisibility m15 : 16|2@1+ (1,0) [0|3] ""  gtw
 SG_ DAS_sw062_HorizontalMisalignment m62 : 16|16@1+ (0.00137332,-45) [-45|45.0005262] "deg"  gtw
 SG_ DAS_sw227_sensorSide m227 : 16|1@1+ (1,0) [0|1] ""  gtw
 SG_ DAS_sw135_fisheyeCamDeserFault m135 : 16|3@1+ (1,0) [0|7] ""  gtw
 SG_ DAS_sw074_ipsoDx m74 : 16|6@1+ (2,0) [0|126] "m"  gtw
 SG_ DAS_sw071_selfParkType m71 : 16|4@1+ (1,0) [0|15] ""  gtw
 SG_ DAS_sw076_targetDist m76 : 16|9@1+ (0.2,0) [0|102.2] "m"  gtw
 SG_ DAS_sw141_maxThreshold m141 : 16|8@1- (1,0) [-128|127] "degC"  gtw
 SG_ DAS_sw205_oocDistance m205 : 16|8@1+ (1,0) [0|255] "cm"  gtw
 SG_ DAS_sw195_s1Blocked m195 : 16|1@1+ (1,0) [0|1] ""  gtw
 SG_ DAS_sw078_camCipv_dx m78 : 16|8@1+ (0.2,0) [0|51] "m"  gtw
 SG_ DAS_sw201_virtualLaneInputOAL m201 : 16|3@1+ (1,0) [0|7] ""  gtw
 SG_ DAS_sw006_RadarLowVisibility m6 : 16|1@1+ (1,0) [0|1] ""  gtw
 SG_ DAS_sw019_taskId m19 : 16|8@1+ (1,0) [0|255] ""  gtw
 SG_ DAS_sw073_escalateLDWs m73 : 16|1@1+ (1,0) [0|1] ""  gtw
 SG_ DAS_sw009_DIaebState_fault m9 : 16|1@1+ (1,0) [0|1] ""  gtw
 SG_ DAS_sw060_targetDist m60 : 16|9@1+ (0.2,0) [0|102.2] "m"  gtw
 SG_ DAS_sw218_cipvDist m218 : 16|8@1+ (0.2,0) [0|51] "m"  gtw
 SG_ DAS_sw025_state_before_override m25 : 16|4@1+ (1,0) [0|15] ""  gtw
 SG_ DAS_sw137_rPillarCamDeserFault m137 : 16|3@1+ (1,0) [0|7] ""  gtw
 SG_ DAS_sw171_fisheyeCamExtNoCalFile m171 : 16|1@1+ (1,0) [0|1] ""  gtw
 SG_ DAS_sw069_epasMia m69 : 16|1@1+ (1,0) [0|1] ""  gtw
 SG_ DAS_sw035_espMia m35 : 16|8@1+ (1,0) [0|9] ""  gtw
 SG_ DAS_sw022_operation m22 : 16|4@1+ (1,0) [0|4] ""  gtw
 SG_ DAS_sw172_lPillarCamExtNoCalFile m172 : 16|1@1+ (1,0) [0|1] ""  gtw
 SG_ DAS_sw044_countLSB m44 : 16|8@1+ (1,0) [0|255] ""  gtw
 SG_ DAS_sw230_sensor1Blocked m230 : 16|1@1+ (1,0) [0|1] ""  gtw
 SG_ DAS_sw129_mainCamExtNoCalFile m129 : 16|1@1+ (1,0) [0|1] ""  gtw
 SG_ DAS_sw220_controlledAccess m220 : 16|1@1+ (1,0) [0|1] ""  gtw
 SG_ DAS_sw080_sensors_healty_check m80 : 16|1@1+ (1,0) [0|1] ""  gtw
 SG_ DAS_sw081_radarDistance m81 : 16|8@1+ (0.0625,0) [0|15.9375] "m"  gtw
 SG_ DAS_sw014_fileNameHash m14 : 16|16@1+ (1,0) [0|65535] ""  gtw
 SG_ DAS_sw052_a07sensorBlinded m52 : 16|1@1+ (1,0) [0|1] ""  gtw
 SG_ DAS_sw056_diMia m56 : 16|8@1+ (1,0) [0|255] ""  gtw
 SG_ DAS_sw083_Targ5_RCS m83 : 16|16@1+ (0.0039063096,0) [0|256] "dB"  gtw
 SG_ DAS_sw181_rRepeatCamExtPitchCal m181 : 16|9@1- (0.05,0.0) [-12.5|12.5] "deg"  gtw
 SG_ DAS_sw082_L_VL m82 : 16|8@1+ (0.05,-6.4) [-6.4|6.35] "m"  gtw
 SG_ DAS_sw045_radMia m45 : 16|5@1+ (1,0) [0|21] ""  gtw
 SG_ DAS_sw028_rx_buffer_full m28 : 16|1@1+ (1,0) [0|1] ""  gtw
 SG_ DAS_sw026_task_id m26 : 16|2@1+ (1,0) [0|3] ""  gtw
 SG_ DAS_sw034_sccmMia m34 : 16|8@1+ (1,0) [0|255] ""  gtw
 SG_ DAS_sw047_edrStatus m47 : 16|4@1+ (1,0) [0|15] ""  gtw
 SG_ DAS_sw016_targetDist m16 : 16|9@1+ (0.2,0) [0|102.2] "m"  gtw
 SG_ DAS_sw180_lRepeatCamExtPitchCal m180 : 16|9@1- (0.05,0.0) [-12.5|12.5] "deg"  gtw
 SG_ DAS_sw010_a04calibNotDone m10 : 16|1@1+ (1,0) [0|1] ""  gtw
 SG_ DAS_sw054_Autofix_cnvrgnceStatus m54 : 16|8@1+ (1,0) [0|255] ""  gtw
 SG_ DAS_sw029_tx_buffer_full m29 : 16|1@1+ (1,0) [0|1] ""  gtw
 SG_ DAS_sw021_tempSensorId m21 : 16|8@1+ (1,0) [0|255] ""  gtw
 SG_ DAS_sw231_timeToImpact m231 : 16|9@1+ (1,0) [0|511] "ms"  gtw
 SG_ DAS_sw140_backupCamCSIBridgeFlt m140 : 16|3@1+ (1,0) [0|7] ""  gtw
 SG_ DAS_sw020_unusedW0 m20 : 16|16@1+ (1,0) [0|65535] ""  gtw
 SG_ DAS_sw198_fullBlockage m198 : 16|1@1+ (1,0) [0|1] ""  gtw
 SG_ DAS_sw032_canBus m32 : 16|4@1+ (1,0) [0|7] ""  gtw
 SG_ DAS_sw017_Camera_Msg_Lanes_MIA m17 : 16|1@1+ (1,0) [0|1] ""  gtw
 SG_ DAS_sw066_app_mobileye_status m66 : 16|8@1+ (1,0) [0|255] ""  gtw
 SG_ DAS_sw175_rRepeatCamExtNoCalFile m175 : 16|1@1+ (1,0) [0|1] ""  gtw
 SG_ DAS_sw139_rhtRptrCamDeserFault m139 : 16|3@1+ (1,0) [0|7] ""  gtw
 SG_ DAS_sw142_camExtPitchCal m142 : 16|9@1+ (0.05,-12.5) [-12.5|12.5] "deg"  gtw
 SG_ DAS_sw144_selfieCamDeserFault m144 : 16|3@1+ (1,0) [0|7] ""  gtw
 SG_ DAS_sw204_frLeft m204 : 16|8@1+ (1,0) [0|255] "cm"  gtw
 SG_ DAS_sw130_narrowCamExtNoCalFile m130 : 16|1@1+ (1,0) [0|1] ""  gtw
 SG_ DAS_sw048_swAssert m48 : 16|1@1+ (1,0) [0|1] ""  gtw
 SG_ DAS_sw042_health_state m42 : 16|3@1+ (1,0) [0|7] ""  gtw
 SG_ DAS_sw084_ipsoTTC m84 : 16|8@1+ (0.02,0) [0|5.11] "seconds"  gtw
 SG_ DAS_sw085_radarDistance m85 : 16|8@1+ (0.0625,0) [0|15.9375] "m"  gtw
 SG_ DAS_sw070_currTireFitment m70 : 16|3@1+ (1,0) [0|7] ""  gtw
 SG_ DAS_sw031_canBus m31 : 16|4@1+ (1,0) [0|7] ""  gtw
 SG_ DAS_sw202_s1Blocked m202 : 16|1@1+ (1,0) [0|1] ""  gtw
 SG_ DAS_sw046_recordId m46 : 16|16@1+ (1,0) [0|65535] ""  gtw
 SG_ DAS_sw177_fisheyeCamExtPitchCal m177 : 16|9@1- (0.05,0.0) [-12.5|12.5] "deg"  gtw
 SG_ DAS_sw133_mainCamDeserFault m133 : 16|3@1+ (1,0) [0|7] ""  gtw
 SG_ DAS_sw027_JTAG_Reset m27 : 16|1@1+ (1,0) [0|1] ""  gtw
 SG_ DAS_sw200_autopilotIntState m200 : 16|4@1+ (1,0) [0|15] ""  gtw
 SG_ DAS_sw058_epbMia m58 : 16|8@1+ (1,0) [0|255] ""  gtw
 SG_ DAS_sw064_sysStatus m64 : 16|1@1+ (1,0) [0|1] ""  gtw
 SG_ DAS_sw036_bdyMia m36 : 16|8@1+ (1,0) [0|255] ""  gtw
 SG_ DAS_sw041_rate m41 : 16|10@1- (1,0) [-512|511] "deg/s"  gtw
 SG_ DAS_sw038_RadarMisalignment m38 : 16|1@1+ (1,0) [0|1] ""  gtw
 SG_ DAS_sw067_sccmSTW m67 : 16|14@1+ (0.1,-819.2) [-819.2|819] "deg"  gtw
 SG_ DAS_sw005_AutofixOutOfCalib m5 : 16|1@1+ (1,0) [0|1] ""  gtw
 SG_ DAS_sw075_scMia m75 : 16|8@1+ (1,0) [0|255] ""  gtw
 SG_ DAS_sw049_boot_version_msw m49 : 16|16@1+ (1,0) [0|65535] ""  gtw
 SG_ DAS_sw055_detectedRadcVersion m55 : 16|32@1+ (1,0) [0|4294967295] ""  gtw
 SG_ DAS_sw043_mobileye_status m43 : 16|16@1+ (1,0) [0|65535] ""  gtw
 SG_ DAS_sw199_abortCodeDAS m199 : 16|5@1+ (1,0) [0|24] ""  gtw
 SG_ DAS_sw077_oocDistance m77 : 16|9@1+ (1,0) [0|512] "cm"  gtw
 SG_ DAS_sw037_camera m37 : 16|8@1+ (1,0) [0|255] ""  gtw
 SG_ DAS_sw061_airSuspensionMia m61 : 16|8@1+ (1,0) [0|255] ""  gtw
 SG_ DAS_sw072_vehicleX m72 : 16|10@1+ (0.05,-25.6) [-25.6|25.5] "m"  gtw
 SG_ DAS_sw213_autopilotIntState m213 : 16|4@1+ (1,0) [0|15] ""  gtw
 SG_ DAS_sw057_chCtrlMia m57 : 16|1@1+ (1,0) [0|1] ""  gtw
 SG_ DAS_sw174_lRepeatCamExtNoCalFile m174 : 16|1@1+ (1,0) [0|1] ""  gtw
 SG_ DAS_sw193_blurredImage m193 : 16|1@1+ (1,0) [0|1] ""  gtw
 SG_ DAS_sw178_lPillarCamExtPitchCal m178 : 16|9@1- (0.05,0.0) [-12.5|12.5] "deg"  gtw
 SG_ DAS_sw131_mainCamExtPitchCal m131 : 16|9@1- (0.05,0.0) [-12.5|12.5] "deg"  gtw
 SG_ DAS_sw011_scaState m11 : 16|3@1+ (1,0) [0|7] ""  gtw
 SG_ DAS_sw050_targetDist m50 : 16|9@1+ (0.2,0) [0|102.2] "m"  gtw
 SG_ DAS_sw203_controlType m203 : 16|4@1+ (1,0) [0|15] ""  gtw
 SG_ DAS_alertState : 15|1@1+ (1,0) [0|1] ""  gtw
 SG_ DAS_alertID M : 0|15@1+ (1,0) [0|231] ""  gtw

BO_ 2043 dynamicMessage2_0: 1 CH
 SG_ APB_alertID : 1|1@1+ (1,0) [0|0] ""  gtw
 SG_ APB_alertState : 0|1@1+ (1,0) [0|1] ""  gtw

BO_ 909 TAS_warningMatrix3: 8 CH
 SG_ TAS_w164_calibrationVersion : 35|1@1+ (1,0) [0|1] ""  gtw
 SG_ TAS_w163_reservoirFillDisabled : 34|1@1+ (1,0) [0|1] ""  gtw
 SG_ TAS_w162_compressorValveOpenGND : 33|1@1+ (1,0) [0|1] ""  gtw
 SG_ TAS_w161_valveBlockOpenGND : 32|1@1+ (1,0) [0|1] ""  gtw
 SG_ TAS_w160_otherCircuitCompressor : 31|1@1+ (1,0) [0|1] ""  gtw
 SG_ TAS_w159_otherCircuitBoost : 30|1@1+ (1,0) [0|1] ""  gtw
 SG_ TAS_w158_otherCircuitExhaust : 29|1@1+ (1,0) [0|1] ""  gtw
 SG_ TAS_w157_otherCircuitReservoir : 28|1@1+ (1,0) [0|1] ""  gtw
 SG_ TAS_w156_otherCircuitRR : 27|1@1+ (1,0) [0|1] ""  gtw
 SG_ TAS_w155_otherCircuitRL : 26|1@1+ (1,0) [0|1] ""  gtw
 SG_ TAS_w154_otherCircuitFR : 25|1@1+ (1,0) [0|1] ""  gtw
 SG_ TAS_w153_otherCircuitFL : 24|1@1+ (1,0) [0|1] ""  gtw
 SG_ TAS_w152_boardFaultCompressor : 23|1@1+ (1,0) [0|1] ""  gtw
 SG_ TAS_w151_boardFaultBoost : 22|1@1+ (1,0) [0|1] ""  gtw
 SG_ TAS_w150_boardFaultExhaust : 21|1@1+ (1,0) [0|1] ""  gtw
 SG_ TAS_w149_boardFaultReservoir : 20|1@1+ (1,0) [0|1] ""  gtw
 SG_ TAS_w148_boardFaultRR : 19|1@1+ (1,0) [0|1] ""  gtw
 SG_ TAS_w147_boardFaultRL : 18|1@1+ (1,0) [0|1] ""  gtw
 SG_ TAS_w146_boardFaultFR : 17|1@1+ (1,0) [0|1] ""  gtw
 SG_ TAS_w145_boardFaultFL : 16|1@1+ (1,0) [0|1] ""  gtw
 SG_ TAS_w144_shortCircuitCompressor : 15|1@1+ (1,0) [0|1] ""  gtw
 SG_ TAS_w143_shortCircuitBoost : 14|1@1+ (1,0) [0|1] ""  gtw
 SG_ TAS_w142_shortCircuitExhaust : 13|1@1+ (1,0) [0|1] ""  gtw
 SG_ TAS_w141_shortCircuitReservoir : 12|1@1+ (1,0) [0|1] ""  gtw
 SG_ TAS_w140_shortCircuitRR : 11|1@1+ (1,0) [0|1] ""  gtw
 SG_ TAS_w139_shortCircuitRL : 10|1@1+ (1,0) [0|1] ""  gtw
 SG_ TAS_w138_shortCircuitFR : 9|1@1+ (1,0) [0|1] ""  gtw
 SG_ TAS_w137_shortCircuitFL : 8|1@1+ (1,0) [0|1] ""  gtw
 SG_ TAS_w136_openCircuitCompressor : 7|1@1+ (1,0) [0|1] ""  gtw
 SG_ TAS_w135_openCircuitBoost : 6|1@1+ (1,0) [0|1] ""  gtw
 SG_ TAS_w134_openCircuitExhaust : 5|1@1+ (1,0) [0|1] ""  gtw
 SG_ TAS_w133_openCircuitReservoir : 4|1@1+ (1,0) [0|1] ""  gtw
 SG_ TAS_w132_openCircuitRR : 3|1@1+ (1,0) [0|1] ""  gtw
 SG_ TAS_w131_openCircuitRL : 2|1@1+ (1,0) [0|1] ""  gtw
 SG_ TAS_w130_openCircuitFR : 1|1@1+ (1,0) [0|1] ""  gtw
 SG_ TAS_w129_openCircuitFL : 0|1@1+ (1,0) [0|1] ""  gtw

BO_ 1097 APP_warningMatrix4: 8 CH
 SG_ APP_w282_selfieCameraStreamErr : 25|1@1+ (1,0) [0|1] ""  gtw
 SG_ APP_w281_backupCameraStreamErr : 24|1@1+ (1,0) [0|1] ""  gtw
 SG_ APP_w280_rRepeatCameraStreamErr : 23|1@1+ (1,0) [0|1] ""  gtw
 SG_ APP_w279_lRepeatCameraStreamErr : 22|1@1+ (1,0) [0|1] ""  gtw
 SG_ APP_w278_rPillarCameraStreamErr : 21|1@1+ (1,0) [0|1] ""  gtw
 SG_ APP_w277_lPillarCameraStreamErr : 20|1@1+ (1,0) [0|1] ""  gtw
 SG_ APP_w276_fisheyeCameraStreamErr : 19|1@1+ (1,0) [0|1] ""  gtw
 SG_ APP_w275_narrowCameraStreamErr : 18|1@1+ (1,0) [0|1] ""  gtw
 SG_ APP_w274_mainCameraStreamErr : 17|1@1+ (1,0) [0|1] ""  gtw
 SG_ APP_w273_lssEvent : 16|1@1+ (1,0) [0|1] ""  gtw
 SG_ APP_w272_laneChangeUnavailable : 15|1@1+ (1,0) [0|1] ""  gtw
 SG_ APP_w271_laneChangeAborted : 14|1@1+ (1,0) [0|1] ""  gtw
 SG_ APP_w270_blindspotRestricted : 13|1@1+ (1,0) [0|1] ""  gtw
 SG_ APP_w269_autopilotLimited : 12|1@1+ (1,0) [0|1] ""  gtw
 SG_ APP_w268_backupCamExtNotCal : 11|1@1+ (1,0) [0|1] ""  gtw
 SG_ APP_w267_benchtopEcu : 10|1@1+ (1,0) [0|1] ""  gtw
 SG_ APP_w266_visionScheduleFallback : 9|1@1+ (1,0) [0|1] ""  gtw
 SG_ APP_w265_drvOnNavUnavailable : 8|1@1+ (1,0) [0|1] ""  gtw
 SG_ APP_w264_lssFault : 7|1@1+ (1,0) [0|1] ""  gtw
 SG_ APP_w263_lssAbort : 6|1@1+ (1,0) [0|1] ""  gtw
 SG_ APP_w262_apeCalibMode : 5|1@1+ (1,0) [0|1] ""  gtw
 SG_ APP_w261_pcieHardwareErrors : 4|1@1+ (1,0) [0|1] ""  gtw
 SG_ APP_w260_collisionWarningEvent : 3|1@1+ (1,0) [0|1] ""  gtw
 SG_ APP_w259_aebOverrideEvent : 2|1@1+ (1,0) [0|1] ""  gtw
 SG_ APP_w258_aebEvent : 1|1@1+ (1,0) [0|1] ""  gtw
 SG_ APP_w257_brakeJerkEvent : 0|1@1+ (1,0) [0|1] ""  gtw

BO_ 1040 APP_cameraStatus: 1 CH
 SG_ APP_backupCameraFrameRate : 1|6@1+ (1,0) [0|63] ""  gtw
 SG_ APP_backupCameraFeedGood : 0|1@1+ (1,0) [0|1] ""  gtw

BO_ 1361 EPAS3S_bootID: 8 CH
 SG_ EPAS3S_bootIdData : 0|64@1+ (1,0) [0|18446744073709551615] ""  gtw

BO_ 297 SCCM_steeringAngleSensor: 8 CH
 SG_ SCCM_steeringAngleSensorReservd3 : 56|8@1+ (1,0) [0|255] ""  X
 SG_ SCCM_steeringAngleSensorReservd2 : 48|8@1+ (1,0) [0|255] ""  X
 SG_ SCCM_steeringAngleSensorReservd1 : 46|2@1+ (1,0) [0|3] ""  X
 SG_ SCCM_steeringAngleSpeed : 32|14@1+ (0.5,-4096) [-4096|4095.5] "deg/s"  park
 SG_ SCCM_steeringAngleValidity : 30|2@1+ (1,0) [0|3] ""  park
 SG_ SCCM_steeringAngle : 16|14@1+ (0.1,-819.2) [-819.2|819] "deg"  epas3s
 SG_ SCCM_steeringAngleSensorStatus : 14|2@1+ (1,0) [0|3] ""  epas3s
 SG_ SCCM_supplierID : 12|2@1+ (1,0) [0|3] ""  park
 SG_ SCCM_steeringAngleCounter : 8|4@1+ (1,0) [0|15] ""  epas3s
 SG_ SCCM_steeringAngleCrc : 0|8@1+ (1,0) [0|255] ""  epas3s

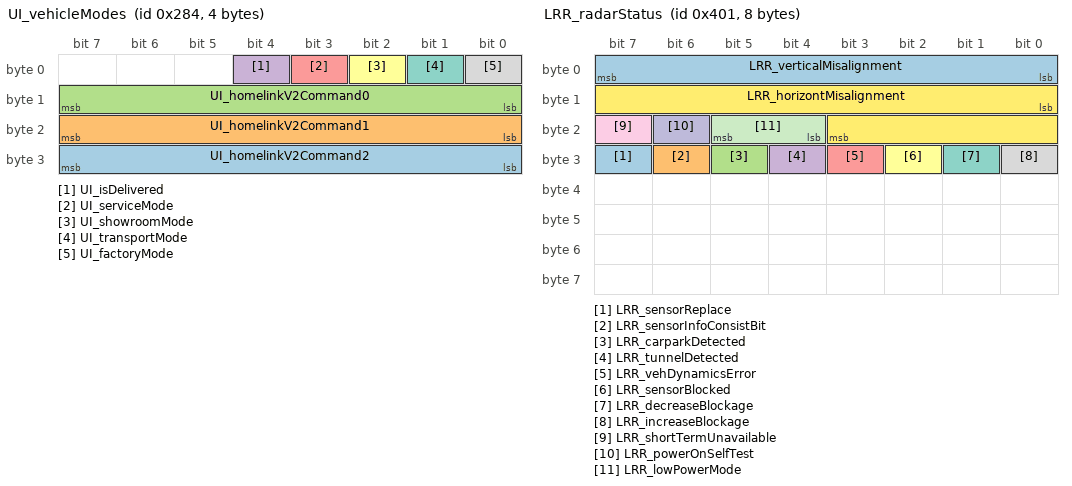
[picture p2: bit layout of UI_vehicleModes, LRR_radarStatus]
BO_ 644 UI_vehicleModes: 4 CH
 SG_ UI_homelinkV2Command2 : 24|8@1+ (1,0) [0|255] ""  X
 SG_ UI_homelinkV2Command1 : 16|8@1+ (1,0) [0|255] ""  X
 SG_ UI_homelinkV2Command0 : 8|8@1+ (1,0) [0|255] ""  X
 SG_ UI_isDelivered : 4|1@1+ (1,0) [0|1] ""  X
 SG_ UI_serviceMode : 3|1@1+ (1,0) [0|1] ""  X
 SG_ UI_showroomMode : 2|1@1+ (1,0) [0|1] ""  X
 SG_ UI_transportMode : 1|1@1+ (1,0) [0|1] ""  app
 SG_ UI_factoryMode : 0|1@1+ (1,0) [0|1] ""  app

BO_ 1064 UI_telemetryControl: 8 CH
 SG_ UI_TCR_maxRoadClass : 61|3@1+ (1,0) [0|7] ""  X
 SG_ UI_TCR_maxObjects : 56|5@1+ (1,0) [0|31] ""  X
 SG_ UI_TCR_maxDy : 48|5@1+ (0.5,0) [0|15.5] "m"  X
 SG_ UI_TCR_minRCS : 40|8@1+ (0.25,-14) [-14|49.75] "dB"  X
 SG_ UI_TCR_vehSpeed : 32|8@1+ (1,0) [0|255] ""  X
 SG_ UI_TCR_wExist : 24|5@1+ (1,0) [0|31] ""  X
 SG_ UI_TCR_downSampleFactor : 10|4@1+ (1,0) [0|15] ""  X
 SG_ UI_TCR_classUnknown : 9|1@1+ (1,0) [0|1] ""  das
 SG_ UI_TCR_classMovingFourWheel : 8|1@1+ (1,0) [0|1] ""  das
 SG_ UI_TCR_classMovingTwoWheel : 7|1@1+ (1,0) [0|1] ""  das
 SG_ UI_TCR_classMovingPed : 6|1@1+ (1,0) [0|1] ""  das
 SG_ UI_TCR_classConstElem : 5|1@1+ (1,0) [0|1] ""  das
 SG_ UI_TCR_moveStateIndeterm : 4|1@1+ (1,0) [0|1] ""  das
 SG_ UI_TCR_moveStateMoving : 3|1@1+ (1,0) [0|1] ""  das
 SG_ UI_TCR_moveStateStopped : 2|1@1+ (1,0) [0|1] ""  das
 SG_ UI_TCR_moveStateStanding : 1|1@1+ (1,0) [0|1] ""  das
 SG_ UI_TCR_enable : 0|1@1+ (1,0) [0|1] ""  das

BO_ 1025 LRR_radarStatus: 8 CH
 SG_ LRR_sensorReplace : 31|1@1+ (1,0) [0|1] ""  X
 SG_ LRR_sensorInfoConsistBit : 30|1@1+ (1,0) [0|1] ""  X
 SG_ LRR_carparkDetected : 29|1@1+ (1,0) [0|1] ""  X
 SG_ LRR_tunnelDetected : 28|1@1+ (1,0) [0|1] ""  X
 SG_ LRR_vehDynamicsError : 27|1@1+ (1,0) [0|1] ""  X
 SG_ LRR_sensorBlocked : 26|1@1+ (1,0) [0|1] ""  X
 SG_ LRR_decreaseBlockage : 25|1@1+ (1,0) [0|1] ""  X
 SG_ LRR_increaseBlockage : 24|1@1+ (1,0) [0|1] ""  X
 SG_ LRR_shortTermUnavailable : 23|1@1+ (1,0) [0|1] ""  X
 SG_ LRR_powerOnSelfTest : 22|1@1+ (1,0) [0|1] ""  X
 SG_ LRR_lowPowerMode : 20|2@1+ (1,0) [0|3] ""  X
 SG_ LRR_horizontMisalignment : 8|12@1+ (0.0001220703125,-0.25) [-0.25|0.24988] "rad"  gtw
 SG_ LRR_verticalMisalignment : 0|8@1+ (0.001953125,-0.25) [-0.25|0.24805] "rad"  gtw

BO_ 1082 DAS_warningMatrix3: 8 CH
 SG_ DAS_w231_idfEvent : 38|1@1+ (1,0) [0|1] ""  gtw
 SG_ DAS_w230_alcUltrasoundBlocked : 37|1@1+ (1,0) [0|1] ""  gtw
 SG_ DAS_w229_alcUltrasoundDamaged : 36|1@1+ (1,0) [0|1] ""  gtw
 SG_ DAS_w228_DEPRECATED : 35|1@1+ (1,0) [0|1] ""  gtw
 SG_ DAS_w227_virtualWallBlocked : 34|1@1+ (1,0) [0|1] ""  gtw
 SG_ DAS_w226_lcCamCalNeededSpeedLmt : 33|1@1+ (1,0) [0|1] ""  gtw
 SG_ DAS_w225_lcDegradedVisSpeedLmt : 32|1@1+ (1,0) [0|1] ""  gtw
 SG_ DAS_w224_accCameraCalibration : 31|1@1+ (1,0) [0|1] ""  gtw
 SG_ DAS_w223_accObjectInPath : 30|1@1+ (1,0) [0|1] ""  gtw
 SG_ DAS_w222_accCameraBlind : 29|1@1+ (1,0) [0|1] ""  gtw
 SG_ DAS_w221_accRadarBlind : 28|1@1+ (1,0) [0|1] ""  gtw
 SG_ DAS_w220_lcTempUnavailableRoad : 27|1@1+ (1,0) [0|1] ""  gtw
 SG_ DAS_w219_lcTempUnavailableSpeed : 26|1@1+ (1,0) [0|1] ""  gtw
 SG_ DAS_w218_lcSpeedExceededLimit : 25|1@1+ (1,0) [0|1] ""  gtw
 SG_ DAS_w217_lcUnavailableSpeeding : 24|1@1+ (1,0) [0|1] ""  gtw
 SG_ DAS_w216_driverOverriding : 23|1@1+ (1,0) [0|1] ""  gtw
 SG_ DAS_w215_contDriverNotIntracting : 22|1@1+ (1,0) [0|1] ""  gtw
 SG_ DAS_w214_driverNotIntracting : 21|1@1+ (1,0) [0|1] ""  gtw
 SG_ DAS_w213_autosteerStruckOut : 20|1@1+ (1,0) [0|1] ""  gtw
 SG_ DAS_w212_lcUnavailableStrikeOut : 19|1@1+ (1,0) [0|1] ""  gtw
 SG_ DAS_w211_accNoSeatBelt : 18|1@1+ (1,0) [0|1] ""  gtw
 SG_ DAS_w210_camObstrcted : 17|1@1+ (1,0) [0|1] ""  gtw
 SG_ DAS_w209_autoSummonRequest : 16|1@1+ (1,0) [0|1] ""  gtw
 SG_ DAS_w208_rackDetected : 15|1@1+ (1,0) [0|1] ""  gtw
 SG_ DAS_w207_autosteerUnavailable : 14|1@1+ (1,0) [0|1] ""  gtw
 SG_ DAS_w206_autosteerNotEnabled : 13|1@1+ (1,0) [0|1] ""  gtw
 SG_ DAS_w205_apcFinalRear : 12|1@1+ (1,0) [0|1] ""  gtw
 SG_ DAS_w204_apcFinalFront : 11|1@1+ (1,0) [0|1] ""  gtw
 SG_ DAS_w203_apcActivation : 10|1@1+ (1,0) [0|1] ""  gtw
 SG_ DAS_w202_scwNoisyEnvironment : 9|1@1+ (1,0) [0|1] ""  gtw
 SG_ DAS_w201_lcAborting : 8|1@1+ (1,0) [0|1] ""  gtw
 SG_ DAS_w200_lcSlowdown : 7|1@1+ (1,0) [0|1] ""  gtw
 SG_ DAS_w199_apcAbort : 6|1@1+ (1,0) [0|1] ""  gtw
 SG_ DAS_w198_tsrUnavailable : 5|1@1+ (1,0) [0|1] ""  gtw
 SG_ DAS_w197_redLightWarning : 4|1@1+ (1,0) [0|1] ""  gtw
 SG_ DAS_w196_stopSignWarning : 3|1@1+ (1,0) [0|1] ""  gtw
 SG_ DAS_w195_scwUnavailable : 2|1@1+ (1,0) [0|1] ""  gtw
 SG_ DAS_w194_accDriverResumeRqrd : 1|1@1+ (1,0) [0|1] ""  gtw
 SG_ DAS_w193_camWindshieldUnclean : 0|1@1+ (1,0) [0|1] ""  gtw

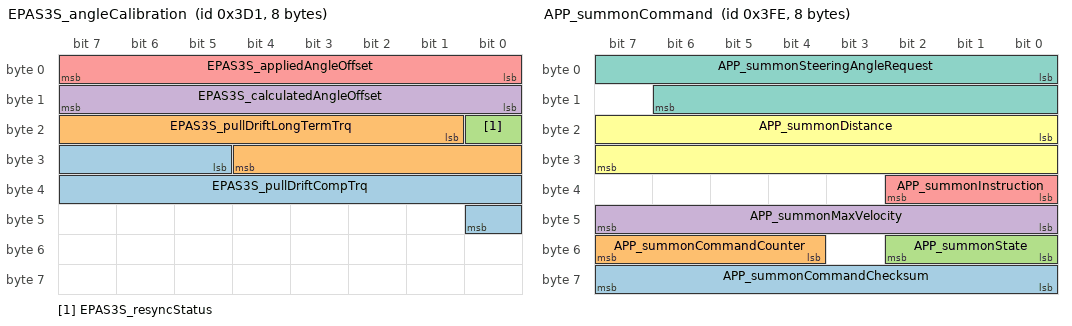
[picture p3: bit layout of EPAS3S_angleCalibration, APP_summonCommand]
BO_ 977 EPAS3S_angleCalibration: 8 CH
 SG_ EPAS3S_pullDriftCompTrq : 29|12@1+ (0.01,-10) [-10|10] "Nm"  gtw
 SG_ EPAS3S_pullDriftLongTermTrq : 17|12@1+ (0.01,-10) [-10|10] "Nm"  gtw
 SG_ EPAS3S_resyncStatus : 16|1@1+ (1,0) [0|1] ""  X
 SG_ EPAS3S_calculatedAngleOffset : 8|8@1+ (0.1,-12.8) [-12.8|12.7] "deg"  gtw
 SG_ EPAS3S_appliedAngleOffset : 0|8@1+ (0.1,-12.8) [-12.8|12.7] "deg"  gtw

BO_ 1835 XCP_tasRequest: 8 CH
 SG_ XCP_tasRequest : 7|64@0+ (1,0) [0|18446744073709551615] ""  tas

BO_ 1285 ESP_alertLog: 8 CH
 SG_ ESP_alertState : 15|1@1+ (1,0) [0|1] ""  gtw
 SG_ ESP_alertID : 0|9@1+ (1,0) [0|263] ""  gtw

BO_ 258 VCLEFT_doorStatus: 8 CH
 SG_ VCLEFT_frontHandlePulledPersist : 62|1@1+ (1,0) [0|1] ""  X
 SG_ VCLEFT_mirrorDipped : 61|1@1+ (1,0) [0|1] ""  X
 SG_ VCLEFT_mirrorHeatState : 58|3@1+ (1,0) [0|4] ""  X
 SG_ VCLEFT_mirrorRecallState : 55|3@1+ (1,0) [0|5] ""  X
 SG_ VCLEFT_mirrorFoldState : 52|3@1+ (1,0) [0|4] ""  X
 SG_ VCLEFT_mirrorState : 49|3@1+ (1,0) [0|4] ""  X
 SG_ VCLEFT_mirrorTiltYPosition : 41|8@1+ (0.02,0) [0|5] "V"  X
 SG_ VCLEFT_mirrorTiltXPosition : 33|8@1+ (0.02,0) [0|5] "V"  X
 SG_ VCLEFT_rearIntSwitchPressed : 32|1@1+ (1,0) [0|1] ""  X
 SG_ VCLEFT_frontIntSwitchPressed : 31|1@1+ (1,0) [0|1] ""  X
 SG_ VCLEFT_rearHandlePWM : 24|7@1+ (1,0) [0|100] "%"  X
 SG_ VCLEFT_frontHandlePWM : 16|7@1+ (1,0) [0|100] "%"  X
 SG_ VCLEFT_rearRelActuatorSwitch : 13|1@1+ (1,0) [0|1] ""  X
 SG_ VCLEFT_frontRelActuatorSwitch : 12|1@1+ (1,0) [0|1] ""  X
 SG_ VCLEFT_rearHandlePulled : 11|1@1+ (1,0) [0|1] ""  das
 SG_ VCLEFT_frontHandlePulled : 10|1@1+ (1,0) [0|1] ""  das
 SG_ VCLEFT_rearLatchSwitch : 9|1@1+ (1,0) [0|1] ""  X
 SG_ VCLEFT_frontLatchSwitch : 8|1@1+ (1,0) [0|1] ""  X
 SG_ VCLEFT_rearLatchStatus : 4|4@1+ (1,0) [0|8] ""  X
 SG_ VCLEFT_frontLatchStatus : 0|4@1+ (1,0) [0|8] ""  ocs1p

BO_ 1947 XCP_epblRequest: 8 CH
 SG_ XCP_epblRequest : 7|64@0+ (1,0) [0|18446744073709551615] ""  X

BO_ 1022 APP_summonCommand: 8 CH
 SG_ APP_summonCommandChecksum : 56|8@1+ (1,0) [0|255] ""  aps
 SG_ APP_summonCommandCounter : 52|4@1+ (1,0) [0|15] ""  aps
 SG_ APP_summonState : 48|3@1+ (1,0) [0|7] ""  aps
 SG_ APP_summonMaxVelocity : 40|8@1+ (0.05,0) [0|12.75] "kph"  aps
 SG_ APP_summonInstruction : 32|3@1+ (1,0) [0|7] ""  aps
 SG_ APP_summonDistance : 16|16@1+ (0.01,0) [0|655.35] "m"  aps
 SG_ APP_summonSteeringAngleRequest : 0|15@1+ (0.1,-1638.35) [-1638.35|1638.35] "deg"  aps

BA_DEF_ SG_  "SystemSignalLongSymbol" STRING ;
BA_DEF_DEF_  "SystemSignalLongSymbol" "";
BA_ "SystemSignalLongSymbol" SG_ 1293 TAS_a098_VCFRONT_systemStatus_MI "TAS_a098_VCFRONT_systemStatus_MIA";
BA_ "SystemSignalLongSymbol" SG_ 1293 TAS_a098_VCFRONT_okToUseHighPowe "TAS_a098_VCFRONT_okToUseHighPower_MIA";
BA_ "SystemSignalLongSymbol" SG_ 1293 TAS_a098_VCFRONT_LVPowerState_MI "TAS_a098_VCFRONT_LVPowerState_MIA";
VAL_ 1824 DAS_LCM_CIPV_type 2 "TYPE_BICYCLIST" 0 "TYPE_VEHICLE" 1 "TYPE_PEDESTRIAN" 3 "TYPE_UNKNOWN" ;
VAL_ 1824 DAS_ACC_controlType 1 "ACC_CONTROL_TYPE_CRUISE" 2 "ACC_CONTROL_TYPE_TARGET" 0 "ACC_CONTROL_TYPE_NONE" 4 "ACC_CONTROL_TYPE_MIXED_LC_AND_TARGET" 3 "ACC_CONTROL_TYPE_LC" ;
VAL_ 1824 DAS_laneMerge 2 "Right_Merge" 0 "No_Merge" 1 "Left_Merge" 3 "Reserved" ;
VAL_ 1824 DAS_LCM_fcw_unavailable_reason 12 "FCW_DAS_FEATURES_DISABLED" 13 "FCW_OBJECT_TRACKER_HEALTH" 5 "FCW_GEAR_ISSUE" 0 "FCW_NO_CANCEL" 7 "FCW_TURN_INDICATOR_SNA" 3 "FCW_STEERING_ANGLE_RATE_INVALID" 6 "FCW_STABILITY_CONTROL_FAULT" 2 "FCW_STEERING_ANGLE_INVALID" 11 "FCW_FCW_SENSITIVITY_INVALID" 4 "FCW_VEHICLE_SPEED_INVALID" 1 "FCW_DRIVER_BRAKE_APPLY_INVALID" 8 "FCW_YAW_RATE_INVALID" 10 "FCW_ACCELERATOR_PEDAL_INVALID" 9 "FCW_LONGITUDINAL_ACCELERATION_INVALID" ;
VAL_ 1824 DAS_ACC_Target6_type 10 "PEDESTRIAN" 0 "NONE" 6 "CAMERA_CUTIN" 2 "STATIONARY_RADAR" 7 "STOP_SIGN" 8 "TRAFFIC_LIGHT" 4 "FUSED_CAMERA" 3 "MOVING_RADAR" 11 "FAULT" 5 "FUSED_RADAR" 9 "IPSO" 1 "CAMERA" ;
VAL_ 1824 DAS_ACC_tgt_cipv2_type 10 "PEDESTRIAN" 0 "NONE" 6 "CAMERA_CUTIN" 2 "STATIONARY_RADAR" 7 "STOP_SIGN" 8 "TRAFFIC_LIGHT" 4 "FUSED_CAMERA" 3 "MOVING_RADAR" 11 "FAULT" 5 "FUSED_RADAR" 9 "IPSO" 1 "CAMERA" ;
VAL_ 1824 DAS_ACC_tgt_mcvl_type 10 "PEDESTRIAN" 0 "NONE" 6 "CAMERA_CUTIN" 2 "STATIONARY_RADAR" 7 "STOP_SIGN" 8 "TRAFFIC_LIGHT" 4 "FUSED_CAMERA" 3 "MOVING_RADAR" 11 "FAULT" 5 "FUSED_RADAR" 9 "IPSO" 1 "CAMERA" ;
VAL_ 1824 DAS_ACC_tgt_cutin_type 10 "PEDESTRIAN" 0 "NONE" 6 "CAMERA_CUTIN" 2 "STATIONARY_RADAR" 7 "STOP_SIGN" 8 "TRAFFIC_LIGHT" 4 "FUSED_CAMERA" 3 "MOVING_RADAR" 11 "FAULT" 5 "FUSED_RADAR" 9 "IPSO" 1 "CAMERA" ;
VAL_ 1824 DAS_ACC_tgt_mcvr_type 10 "PEDESTRIAN" 0 "NONE" 6 "CAMERA_CUTIN" 2 "STATIONARY_RADAR" 7 "STOP_SIGN" 8 "TRAFFIC_LIGHT" 4 "FUSED_CAMERA" 3 "MOVING_RADAR" 11 "FAULT" 5 "FUSED_RADAR" 9 "IPSO" 1 "CAMERA" ;
VAL_ 1824 DAS_ACC_tgt_cipv_type 10 "PEDESTRIAN" 0 "NONE" 6 "CAMERA_CUTIN" 2 "STATIONARY_RADAR" 7 "STOP_SIGN" 8 "TRAFFIC_LIGHT" 4 "FUSED_CAMERA" 3 "MOVING_RADAR" 11 "FAULT" 5 "FUSED_RADAR" 9 "IPSO" 1 "CAMERA" ;
VAL_ 1824 DAS_ACC_Target6_controlState 8 "CUT_IN" 5 "PRE_OVERTAKE" 6 "OVERTAKE" 10 "MCVR_IN_PATH" 0 "IRRELEVANT" 2 "DEFAULT" 7 "CUT_OUT" 4 "STEADY_STATE" 9 "MCVR_DPP" 1 "EVALUATE" 3 "UNDERTAKE" ;
VAL_ 1824 DAS_LCM_aeb_unavailable_reason 7 "AEB_DRIVER_BRAKE_APPLY_INVALID" 1 "AEB_DI_AEB_STATE_UNAVAILABLE" 2 "AEB_DI_AEB_STATE_FAULT" 6 "AEB_ACCELERATOR_PEDAL_INVALID" 14 "AEB_GEAR_ISSUE" 5 "AEB_SEATBELT_STATUS_UNKNOWN" 9 "AEB_STEERING_ANGLE_INVALID" 11 "AEB_VEHICLE_SPEED_INVALID" 13 "AEB_YAW_RATE_INVALID" 16 "AEB_DAS_FEATURES_DISABLED" 17 "AEB_OBJECT_TRACKER_HEALTH" 8 "AEB_BRAKE_PEDAL_STATE_INVALID" 12 "AEB_LONGITUDINAL_ACCELERATION_INVALID" 3 "AEB_HIGH_LATERAL_ACCELERATION" 15 "AEB_STABILITY_CONTROL_FAULT" 4 "AEB_TURN_INDICATOR_SNA" 0 "AEB_NO_CANCEL" 10 "AEB_STEERING_ANGLE_RATE_INVALID" ;
VAL_ 1824 DAS_ACC_tgt_cipv2_controlState 8 "CUT_IN" 5 "PRE_OVERTAKE" 6 "OVERTAKE" 10 "MCVR_IN_PATH" 0 "IRRELEVANT" 2 "DEFAULT" 7 "CUT_OUT" 4 "STEADY_STATE" 9 "MCVR_DPP" 1 "EVALUATE" 3 "UNDERTAKE" ;
VAL_ 1824 DAS_ACC_tgt_mcvl_controlState 8 "CUT_IN" 5 "PRE_OVERTAKE" 6 "OVERTAKE" 10 "MCVR_IN_PATH" 0 "IRRELEVANT" 2 "DEFAULT" 7 "CUT_OUT" 4 "STEADY_STATE" 9 "MCVR_DPP" 1 "EVALUATE" 3 "UNDERTAKE" ;
VAL_ 1824 DAS_ACC_tgt_cutin_controlState 8 "CUT_IN" 5 "PRE_OVERTAKE" 6 "OVERTAKE" 10 "MCVR_IN_PATH" 0 "IRRELEVANT" 2 "DEFAULT" 7 "CUT_OUT" 4 "STEADY_STATE" 9 "MCVR_DPP" 1 "EVALUATE" 3 "UNDERTAKE" ;
VAL_ 1824 DAS_ACC_tgt_mcvr_controlState 8 "CUT_IN" 5 "PRE_OVERTAKE" 6 "OVERTAKE" 10 "MCVR_IN_PATH" 0 "IRRELEVANT" 2 "DEFAULT" 7 "CUT_OUT" 4 "STEADY_STATE" 9 "MCVR_DPP" 1 "EVALUATE" 3 "UNDERTAKE" ;
VAL_ 1824 DAS_ACC_tgt_cipv_controlState 8 "CUT_IN" 5 "PRE_OVERTAKE" 6 "OVERTAKE" 10 "MCVR_IN_PATH" 0 "IRRELEVANT" 2 "DEFAULT" 7 "CUT_OUT" 4 "STEADY_STATE" 9 "MCVR_DPP" 1 "EVALUATE" 3 "UNDERTAKE" ;
VAL_ 1824 DAS_IDF_measurementState 1 "MEASURED" 0 "NONE" 2 "EXTRAPOLATED" ;
VAL_ 1824 DAS_LCM_state 6 "LCM_STATE_JERK_ACTIVE" 9 "LCM_STATE_AEB_OVERRIDE" 8 "LCM_STATE_AEB_ACTIVE" 7 "LCM_STATE_JERK_OVERRIDE" 10 "LCM_STATE_STATIONARY_MANAGEMENT" 3 "LCM_STATE_AVAILABLE" 4 "LCM_STATE_FCW_ACTIVE" 5 "LCM_STATE_FCW_OVERRIDE" 0 "LCM_STATE_FAULT" 2 "LCM_STATE_UNAVAILABLE" 1 "LCM_STATE_OFF" ;
VAL_ 1824 DAS_ACC_Target6_radID 63 "SNA" ;
VAL_ 1824 DAS_ACC_tgt_mcvl_radID 63 "SNA" ;
VAL_ 1824 DAS_ACC_tgt_mcvr_radID 63 "SNA" ;
VAL_ 1824 DAS_ACC_tgt_cipv2_radID 63 "SNA" ;
VAL_ 1824 DAS_ACC_tgt_cipv_radID 63 "SNA" ;
VAL_ 1824 DAS_ACC_tgt_cutin_radID 63 "SNA" ;
VAL_ 1824 DAS_LC_AutopilotInternalState 14 "LC_INTERNAL_STATE_DRIVER_STEERING_OVERRIDE" 2 "LC_INTERNAL_STATE_UNAVAILABLE" 12 "LC_INTERNAL_STATE_FAULT" 9 "LC_INTERNAL_STATE_CHECK_ACTIVATION_WHILE_UNAVAILABLE" 5 "LC_INTERNAL_STATE_PREACTIVATION" 11 "LC_INTERNAL_STATE_ABORTED" 3 "LC_INTERNAL_STATE_AVAILABLE" 13 "LC_INTERNAL_STATE_PREABORTED" 0 "LC_INTERNAL_STATE_NO_AUTOPILOT" 10 "LC_INTERNAL_STATE_ABORTING" 8 "LC_INTERNAL_STATE_CHECK_ACTIVATION_WHILE_DISABLED" 6 "LC_INTERNAL_STATE_ACTIVE_NOMINAL" 1 "LC_INTERNAL_STATE_DISABLED" 7 "LC_INTERNAL_STATE_ACTIVE_RESTRICTED" 15 "LC_INTERNAL_STATE_PRECANCEL" 4 "LC_INTERNAL_STATE_CHECK_FOR_ACTIVATION" ;
VAL_ 1824 DAS_IDF_objectClass 5 "PEDESTRIAN" 0 "UNKNOWN" 4 "BICYCLE" 3 "MOTORCYCLE" 2 "CAR" 1 "TRUCK" ;
VAL_ 1824 DAS_VL_WidthMeasType 4 "DECAY_TO_NOMINAL" 5 "HOLDING" 2 "RIGHT_LANE_LEFT_FREESPACE" 6 "NO_MEAS_LOW_SPEED" 1 "LEFT_LANE_RIGHT_FREESPACE" 0 "BOTH_LANES" 3 "BOTH_FREESPACE" 7 "ONE_LINE_AND_HPP" ;
VAL_ 1824 DAS_ACC_tgt_cipv_camID 0 "SNA" ;
VAL_ 1824 DAS_ACC_Target6_camID 0 "SNA" ;
VAL_ 1824 DAS_ACC_tgt_cutin_camID 0 "SNA" ;
VAL_ 1824 DAS_ACC_tgt_mcvl_camID 0 "SNA" ;
VAL_ 1824 DAS_ACC_tgt_mcvr_camID 0 "SNA" ;
VAL_ 1824 DAS_ACC_tgt_cipv2_camID 0 "SNA" ;
VAL_ 1824 DAS_ACC_intState 10 "ACC_INT_STATE_CANCEL_GENERIC_SILENT" 6 "ACC_INT_STATE_CANCEL_CAMERA" 4 "ACC_INT_STATE_READYFORRESUME" 11 "ACC_INT_STATE_CANCEL_OUT_OF_CALIBRATION" 1 "ACC_INT_STATE_ACTIVE" 7 "ACC_INT_STATE_CANCEL_RADAR" 9 "ACC_INT_STATE_CANCEL_PATH_NOT_CLEAR" 5 "ACC_INT_STATE_CANCEL_GENERIC" 3 "ACC_INT_STATE_HOLD" 2 "ACC_INT_STATE_STANDSTILL" 8 "ACC_INT_STATE_FAULT" 0 "ACC_INT_STATE_IDLE" ;
VAL_ 1824 DAS_debugMultiplexer 46 "LC_Planner_Debug" 24 "ACC_Target3" 43 "VIRTUAL_WALL_LEFT" 50 "Virtual_Lane_Debug1" 30 "FCM_Debug1" 44 "VIRTUAL_WALL_RIGHT" 21 "ACC_Camera" 26 "ACC_Target5" 23 "ACC_Target2" 100 "DAS_CH_Time_Sync" 28 "ACC_Control1" 0 "EyeQ_Status" 25 "ACC_Target4" 11 "PMM_debug" 22 "ACC_Target1" 12 "I2C_debug" 41 "HEALTH_MONITOR_1" 40 "Lateral_Debug1" 51 "Virtual_Lane_Debug2" 31 "FCM_Debug2" 33 "FCM_Debug4" 42 "HEALTH_MONITOR_2" 4 "TFL_TSR_Debug" 53 "Virtual_Lane_Debug4" 52 "Virtual_Lane_Debug3" 32 "FCM_Debug3" 60 "Autowipers" 49 "Path_Planner" 3 "Cam_Watchdog_Debug" 29 "ACC_Control2" 48 "TP_LaneChange" 10 "EyeQ_Image_Dump" 54 "Virtual_Lane_Debug5" 47 "LC_HandsOnDetector" 1 "EyeQ_Calibrations" 5 "Road_Furniture_Debug" 20 "ACC_State" 27 "ACC_Target6" 45 "SCA" 2 "LDW_Debug" ;
VAL_ 289 RCM_crashAlgoWakeup 0 "RCM_CRASH_ALGO_WAKEUP_EVENT_INACTIVE" 3 "RCM_CRASH_ALGO_WAKEUP_EVENT_SNA" 1 "RCM_CRASH_ALGO_WAKEUP_EVENT_ACTIVE" ;
VAL_ 289 RCM_nearDeployRollover 0 "RCM_NEAR_DEPLOY_EVENT_INACTIVE" 1 "RCM_NEAR_DEPLOY_EVENT_ACTIVE" 3 "RCM_NEAR_DEPLOY_EVENT_SNA" ;
VAL_ 289 RCM_nearDeployFront 0 "RCM_NEAR_DEPLOY_EVENT_INACTIVE" 1 "RCM_NEAR_DEPLOY_EVENT_ACTIVE" 3 "RCM_NEAR_DEPLOY_EVENT_SNA" ;
VAL_ 289 RCM_nearDeployLeft 0 "RCM_NEAR_DEPLOY_EVENT_INACTIVE" 1 "RCM_NEAR_DEPLOY_EVENT_ACTIVE" 3 "RCM_NEAR_DEPLOY_EVENT_SNA" ;
VAL_ 289 RCM_nearDeployRight 0 "RCM_NEAR_DEPLOY_EVENT_INACTIVE" 1 "RCM_NEAR_DEPLOY_EVENT_ACTIVE" 3 "RCM_NEAR_DEPLOY_EVENT_SNA" ;
VAL_ 289 RCM_nearDeployRear 0 "RCM_NEAR_DEPLOY_EVENT_INACTIVE" 1 "RCM_NEAR_DEPLOY_EVENT_ACTIVE" 3 "RCM_NEAR_DEPLOY_EVENT_SNA" ;
VAL_ 1293 TAS_a031_PWMfaultFR 2 "PWM_OVER_MAX_PERIOD" 5 "PWM_SHORT_CIRCUIT" 0 "PWM_OVER_MAX_DUTY" 4 "PWM_OVER_MAX_DELTA_DUTY" 3 "PWM_UNDER_MIN_PERIOD" 6 "PWM_OPEN_CIRCUIT" 1 "PWM_UNDER_MIN_DUTY" ;
VAL_ 1293 TAS_a038_PWMfaultFL 2 "PWM_OVER_MAX_PERIOD" 5 "PWM_SHORT_CIRCUIT" 0 "PWM_OVER_MAX_DUTY" 4 "PWM_OVER_MAX_DELTA_DUTY" 3 "PWM_UNDER_MIN_PERIOD" 6 "PWM_OPEN_CIRCUIT" 1 "PWM_UNDER_MIN_DUTY" ;
VAL_ 1293 TAS_a229_PWMfaultRR 2 "PWM_OVER_MAX_PERIOD" 5 "PWM_SHORT_CIRCUIT" 0 "PWM_OVER_MAX_DUTY" 4 "PWM_OVER_MAX_DELTA_DUTY" 3 "PWM_UNDER_MIN_PERIOD" 6 "PWM_OPEN_CIRCUIT" 1 "PWM_UNDER_MIN_DUTY" ;
VAL_ 1293 TAS_a032_PWMfaultRL 2 "PWM_OVER_MAX_PERIOD" 5 "PWM_SHORT_CIRCUIT" 0 "PWM_OVER_MAX_DUTY" 4 "PWM_OVER_MAX_DELTA_DUTY" 3 "PWM_UNDER_MIN_PERIOD" 6 "PWM_OPEN_CIRCUIT" 1 "PWM_UNDER_MIN_DUTY" ;
VAL_ 1293 TAS_a033_PWMfaultRR 2 "PWM_OVER_MAX_PERIOD" 5 "PWM_SHORT_CIRCUIT" 0 "PWM_OVER_MAX_DUTY" 4 "PWM_OVER_MAX_DELTA_DUTY" 3 "PWM_UNDER_MIN_PERIOD" 6 "PWM_OPEN_CIRCUIT" 1 "PWM_UNDER_MIN_DUTY" ;
VAL_ 1293 TAS_a039_PWMfaultFR 2 "PWM_OVER_MAX_PERIOD" 5 "PWM_SHORT_CIRCUIT" 0 "PWM_OVER_MAX_DUTY" 4 "PWM_OVER_MAX_DELTA_DUTY" 3 "PWM_UNDER_MIN_PERIOD" 6 "PWM_OPEN_CIRCUIT" 1 "PWM_UNDER_MIN_DUTY" ;
VAL_ 1293 TAS_a228_PWMfaultRL 2 "PWM_OVER_MAX_PERIOD" 5 "PWM_SHORT_CIRCUIT" 0 "PWM_OVER_MAX_DUTY" 4 "PWM_OVER_MAX_DELTA_DUTY" 3 "PWM_UNDER_MIN_PERIOD" 6 "PWM_OPEN_CIRCUIT" 1 "PWM_UNDER_MIN_DUTY" ;
VAL_ 1293 TAS_a030_PWMfaultFL 2 "PWM_OVER_MAX_PERIOD" 5 "PWM_SHORT_CIRCUIT" 0 "PWM_OVER_MAX_DUTY" 4 "PWM_OVER_MAX_DELTA_DUTY" 3 "PWM_UNDER_MIN_PERIOD" 6 "PWM_OPEN_CIRCUIT" 1 "PWM_UNDER_MIN_DUTY" ;
VAL_ 1293 TAS_a037_PWMfaultRR 2 "PWM_OVER_MAX_PERIOD" 5 "PWM_SHORT_CIRCUIT" 0 "PWM_OVER_MAX_DUTY" 4 "PWM_OVER_MAX_DELTA_DUTY" 3 "PWM_UNDER_MIN_PERIOD" 6 "PWM_OPEN_CIRCUIT" 1 "PWM_UNDER_MIN_DUTY" ;
VAL_ 1293 TAS_a226_PWMfaultFL 2 "PWM_OVER_MAX_PERIOD" 5 "PWM_SHORT_CIRCUIT" 0 "PWM_OVER_MAX_DUTY" 4 "PWM_OVER_MAX_DELTA_DUTY" 3 "PWM_UNDER_MIN_PERIOD" 6 "PWM_OPEN_CIRCUIT" 1 "PWM_UNDER_MIN_DUTY" ;
VAL_ 1293 TAS_a035_PWMfaultFR 2 "PWM_OVER_MAX_PERIOD" 5 "PWM_SHORT_CIRCUIT" 0 "PWM_OVER_MAX_DUTY" 4 "PWM_OVER_MAX_DELTA_DUTY" 3 "PWM_UNDER_MIN_PERIOD" 6 "PWM_OPEN_CIRCUIT" 1 "PWM_UNDER_MIN_DUTY" ;
VAL_ 1293 TAS_a040_PWMfaultRL 2 "PWM_OVER_MAX_PERIOD" 5 "PWM_SHORT_CIRCUIT" 0 "PWM_OVER_MAX_DUTY" 4 "PWM_OVER_MAX_DELTA_DUTY" 3 "PWM_UNDER_MIN_PERIOD" 6 "PWM_OPEN_CIRCUIT" 1 "PWM_UNDER_MIN_DUTY" ;
VAL_ 1293 TAS_a034_PWMfaultFL 2 "PWM_OVER_MAX_PERIOD" 5 "PWM_SHORT_CIRCUIT" 0 "PWM_OVER_MAX_DUTY" 4 "PWM_OVER_MAX_DELTA_DUTY" 3 "PWM_UNDER_MIN_PERIOD" 6 "PWM_OPEN_CIRCUIT" 1 "PWM_UNDER_MIN_DUTY" ;
VAL_ 1293 TAS_a041_PWMfaultRR 2 "PWM_OVER_MAX_PERIOD" 5 "PWM_SHORT_CIRCUIT" 0 "PWM_OVER_MAX_DUTY" 4 "PWM_OVER_MAX_DELTA_DUTY" 3 "PWM_UNDER_MIN_PERIOD" 6 "PWM_OPEN_CIRCUIT" 1 "PWM_UNDER_MIN_DUTY" ;
VAL_ 1293 TAS_a036_PWMfaultRL 2 "PWM_OVER_MAX_PERIOD" 5 "PWM_SHORT_CIRCUIT" 0 "PWM_OVER_MAX_DUTY" 4 "PWM_OVER_MAX_DELTA_DUTY" 3 "PWM_UNDER_MIN_PERIOD" 6 "PWM_OPEN_CIRCUIT" 1 "PWM_UNDER_MIN_DUTY" ;
VAL_ 1293 TAS_a227_PWMfaultFR 2 "PWM_OVER_MAX_PERIOD" 5 "PWM_SHORT_CIRCUIT" 0 "PWM_OVER_MAX_DUTY" 4 "PWM_OVER_MAX_DELTA_DUTY" 3 "PWM_UNDER_MIN_PERIOD" 6 "PWM_OPEN_CIRCUIT" 1 "PWM_UNDER_MIN_DUTY" ;
VAL_ 1293 TAS_a079_GTW 2 "DRIVER_SIDE_RIGHT" 0 "DRIVER_SIDE_UNKNOWN" 1 "DRIVER_SIDE_LEFT" ;
VAL_ 1293 TAS_a141_valveFaultType 4 "VALVE_HS_DRIVE_STUCK_ON" 7 "VALVE_OTHER_CIRCUIT" 0 "VALVE_OVER_DUTY_CYCLE_LIMIT" 1 "VALVE_OPEN_CIRCUIT" 3 "VALVE_SHORT_CIRCUIT_12V" 6 "VALVE_SENSOR_ERROR" 5 "VALVE_HS_DRIVE_STUCK_OFF" 2 "VALVE_SHORT_CIRCUIT_GND" ;
VAL_ 1293 TAS_a158_valveFaultType 4 "VALVE_HS_DRIVE_STUCK_ON" 7 "VALVE_OTHER_CIRCUIT" 0 "VALVE_OVER_DUTY_CYCLE_LIMIT" 1 "VALVE_OPEN_CIRCUIT" 3 "VALVE_SHORT_CIRCUIT_12V" 6 "VALVE_SENSOR_ERROR" 5 "VALVE_HS_DRIVE_STUCK_OFF" 2 "VALVE_SHORT_CIRCUIT_GND" ;
VAL_ 1293 TAS_a164_valveFaultType 4 "VALVE_HS_DRIVE_STUCK_ON" 7 "VALVE_OTHER_CIRCUIT" 0 "VALVE_OVER_DUTY_CYCLE_LIMIT" 1 "VALVE_OPEN_CIRCUIT" 3 "VALVE_SHORT_CIRCUIT_12V" 6 "VALVE_SENSOR_ERROR" 5 "VALVE_HS_DRIVE_STUCK_OFF" 2 "VALVE_SHORT_CIRCUIT_GND" ;
VAL_ 1293 TAS_a139_valveFaultType 4 "VALVE_HS_DRIVE_STUCK_ON" 7 "VALVE_OTHER_CIRCUIT" 0 "VALVE_OVER_DUTY_CYCLE_LIMIT" 1 "VALVE_OPEN_CIRCUIT" 3 "VALVE_SHORT_CIRCUIT_12V" 6 "VALVE_SENSOR_ERROR" 5 "VALVE_HS_DRIVE_STUCK_OFF" 2 "VALVE_SHORT_CIRCUIT_GND" ;
VAL_ 1293 TAS_a146_valveFaultType 4 "VALVE_HS_DRIVE_STUCK_ON" 7 "VALVE_OTHER_CIRCUIT" 0 "VALVE_OVER_DUTY_CYCLE_LIMIT" 1 "VALVE_OPEN_CIRCUIT" 3 "VALVE_SHORT_CIRCUIT_12V" 6 "VALVE_SENSOR_ERROR" 5 "VALVE_HS_DRIVE_STUCK_OFF" 2 "VALVE_SHORT_CIRCUIT_GND" ;
VAL_ 1293 TAS_a152_valveFaultType 4 "VALVE_HS_DRIVE_STUCK_ON" 7 "VALVE_OTHER_CIRCUIT" 0 "VALVE_OVER_DUTY_CYCLE_LIMIT" 1 "VALVE_OPEN_CIRCUIT" 3 "VALVE_SHORT_CIRCUIT_12V" 6 "VALVE_SENSOR_ERROR" 5 "VALVE_HS_DRIVE_STUCK_OFF" 2 "VALVE_SHORT_CIRCUIT_GND" ;
VAL_ 1293 TAS_a134_valveFaultType 4 "VALVE_HS_DRIVE_STUCK_ON" 7 "VALVE_OTHER_CIRCUIT" 0 "VALVE_OVER_DUTY_CYCLE_LIMIT" 1 "VALVE_OPEN_CIRCUIT" 3 "VALVE_SHORT_CIRCUIT_12V" 6 "VALVE_SENSOR_ERROR" 5 "VALVE_HS_DRIVE_STUCK_OFF" 2 "VALVE_SHORT_CIRCUIT_GND" ;
VAL_ 1293 TAS_a151_valveFaultType 4 "VALVE_HS_DRIVE_STUCK_ON" 7 "VALVE_OTHER_CIRCUIT" 0 "VALVE_OVER_DUTY_CYCLE_LIMIT" 1 "VALVE_OPEN_CIRCUIT" 3 "VALVE_SHORT_CIRCUIT_12V" 6 "VALVE_SENSOR_ERROR" 5 "VALVE_HS_DRIVE_STUCK_OFF" 2 "VALVE_SHORT_CIRCUIT_GND" ;
VAL_ 1293 TAS_a148_valveFaultType 4 "VALVE_HS_DRIVE_STUCK_ON" 7 "VALVE_OTHER_CIRCUIT" 0 "VALVE_OVER_DUTY_CYCLE_LIMIT" 1 "VALVE_OPEN_CIRCUIT" 3 "VALVE_SHORT_CIRCUIT_12V" 6 "VALVE_SENSOR_ERROR" 5 "VALVE_HS_DRIVE_STUCK_OFF" 2 "VALVE_SHORT_CIRCUIT_GND" ;
VAL_ 1293 TAS_a137_valveFaultType 4 "VALVE_HS_DRIVE_STUCK_ON" 7 "VALVE_OTHER_CIRCUIT" 0 "VALVE_OVER_DUTY_CYCLE_LIMIT" 1 "VALVE_OPEN_CIRCUIT" 3 "VALVE_SHORT_CIRCUIT_12V" 6 "VALVE_SENSOR_ERROR" 5 "VALVE_HS_DRIVE_STUCK_OFF" 2 "VALVE_SHORT_CIRCUIT_GND" ;
VAL_ 1293 TAS_a132_valveFaultType 4 "VALVE_HS_DRIVE_STUCK_ON" 7 "VALVE_OTHER_CIRCUIT" 0 "VALVE_OVER_DUTY_CYCLE_LIMIT" 1 "VALVE_OPEN_CIRCUIT" 3 "VALVE_SHORT_CIRCUIT_12V" 6 "VALVE_SENSOR_ERROR" 5 "VALVE_HS_DRIVE_STUCK_OFF" 2 "VALVE_SHORT_CIRCUIT_GND" ;
VAL_ 1293 TAS_a154_valveFaultType 4 "VALVE_HS_DRIVE_STUCK_ON" 7 "VALVE_OTHER_CIRCUIT" 0 "VALVE_OVER_DUTY_CYCLE_LIMIT" 1 "VALVE_OPEN_CIRCUIT" 3 "VALVE_SHORT_CIRCUIT_12V" 6 "VALVE_SENSOR_ERROR" 5 "VALVE_HS_DRIVE_STUCK_OFF" 2 "VALVE_SHORT_CIRCUIT_GND" ;
VAL_ 1293 TAS_a160_valveFaultType 4 "VALVE_HS_DRIVE_STUCK_ON" 7 "VALVE_OTHER_CIRCUIT" 0 "VALVE_OVER_DUTY_CYCLE_LIMIT" 1 "VALVE_OPEN_CIRCUIT" 3 "VALVE_SHORT_CIRCUIT_12V" 6 "VALVE_SENSOR_ERROR" 5 "VALVE_HS_DRIVE_STUCK_OFF" 2 "VALVE_SHORT_CIRCUIT_GND" ;
VAL_ 1293 TAS_a142_valveFaultType 4 "VALVE_HS_DRIVE_STUCK_ON" 7 "VALVE_OTHER_CIRCUIT" 0 "VALVE_OVER_DUTY_CYCLE_LIMIT" 1 "VALVE_OPEN_CIRCUIT" 3 "VALVE_SHORT_CIRCUIT_12V" 6 "VALVE_SENSOR_ERROR" 5 "VALVE_HS_DRIVE_STUCK_OFF" 2 "VALVE_SHORT_CIRCUIT_GND" ;
VAL_ 1293 TAS_a147_valveFaultType 4 "VALVE_HS_DRIVE_STUCK_ON" 7 "VALVE_OTHER_CIRCUIT" 0 "VALVE_OVER_DUTY_CYCLE_LIMIT" 1 "VALVE_OPEN_CIRCUIT" 3 "VALVE_SHORT_CIRCUIT_12V" 6 "VALVE_SENSOR_ERROR" 5 "VALVE_HS_DRIVE_STUCK_OFF" 2 "VALVE_SHORT_CIRCUIT_GND" ;
VAL_ 1293 TAS_a138_valveFaultType 4 "VALVE_HS_DRIVE_STUCK_ON" 7 "VALVE_OTHER_CIRCUIT" 0 "VALVE_OVER_DUTY_CYCLE_LIMIT" 1 "VALVE_OPEN_CIRCUIT" 3 "VALVE_SHORT_CIRCUIT_12V" 6 "VALVE_SENSOR_ERROR" 5 "VALVE_HS_DRIVE_STUCK_OFF" 2 "VALVE_SHORT_CIRCUIT_GND" ;
VAL_ 1293 TAS_a144_valveFaultType 4 "VALVE_HS_DRIVE_STUCK_ON" 7 "VALVE_OTHER_CIRCUIT" 0 "VALVE_OVER_DUTY_CYCLE_LIMIT" 1 "VALVE_OPEN_CIRCUIT" 3 "VALVE_SHORT_CIRCUIT_12V" 6 "VALVE_SENSOR_ERROR" 5 "VALVE_HS_DRIVE_STUCK_OFF" 2 "VALVE_SHORT_CIRCUIT_GND" ;
VAL_ 1293 TAS_a150_valveFaultType 4 "VALVE_HS_DRIVE_STUCK_ON" 7 "VALVE_OTHER_CIRCUIT" 0 "VALVE_OVER_DUTY_CYCLE_LIMIT" 1 "VALVE_OPEN_CIRCUIT" 3 "VALVE_SHORT_CIRCUIT_12V" 6 "VALVE_SENSOR_ERROR" 5 "VALVE_HS_DRIVE_STUCK_OFF" 2 "VALVE_SHORT_CIRCUIT_GND" ;
VAL_ 1293 TAS_a149_valveFaultType 4 "VALVE_HS_DRIVE_STUCK_ON" 7 "VALVE_OTHER_CIRCUIT" 0 "VALVE_OVER_DUTY_CYCLE_LIMIT" 1 "VALVE_OPEN_CIRCUIT" 3 "VALVE_SHORT_CIRCUIT_12V" 6 "VALVE_SENSOR_ERROR" 5 "VALVE_HS_DRIVE_STUCK_OFF" 2 "VALVE_SHORT_CIRCUIT_GND" ;
VAL_ 1293 TAS_a136_valveFaultType 4 "VALVE_HS_DRIVE_STUCK_ON" 7 "VALVE_OTHER_CIRCUIT" 0 "VALVE_OVER_DUTY_CYCLE_LIMIT" 1 "VALVE_OPEN_CIRCUIT" 3 "VALVE_SHORT_CIRCUIT_12V" 6 "VALVE_SENSOR_ERROR" 5 "VALVE_HS_DRIVE_STUCK_OFF" 2 "VALVE_SHORT_CIRCUIT_GND" ;
VAL_ 1293 TAS_a131_valveFaultType 4 "VALVE_HS_DRIVE_STUCK_ON" 7 "VALVE_OTHER_CIRCUIT" 0 "VALVE_OVER_DUTY_CYCLE_LIMIT" 1 "VALVE_OPEN_CIRCUIT" 3 "VALVE_SHORT_CIRCUIT_12V" 6 "VALVE_SENSOR_ERROR" 5 "VALVE_HS_DRIVE_STUCK_OFF" 2 "VALVE_SHORT_CIRCUIT_GND" ;
VAL_ 1293 TAS_a157_valveFaultType 4 "VALVE_HS_DRIVE_STUCK_ON" 7 "VALVE_OTHER_CIRCUIT" 0 "VALVE_OVER_DUTY_CYCLE_LIMIT" 1 "VALVE_OPEN_CIRCUIT" 3 "VALVE_SHORT_CIRCUIT_12V" 6 "VALVE_SENSOR_ERROR" 5 "VALVE_HS_DRIVE_STUCK_OFF" 2 "VALVE_SHORT_CIRCUIT_GND" ;
VAL_ 1293 TAS_a143_valveFaultType 4 "VALVE_HS_DRIVE_STUCK_ON" 7 "VALVE_OTHER_CIRCUIT" 0 "VALVE_OVER_DUTY_CYCLE_LIMIT" 1 "VALVE_OPEN_CIRCUIT" 3 "VALVE_SHORT_CIRCUIT_12V" 6 "VALVE_SENSOR_ERROR" 5 "VALVE_HS_DRIVE_STUCK_OFF" 2 "VALVE_SHORT_CIRCUIT_GND" ;
VAL_ 1293 TAS_a159_valveFaultType 4 "VALVE_HS_DRIVE_STUCK_ON" 7 "VALVE_OTHER_CIRCUIT" 0 "VALVE_OVER_DUTY_CYCLE_LIMIT" 1 "VALVE_OPEN_CIRCUIT" 3 "VALVE_SHORT_CIRCUIT_12V" 6 "VALVE_SENSOR_ERROR" 5 "VALVE_HS_DRIVE_STUCK_OFF" 2 "VALVE_SHORT_CIRCUIT_GND" ;
VAL_ 1293 TAS_a140_valveFaultType 4 "VALVE_HS_DRIVE_STUCK_ON" 7 "VALVE_OTHER_CIRCUIT" 0 "VALVE_OVER_DUTY_CYCLE_LIMIT" 1 "VALVE_OPEN_CIRCUIT" 3 "VALVE_SHORT_CIRCUIT_12V" 6 "VALVE_SENSOR_ERROR" 5 "VALVE_HS_DRIVE_STUCK_OFF" 2 "VALVE_SHORT_CIRCUIT_GND" ;
VAL_ 1293 TAS_a145_valveFaultType 4 "VALVE_HS_DRIVE_STUCK_ON" 7 "VALVE_OTHER_CIRCUIT" 0 "VALVE_OVER_DUTY_CYCLE_LIMIT" 1 "VALVE_OPEN_CIRCUIT" 3 "VALVE_SHORT_CIRCUIT_12V" 6 "VALVE_SENSOR_ERROR" 5 "VALVE_HS_DRIVE_STUCK_OFF" 2 "VALVE_SHORT_CIRCUIT_GND" ;
VAL_ 1293 TAS_a135_valveFaultType 4 "VALVE_HS_DRIVE_STUCK_ON" 7 "VALVE_OTHER_CIRCUIT" 0 "VALVE_OVER_DUTY_CYCLE_LIMIT" 1 "VALVE_OPEN_CIRCUIT" 3 "VALVE_SHORT_CIRCUIT_12V" 6 "VALVE_SENSOR_ERROR" 5 "VALVE_HS_DRIVE_STUCK_OFF" 2 "VALVE_SHORT_CIRCUIT_GND" ;
VAL_ 1293 TAS_a153_valveFaultType 4 "VALVE_HS_DRIVE_STUCK_ON" 7 "VALVE_OTHER_CIRCUIT" 0 "VALVE_OVER_DUTY_CYCLE_LIMIT" 1 "VALVE_OPEN_CIRCUIT" 3 "VALVE_SHORT_CIRCUIT_12V" 6 "VALVE_SENSOR_ERROR" 5 "VALVE_HS_DRIVE_STUCK_OFF" 2 "VALVE_SHORT_CIRCUIT_GND" ;
VAL_ 1293 TAS_a129_valveFaultType 4 "VALVE_HS_DRIVE_STUCK_ON" 7 "VALVE_OTHER_CIRCUIT" 0 "VALVE_OVER_DUTY_CYCLE_LIMIT" 1 "VALVE_OPEN_CIRCUIT" 3 "VALVE_SHORT_CIRCUIT_12V" 6 "VALVE_SENSOR_ERROR" 5 "VALVE_HS_DRIVE_STUCK_OFF" 2 "VALVE_SHORT_CIRCUIT_GND" ;
VAL_ 1293 TAS_a130_valveFaultType 4 "VALVE_HS_DRIVE_STUCK_ON" 7 "VALVE_OTHER_CIRCUIT" 0 "VALVE_OVER_DUTY_CYCLE_LIMIT" 1 "VALVE_OPEN_CIRCUIT" 3 "VALVE_SHORT_CIRCUIT_12V" 6 "VALVE_SENSOR_ERROR" 5 "VALVE_HS_DRIVE_STUCK_OFF" 2 "VALVE_SHORT_CIRCUIT_GND" ;
VAL_ 1293 TAS_a079_NVRAM 2 "DRIVER_SIDE_RIGHT" 0 "DRIVER_SIDE_UNKNOWN" 1 "DRIVER_SIDE_LEFT" ;
VAL_ 1293 TAS_a156_valveFaultType 4 "VALVE_HS_DRIVE_STUCK_ON" 7 "VALVE_OTHER_CIRCUIT" 0 "VALVE_OVER_DUTY_CYCLE_LIMIT" 1 "VALVE_OPEN_CIRCUIT" 3 "VALVE_SHORT_CIRCUIT_12V" 6 "VALVE_SENSOR_ERROR" 5 "VALVE_HS_DRIVE_STUCK_OFF" 2 "VALVE_SHORT_CIRCUIT_GND" ;
VAL_ 1293 TAS_a155_valveFaultType 4 "VALVE_HS_DRIVE_STUCK_ON" 7 "VALVE_OTHER_CIRCUIT" 0 "VALVE_OVER_DUTY_CYCLE_LIMIT" 1 "VALVE_OPEN_CIRCUIT" 3 "VALVE_SHORT_CIRCUIT_12V" 6 "VALVE_SENSOR_ERROR" 5 "VALVE_HS_DRIVE_STUCK_OFF" 2 "VALVE_SHORT_CIRCUIT_GND" ;
VAL_ 1293 TAS_a133_valveFaultType 4 "VALVE_HS_DRIVE_STUCK_ON" 7 "VALVE_OTHER_CIRCUIT" 0 "VALVE_OVER_DUTY_CYCLE_LIMIT" 1 "VALVE_OPEN_CIRCUIT" 3 "VALVE_SHORT_CIRCUIT_12V" 6 "VALVE_SENSOR_ERROR" 5 "VALVE_HS_DRIVE_STUCK_OFF" 2 "VALVE_SHORT_CIRCUIT_GND" ;
VAL_ 1293 TAS_alertType 0 "ALERT_CLEARED" 1 "ALERT_SET" ;
VAL_ 1293 TAS_alertID 217 "TAS_a217_limpHomeMode30" 215 "TAS_a215_limpHomeMode10" 36 "TAS_a036_PWMshortRL" 41 "TAS_a041_PWMopenRR" 144 "TAS_a144_shortCircuitCompressor" 154 "TAS_a154_otherCircuitFR" 30 "TAS_a030_PWMerrorFL" 164 "TAS_a164_calibrationVersion" 228 "TAS_a228_PWMfastDetectRL" 294 "TAS_a294_rearAxleTooLow" 78 "TAS_a078_pressureSigVTooHigh" 211 "TAS_a211_noRideHeightCalib" 126 "TAS_a126_maxDutyExhaust" 79 "TAS_a079_DvrSideCfgMismatch" 216 "TAS_a216_limpHomeMode20" 70 "TAS_a070_underVoltage12V" 151 "TAS_a151_boardFaultBoost" 136 "TAS_a136_openCircuitCompressor" 121 "TAS_a121_maxDutyFL" 14 "TAS_a014_BridgeFault" 12 "TAS_a012_CPUReset" 20 "TAS_a020_PWMError" 4 "TAS_a004_CANMIA" 34 "TAS_a034_PWMshortFL" 156 "TAS_a156_otherCircuitRR" 149 "TAS_a149_boardFaultReservoir" 122 "TAS_a122_maxDutyFR" 105 "TAS_a105_ECUDebugMode" 32 "TAS_a032_PWMerrorRL" 145 "TAS_a145_boardFaultFL" 15 "TAS_a015_NVMMAlert" 153 "TAS_a153_otherCircuitFL" 143 "TAS_a143_shortCircuitBoost" 225 "TAS_a225_galleryPressureTooHigh" 35 "TAS_a035_PWMshortFR" 33 "TAS_a033_PWMerrorRR" 10 "TAS_a010_ExtSupplyVoltError" 163 "TAS_a163_reservoirFillDisabled" 98 "TAS_a098_VCFRONT_MIA" 292 "TAS_a292_rearAxleTooHigh" 159 "TAS_a159_otherCircuitBoost" 71 "TAS_a071_overVoltage12V" 38 "TAS_a038_PWMopenFL" 7 "TAS_a007_LINTimeout" 129 "TAS_a129_openCircuitFL" 100 "TAS_a100_RCM_MIA" 139 "TAS_a139_shortCircuitRL" 37 "TAS_a037_PWMshortRR" 201 "TAS_a201_lowHVBattery" 147 "TAS_a147_boardFaultRL" 220 "TAS_a220_exhaustGalleryFault" 101 "TAS_a101_ESP_MIA" 102 "TAS_a102_DI_MIA" 31 "TAS_a031_PWMerrorFR" 291 "TAS_a291_frontAxleTooHigh" 130 "TAS_a130_openCircuitFR" 9 "TAS_a009_LIN3Error" 295 "TAS_a295_targetHeightNotMet" 123 "TAS_a123_maxDutyRL" 23 "TAS_a023_SleepError" 200 "TAS_a200_jackModeActive" 75 "TAS_a075_underVoltage5VOffBoard" 24 "TAS_a024_WakeError" 137 "TAS_a137_shortCircuitFL" 73 "TAS_a073_underVoltage5VOnBoard" 6 "TAS_a006_CANLowError" 99 "TAS_a099_UI_MIA" 77 "TAS_a077_pressureSigVTooLow" 222 "TAS_a222_compressorPrefillFault" 107 "TAS_a107_HighStackUsage" 218 "TAS_a218_limpHomeMode40" 2 "TAS_a002_PowerLossReset" 76 "TAS_a076_overVoltage5VOffBoard" 160 "TAS_a160_otherCircuitCompressor" 28 "TAS_a028_NVRAMNotResponding" 39 "TAS_a039_PWMopenFR" 142 "TAS_a142_shortCircuitExhaust" 155 "TAS_a155_otherCircuitRL" 25 "TAS_a025_CrashEvent" 128 "TAS_a128_maxDutyCompressor" 19 "TAS_a019_I2CError" 26 "TAS_a026_FlashMemoryError" 148 "TAS_a148_boardFaultRR" 135 "TAS_a135_openCircuitBoost" 157 "TAS_a157_otherCircuitReservoir" 152 "TAS_a152_boardFaultCompressor" 3 "TAS_a003_SWAssertion" 158 "TAS_a158_otherCircuitExhaust" 290 "TAS_a290_twistSustainedAtSpeed" 29 "TAS_a029_NVRAMUninitialized" 212 "TAS_a212_noCurrentSenseCalib" 17 "TAS_a017_AwakeForTooLong" 150 "TAS_a150_boardFaultExhaust" 131 "TAS_a131_openCircuitRL" 125 "TAS_a125_maxDutyReservoir" 0 "TAS_ALERT_DO_NOT_USE_ZERO" 162 "TAS_a162_compressorValveOpenGND" 124 "TAS_a124_maxDutyRR" 18 "TAS_a018_ADCError" 223 "TAS_a223_blockedAirline" 138 "TAS_a138_shortCircuitFR" 132 "TAS_a132_openCircuitRR" 134 "TAS_a134_openCircuitExhaust" 5 "TAS_a005_CANHighError" 133 "TAS_a133_openCircuitReservoir" 146 "TAS_a146_boardFaultFR" 22 "TAS_a022_TaskInitError" 141 "TAS_a141_shortCircuitReservoir" 103 "TAS_a103_GTW_MIA" 72 "TAS_a072_shortCircuit5VOnBoard" 74 "TAS_a074_shortCircuit5VOffBoard" 16 "TAS_a016_MessageTimingError" 224 "TAS_a224_openAirline" 40 "TAS_a040_PWMopenRL" 140 "TAS_a140_shortCircuitRR" 221 "TAS_a221_valveLeakDetected" 229 "TAS_a229_PWMfastDetectRR" 106 "TAS_a106_HighCPULoad" 293 "TAS_a293_frontAxleTooLow" 1 "TAS_a001_WatchdogReset" 8 "TAS_a008_LIN2Error" 11 "TAS_a011_ECUSupplyVoltError" 13 "TAS_a013_Shared13" 21 "TAS_a021_TaskSchedulerError" 93 "TAS_a093_OTPError" 127 "TAS_a127_maxDutyBoost" 210 "TAS_a210_outOfRangeCalibration" 226 "TAS_a226_PWMfastDetectFL" 161 "TAS_a161_valveBlockOpenGND" 214 "TAS_a214_redWarningLamp" 227 "TAS_a227_PWMfastDetectFR" 213 "TAS_a213_yellowWarningLamp" 27 "TAS_a027_NVRAMCorruption" ;
VAL_ 1429 OCS1P_alertType 0 "ALERT_CLEARED" 1 "ALERT_SET" ;
VAL_ 1429 OCS1P_alertID 128 "OCS1P_a128_seatbackSelfLow" 124 "OCS1P_a124_cushionSelfOpen" 123 "OCS1P_a123_sandwichShort" 134 "OCS1P_a134_uninitializedCalib" 141 "OCS1P_a141_humidityInvalidCalib" 131 "OCS1P_a131_cushionSelfNoCalib" 126 "OCS1P_a126_cushionSelfShort" 133 "OCS1P_a133_sandwichBadCalib" 130 "OCS1P_a130_sandwichNoCalib" 142 "OCS1P_a142_tempHumidityInvalid" 125 "OCS1P_a125_cushionSelfLow" 121 "OCS1P_a121_sandwichOpen" 122 "OCS1P_a122_sandwichLow" 132 "OCS1P_a132_seatbackSelfNoCalib" 140 "OCS1P_a140_tempInvalidCalib" 136 "OCS1P_a136_cushionSelfDutyLow" 139 "OCS1P_a139_seatbackSelfDutyHigh" 135 "OCS1P_a135_tempNoCalib" 0 "OCS1P_ALERT_DO_NOT_USE_ZERO" 129 "OCS1P_a129_seatbackSelfShort" 127 "OCS1P_a127_seatbackSelfOpen" 138 "OCS1P_a138_seatbackSelfDutyLow" 137 "OCS1P_a137_cushionSelfDutyHigh" ;
VAL_ 1160 DAS_steeringControlType 2 "LANE_KEEP_ASSIST" 0 "NONE" 1 "ANGLE_CONTROL" 3 "EMERGENCY_LANE_KEEP" ;
VAL_ 1160 DAS_steeringAngleRequest 16384 "ZERO_ANGLE" ;
VAL_ 1020 APP_pascalHeaterDecision 0 "OFF" 1 "ON" ;
VAL_ 1020 APP_parkerExtTemperature 0 "UNKNOWN" ;
VAL_ 1020 APP_pascalExtTemperature 0 "UNKNOWN" ;
VAL_ 1020 APP_parkerBTemperature 0 "UNKNOWN" ;
VAL_ 1020 APP_parkerATemperature 0 "UNKNOWN" ;
VAL_ 1020 APP_pascalTemperature 0 "UNKNOWN" ;
VAL_ 1020 APP_decisionTemperature 0 "UNKNOWN" ;
VAL_ 1465 DAS_sw060_collisionWarningSource 1 "SOURCE_FCW_VEHICLE" 4 "SOURCE_BCW_CIPV" 5 "SOURCE_BCW_CIPV2" 0 "SOURCE_FCW_PEDESTRIAN" 3 "SOURCE_BCW_CUTIN" 7 "SOURCE_BCW_PEDESTRIAN" 2 "SOURCE_STOPLINE" 6 "SOURCE_BCW_MCVLR" ;
VAL_ 1465 DAS_sw071_activationType 1 "KEYFOB" 0 "CELL_PHONE" 2 "AUTOSUMMON" ;
VAL_ 1465 DAS_sw194_reasonForHold 15 "SNA" 9 "CAM_ONLY_CONTROL" 1 "CAM_PEDESTRIAN" 7 "DRIVER_SEATBELT" 2 "ULTRASONIC_OBSTACLE" 4 "CAM_STOP_AND_GO" 5 "STOP_SIGN" 6 "TRAFFIC_LIGHT" 3 "TARGET_LOSS" 0 "TIMEOUT" 8 "MCP_CONTROL" ;
VAL_ 1465 DAS_sw207_lcUnavailableReason 44 "RR_UNAVAILABLE_INVALID_LANE_LINE_TYPE" 5 "LC_UNAVAILABLE_VEHICLE_NOT_IN_DRIVE" 31 "RR_UNAVAILABLE_HK_TW_RESTRICTED" 35 "RR_UNAVAILABLE_ME_MAIN_STATE_NOT_VISION" 14 "LC_UNAVAILABLE_USER_STRIKEOUT" 40 "RR_UNAVAILABLE_NOT_ON_HIGHWAY" 33 "RR_UNAVAILABLE_EAC_REQUEST_TIMEOUT" 9 "LC_UNAVAILABLE_TRAILER_MODE_ACTIVE" 30 "RR_UNAVAILABLE_CAM_WATCHDOG" 1 "LC_UNAVAILABLE_EPAS_EAC_DENIED" 27 "RR_UNAVAILABLE_STEERING_LIMITS_EXCEEDED" 16 "LC_UNAVAILABLE_APP_ME_STATE_NOT_VISION" 255 "LC_UNAVAILABLE_UNKNOWN" 7 "LC_UNAVAILABLE_STEERING_LIMITS_EXCEEDED" 18 "LC_UNAVAILABLE_NOT_ON_HIGHWAY" 15 "LC_UNAVAILABLE_ME_MAIN_STATE_NOT_VISION" 34 "RR_UNAVAILABLE_USER_STRIKEOUT" 10 "LC_UNAVAILABLE_CAM_WATCHDOG" 2 "LC_UNAVAILABLE_COMPONENT_MIA" 11 "LC_UNAVAILABLE_HK_TW_RESTRICTED" 25 "RR_UNAVAILABLE_VEHICLE_NOT_IN_DRIVE" 23 "RR_UNAVAILABLE_COMPONENT_NOT_READY" 36 "RR_UNAVAILABLE_CONTROL_OUTSIDE_LIMITS" 6 "LC_UNAVAILABLE_VEHICLE_SPEED_ABOVE_MAX" 37 "RR_UNAVAILABLE_CONTROL_PATH_UNHEALTHY" 42 "RR_UNAVAILABLE_ROAD_ESTIMATOR_NOT_ALLOWED" 26 "RR_UNAVAILABLE_VEHICLE_SPEED_ABOVE_MAX" 3 "LC_UNAVAILABLE_COMPONENT_NOT_READY" 24 "RR_UNAVAILABLE_CRUISE_FAULT" 28 "RR_UNAVAILABLE_CAMERA_FAILSAFES" 17 "LC_UNAVAILABLE_SPEED_LIMIT_EXCEEDED" 0 "LC_UNAVAILABLE_NONE" 19 "LC_UNAVAILABLE_VEHICLE_SPEED_ABOVE_MAX_HYST" 22 "RR_UNAVAILABLE_COMPONENT_MIA" 38 "RR_UNAVAILABLE_CONTROL_SOLVER_UNHEALTHY" 21 "RR_UNAVAILABLE_EPAS_EAC_DENIED" 43 "RR_UNAVAILABLE_DRIVE_ON_MAPS_NOT_ALLOWED" 29 "RR_UNAVAILABLE_TRAILER_MODE_ACTIVE" 41 "RR_UNAVAILABLE_VEHICLE_SPEED_ABOVE_MAX_HYST" 13 "LC_UNAVAILABLE_EAC_REQUEST_TIMEOUT" 20 "RR_UNAVAILABLE_NONE" 4 "LC_UNAVAILABLE_CRUISE_FAULT" 8 "LC_UNAVAILABLE_CAMERA_FAILSAFES" 39 "RR_UNAVAILABLE_SPEED_LIMIT_EXCEEDED" 12 "LC_UNAVAILABLE_CAM_MSG_MIA" 32 "RR_UNAVAILABLE_CAM_MSG_MIA" ;
VAL_ 1465 DAS_sw194_leadVx 31 "SNA" ;
VAL_ 1465 DAS_sw069_diAPState 6 "DI_APC_ABORTED" 8 "DI_APC_UNPARK_COMPLETE" 7 "DI_APC_RESUMED" 0 "DI_APC_UNAVAILABLE" 4 "DI_APC_COMPLETE" 5 "DI_APC_PAUSED" 1 "DI_APC_STANDBY" 3 "DI_APC_ACTIVE" 9 "DI_APC_SNA" 2 "DI_APC_STARTED" ;
VAL_ 1465 DAS_sw032_errorType 0 "None" 1 "Overrun" 2 "Generic" ;
VAL_ 1465 DAS_sw004_accState 0 "IDLE" 6 "CANCEL_CAMERA" 1 "ACTIVE" 11 "CANCEL_OUT_OF_CALIBRATION" 3 "HOLD" 8 "FAULT" 2 "STANDSTILL" 7 "CANCEL_RADAR" 9 "CANCEL_PATH_NOT_CLEAR" 5 "CANCEL_GENERIC" 10 "CANCEL_GENERIC_SILENT" 4 "READY_FOR_RESUME" ;
VAL_ 1465 DAS_sw031_errorType 1 "Length" 6 "Mailbox" 0 "None" 2 "Checksum" 5 "Overrun" 3 "Sequence" 7 "CAN_Bus" 4 "Invalid_Data" 8 "Generic" ;
VAL_ 1465 DAS_sw024_currentVehicleApp 7 "DAS_VA_BSD" 88 "DAS_VA_VL_GM_COV_VEH_ID1" 150 "DAS_VA_VL_GM_HEADING_VEH_ID3" 36 "DAS_VA_VL_UU" 128 "DAS_VA_VL_GM_DP_FUSE_VEH_ID5" 12 "DAS_VA_TSR" 76 "DAS_VA_VL_GM_CHK_ID_VEH_ID1" 83 "DAS_VA_VL_GM_CHK_LANE_VEH_ID2" 52 "DAS_VA_VL_GM_VEH_ID4" 44 "DAS_VA_VL_GM_HPP_2" 20 "DAS_VA_VL_RLV" 55 "DAS_VA_VL_GM_EVAL_SETUP" 47 "DAS_VA_VL_GM_VEH_2" 95 "DAS_VA_VL_GM_OBS_XFM_VEH_ID2" 141 "DAS_VA_VL_GM_NODP_LONG_VEH_ID0" 14 "DAS_VA_TRAJECTORY_PLANNER" 121 "DAS_VA_VL_GM_DP_OLD_VEH_ID4" 64 "DAS_VA_VL_GM_EVAL_VEH_3" 138 "DAS_VA_VL_GM_NODP_LAT_VEH_ID3" 67 "DAS_VA_VL_GM_EVAL_NEW_VEH_0" 54 "DAS_VA_VL_GM_EVAL" 85 "DAS_VA_VL_GM_CHK_LANE_VEH_ID4" 50 "DAS_VA_VL_GM_VEH_ID2" 106 "DAS_VA_VL_GM_DP_PRECHK_VEH_ID1" 43 "DAS_VA_VL_GM_LANE_2" 154 "DAS_VA_VL_GM_MISC_END_VEH_ID1" 40 "DAS_VA_VL_GM_FS_1" 6 "DAS_VA_AHB" 152 "DAS_VA_VL_GM_HEADING_VEH_ID5" 126 "DAS_VA_VL_GM_DP_FUSE_VEH_ID3" 100 "DAS_VA_VL_GM_INV_COV_VEH_ID1" 75 "DAS_VA_VL_GM_CHK_ID_VEH_ID0" 84 "DAS_VA_VL_GM_CHK_LANE_VEH_ID3" 159 "DAS_VA_VL_GM_VEH_EXIT" 53 "DAS_VA_VL_GM_VEH_ID5" 87 "DAS_VA_VL_GM_COV_VEH_ID0" 149 "DAS_VA_VL_GM_HEADING_VEH_ID2" 161 "DAS_VA_EAC_MONITOR" 127 "DAS_VA_VL_GM_DP_FUSE_VEH_ID4" 120 "DAS_VA_VL_GM_DP_OLD_VEH_ID3" 65 "DAS_VA_VL_GM_EVAL_VEH_4" 19 "DAS_VA_VL_SO" 129 "DAS_VA_VL_GM_NODP_FUSE_VEH_ID0" 139 "DAS_VA_VL_GM_NODP_LAT_VEH_ID4" 111 "DAS_VA_VL_GM_DP_NEW_VEH_ID0" 23 "DAS_VA_VL_UNO" 57 "DAS_VA_VL_GM_EVAL_LL" 29 "DAS_VA_VL_UELP" 98 "DAS_VA_VL_GM_OBS_XFM_VEH_ID5" 151 "DAS_VA_VL_GM_HEADING_VEH_ID4" 125 "DAS_VA_VL_GM_DP_FUSE_VEH_ID2" 99 "DAS_VA_VL_GM_INV_COV_VEH_ID0" 30 "DAS_VA_VL_CFELC" 86 "DAS_VA_VL_GM_CHK_LANE_VEH_ID5" 51 "DAS_VA_VL_GM_VEH_ID3" 105 "DAS_VA_VL_GM_DP_PRECHK_VEH_ID0" 35 "DAS_VA_VL_CDH" 153 "DAS_VA_VL_GM_MISC_END_VEH_ID0" 58 "DAS_VA_VL_GM_EVAL_RL" 148 "DAS_VA_VL_GM_HEADING_VEH_ID1" 90 "DAS_VA_VL_GM_COV_VEH_ID3" 11 "DAS_VA_LDW" 104 "DAS_VA_VL_GM_INV_COV_VEH_ID5" 78 "DAS_VA_VL_GM_CHK_ID_VEH_ID3" 81 "DAS_VA_VL_GM_CHK_LANE_VEH_ID0" 110 "DAS_VA_VL_GM_DP_PRECHK_VEH_ID5" 158 "DAS_VA_VL_GM_MISC_END_VEH_ID5" 112 "DAS_VA_VL_GM_DP_NEW_VEH_ID1" 17 "DAS_VA_VIRTUAL_WALL" 31 "DAS_VA_VL_CMC" 97 "DAS_VA_VL_GM_OBS_XFM_VEH_ID4" 119 "DAS_VA_VL_GM_DP_OLD_VEH_ID2" 60 "DAS_VA_VL_GM_EVAL_NAV" 66 "DAS_VA_VL_GM_EVAL_VEH_5" 28 "DAS_VA_VL_CCM" 130 "DAS_VA_VL_GM_NODP_FUSE_VEH_ID1" 34 "DAS_VA_VL_MP" 9 "DAS_VA_FCM" 140 "DAS_VA_VL_GM_NODP_LAT_VEH_ID5" 135 "DAS_VA_VL_GM_NODP_LAT_VEH_ID0" 70 "DAS_VA_VL_GM_EVAL_NEW_VEH_3" 115 "DAS_VA_VL_GM_DP_NEW_VEH_ID4" 41 "DAS_VA_VL_GM_VEH_1" 94 "DAS_VA_VL_GM_OBS_XFM_VEH_ID1" 144 "DAS_VA_VL_GM_NODP_LONG_VEH_ID3" 25 "DAS_VA_VL_UFC" 61 "DAS_VA_VL_GM_EVAL_VEH_0" 133 "DAS_VA_VL_GM_NODP_FUSE_VEH_ID4" 103 "DAS_VA_VL_GM_INV_COV_VEH_ID4" 56 "DAS_VA_VL_GM_EVAL_MODEL" 77 "DAS_VA_VL_GM_CHK_ID_VEH_ID2" 82 "DAS_VA_VL_GM_CHK_LANE_VEH_ID1" 109 "DAS_VA_VL_GM_DP_PRECHK_VEH_ID4" 39 "DAS_VA_VL_GM_HPP_1" 157 "DAS_VA_VL_GM_MISC_END_VEH_ID4" 22 "DAS_VA_VL_ULWE" 147 "DAS_VA_VL_GM_HEADING_VEH_ID0" 89 "DAS_VA_VL_GM_COV_VEH_ID2" 24 "DAS_VA_VL_FM" 146 "DAS_VA_VL_GM_NODP_LONG_VEH_ID5" 118 "DAS_VA_VL_GM_DP_OLD_VEH_ID1" 26 "DAS_VA_VL_SM" 131 "DAS_VA_VL_GM_NODP_FUSE_VEH_ID2" 72 "DAS_VA_VL_GM_EVAL_NEW_VEH_5" 113 "DAS_VA_VL_GM_DP_NEW_VEH_ID2" 160 "DAS_VA_VL_PROFILER" 93 "DAS_VA_VL_GM_OBS_XFM_VEH_ID0" 143 "DAS_VA_VL_GM_NODP_LONG_VEH_ID2" 46 "DAS_VA_VL_GM_NAV_2" 62 "DAS_VA_VL_GM_EVAL_VEH_1" 21 "DAS_VA_VL_CFKO" 134 "DAS_VA_VL_GM_NODP_FUSE_VEH_ID5" 136 "DAS_VA_VL_GM_NODP_LAT_VEH_ID1" 69 "DAS_VA_VL_GM_EVAL_NEW_VEH_2" 116 "DAS_VA_VL_GM_DP_NEW_VEH_ID5" 59 "DAS_VA_VL_GM_EVAL_HPP" 108 "DAS_VA_VL_GM_DP_PRECHK_VEH_ID3" 156 "DAS_VA_VL_GM_MISC_END_VEH_ID3" 92 "DAS_VA_VL_GM_COV_VEH_ID5" 124 "DAS_VA_VL_GM_DP_FUSE_VEH_ID1" 5 "DAS_VA_SCA" 102 "DAS_VA_VL_GM_INV_COV_VEH_ID3" 80 "DAS_VA_VL_GM_CHK_ID_VEH_ID5" 10 "DAS_VA_ACC" 13 "DAS_VA_CSA" 48 "DAS_VA_VL_GM_VEH_ID0" 71 "DAS_VA_VL_GM_EVAL_NEW_VEH_4" 4 "DAS_VA_APC" 15 "DAS_VA_WORLD_MODEL" 114 "DAS_VA_VL_GM_DP_NEW_VEH_ID3" 1 "DAS_VA_INIT" 0 "DAS_VA_NONE" 145 "DAS_VA_VL_GM_NODP_LONG_VEH_ID4" 117 "DAS_VA_VL_GM_DP_OLD_VEH_ID0" 132 "DAS_VA_VL_GM_NODP_FUSE_VEH_ID3" 8 "DAS_VA_LC" 74 "DAS_VA_ROB" 18 "DAS_VA_ROAD_FURNITURE" 32 "DAS_VA_VL_GM" 137 "DAS_VA_VL_GM_NODP_LAT_VEH_ID2" 68 "DAS_VA_VL_GM_EVAL_NEW_VEH_1" 33 "DAS_VA_VL_ETC" 27 "DAS_VA_VL_CDE" 37 "DAS_VA_VL_GM_SETUP" 96 "DAS_VA_VL_GM_OBS_XFM_VEH_ID3" 142 "DAS_VA_VL_GM_NODP_LONG_VEH_ID1" 42 "DAS_VA_VL_GM_NAV_1" 122 "DAS_VA_VL_GM_DP_OLD_VEH_ID5" 63 "DAS_VA_VL_GM_EVAL_VEH_2" 2 "DAS_VA_VEHICLE" 123 "DAS_VA_VL_GM_DP_FUSE_VEH_ID0" 101 "DAS_VA_VL_GM_INV_COV_VEH_ID2" 73 "DAS_VA_VL_GM_EVAL_SAVE" 3 "DAS_VA_PMM" 79 "DAS_VA_VL_GM_CHK_ID_VEH_ID4" 49 "DAS_VA_VL_GM_VEH_ID1" 107 "DAS_VA_VL_GM_DP_PRECHK_VEH_ID2" 155 "DAS_VA_VL_GM_MISC_END_VEH_ID2" 38 "DAS_VA_VL_GM_LANE_1" 45 "DAS_VA_VL_GM_FS_2" 16 "DAS_VA_VIRTUAL_LANE" 91 "DAS_VA_VL_GM_COV_VEH_ID4" ;
VAL_ 1465 DAS_sw194_leadDx 255 "SNA" ;
VAL_ 1465 DAS_sw199_abortCodePARK 31 "SNA" 15 "SYSTEM_SERVICE" 11 "HANDS_ON_DETECTED" 6 "MAX_SWA_DEV_EXCEEDED" 0 "NONE" 8 "OBSTACLE_ON_PATH" 1 "VELOCITY_TOO_HIGH" 17 "ERROR" 12 "VEHICLE_DYNAMICS_INTERVENTION" 10 "FULL_WARNING_ON_BOTH_SIDES" 5 "OFF_TRACK" 13 "EPAS_FAULT" 3 "NO_VALID_PATH" 9 "PARK_SPACE_TOO_SMALL" 4 "UNCONTROLLED_TRAVEL_DIST_REACHED" 16 "SYSTEM_FAULT" 14 "DAS_ABORT" 2 "MAX_NUM_OF_MOVES" 7 "MAX_YAW_ANGLE_REACHED" ;
VAL_ 1465 DAS_sw042_abort_reason 0 "LC_ABORT_NONE" 24 "LC_ABORT_DRIVE_ON_MAPS" 6 "LC_ABORT_HEALTH_MONITOR" 20 "RR_ABORT_CONTROLLER_HEALTH" 11 "LC_ABORT_CAMERA_FAILSAFES" 18 "LC_ABORT_APP_ME_STATE" 25 "LC_ABORT_AEB" 3 "LC_ABORT_CRUISE_FAULT" 15 "LC_ABORT_CAMERA_WATCHDOG" 4 "LC_ABORT_CID_SWITCH_DISABLED" 17 "LC_ABORT_ME_MAIN_STATE" 22 "LC_ABORT_CRUISE_WENT_UNAVAILABLE" 23 "LC_ABORT_ECU_THERMAL_ISSUE" 10 "LC_ABORT_EPAS_ERROR_CODE" 14 "LC_ABORT_TRAILER_MODE_ACTIVATION" 1 "LC_ABORT_EPAS_EAC_DENIED" 5 "LC_ABORT_DRIVING_OFF_NAV" 8 "LC_ABORT_FOLLOWER_OUTPUT_INVALID" 12 "LC_ABORT_ACC_CANCEL" 21 "RR_ABORT_CONTROL_NOT_ALLOWED" 16 "LC_ABORT_CAMERA_MSG_MIA" 19 "RR_ABORT_WATCHDOG_HEALTH_CRITICAL" 2 "LC_ABORT_COMPONENT_MIA" 7 "LC_ABORT_VEHICLE_SPEED_ABOVE_MAX" 13 "LC_ABORT_SIDE_COLLISION_IMMINENT" 9 "LC_ABORT_PLANNER_OUTPUT_INVALID" ;
VAL_ 1465 DAS_sw073_escalateLDWreason 0 "LC_ELDW_REASON_NONE" 1 "LC_ELDW_REASON_SINGLE_PULL" 3 "LC_ELDW_REASON_STW_TAKEOVER" 2 "LC_ELDW_REASON_DOUBLE_PULL" ;
VAL_ 1465 DAS_sw227_sensorNumber 1 "SENSOR_MIDDLE" 0 "SENSOR_FRONT" ;
VAL_ 1465 DAS_sw030_heaterState 0 "NORMAL" 1 "OPEN" 2 "SHORT" ;
VAL_ 1465 DAS_sw059_parkMia 7 "CH_PARK_pasFrontMiddle_MIA" 6 "CH_PARK_sensorStatusFront_MIA" 0 "Nominal" 9 "CH_PARK_oloDict_MIA" 10 "CH_PARK_sensorStatusRear_MIA" 8 "CH_PARK_status2_MIA" 11 "CH_PARK_pasRearMiddle_MIA" 5 "CH_PARK_status_MIA" 2 "CH_PARK_pscStatus_MIA" 3 "CH_PARK_sdiRear_MIA" 4 "CH_PARK_oocStatus_MIA" 1 "CH_PARK_sdiFront_MIA" ;
VAL_ 1465 DAS_sw033_gtwMia 0 "Nominal" 8 "CH_BC_status_MIA" 6 "CH_VIP_405HS_MIA" 1 "CH_GTW_carConfig_MIA" 2 "CH_GTW_chNm_MIA" 7 "CH_GTW_gitHash_MIA" 5 "CH_GTW_time_MIA" 4 "CH_GTW_status_MIA" 3 "CH_GTW_odo_MIA" ;
VAL_ 1465 DAS_sw194_leadAx 31 "SNA" ;
VAL_ 1465 DAS_sw227_sensorSide 0 "VEHICLE_SIDE_LEFT" 1 "VEHICLE_SIDE_RIGHT" ;
VAL_ 1465 DAS_sw035_espMia 8 "ESP_wheelSpeeds_MIA" 5 "ESP_C_MIA" 0 "Nominal" 9 "ESP_B_MIA" 2 "ESP_135h_MIA" 6 "DISCONTINUED_ESP_E_MIA" 1 "ESP_125h_MIA" 3 "ESP_145h_MIA" 7 "ESP_115h_MIA" 4 "DISCONTINUED_ESP_A_MIA" ;
VAL_ 1465 DAS_sw022_operation 2 "Read" 1 "Write" 0 "Initialize" 4 "Erase_All" 3 "Delete" ;
VAL_ 1465 DAS_sw045_radMia 1 "RAD0_RADC_alertMatrix_MIA" 11 "RAD0_RADC_ACCTargObj5_A_MIA" 3 "RAD0_RADC_info_MIA" 8 "RAD0_RADC_FCWTargObj_A_MIA" 17 "RAD0_RADC_ACCTargObj1_C_MIA" 18 "RAD0_RADC_ACCTargObj1_B_MIA" 16 "RAD0_RADC_ACCTargObj2_A_MIA" 0 "Nominal" 5 "RAD0_RADC_Packet_Ender_MIA" 9 "RAD0_RADC_ACCTargObj5_C_MIA" 4 "RAD0_RADC_Packet_Starter_MIA" 10 "RAD0_RADC_ACCTargObj5_B_MIA" 12 "RAD0_RADC_ACCTargObj4_C_MIA" 19 "RAD0_RADC_ACCTargObj1_A_MIA" 13 "RAD0_RADC_ACCTargObj3_C_MIA" 6 "RAD0_RADC_FCWTargObj_C_MIA" 15 "RAD0_RADC_ACCTargObj2_B_MIA" 21 "RAD0_RADC_TGU_info_MIA" 20 "RAD0_RADC_SGU_info_MIA" 7 "RAD0_RADC_FCWTargObj_B_MIA" 14 "RAD0_RADC_ACCTargObj2_C_MIA" 2 "RAD0_RADRL_alertMatrix_MIA" ;
VAL_ 1465 DAS_sw032_canBus 1 "RAD0" 7 "Unknown" 0 "CH" 2 "PARTY" ;
VAL_ 1465 DAS_sw042_health_state 3 "AP_HEALTH_SEVERELY_DEGRADED" 2 "AP_HEALTH_DEGRADED" 6 "AP_HEALTH_UNUSED" 7 "AP_HEALTH_SNA" 0 "AP_HEALTH_UNAVAILABLE" 5 "AP_HEALTH_FAULT" 4 "AP_HEALTH_ABORTING" 1 "AP_HEALTH_NOMINAL" ;
VAL_ 1465 DAS_sw031_canBus 1 "RAD0" 7 "Unknown" 0 "CH" 2 "PARTY" ;
VAL_ 1465 DAS_sw199_abortCodeDAS 10 "APC_ABORT_SCCM_MIA" 11 "APC_ABORT_ESP_MIA" 6 "APC_ABORT_PARK_MIA" 21 "APC_ABORT_USER_KEYFOB" 20 "APC_ABORT_SC_MIA" 5 "APC_ABORT_PREGUIDANCE_TIMEOUT" 13 "APC_ABORT_PAUSE_USER_TIMEOUT" 23 "APC_ABORT_PAUSE_CYCLES" 15 "APC_ABORT_PARK_GEAR" 19 "APC_ABORT_SENSOR_FAILURE" 9 "APC_ABORT_MCU_MIA" 8 "APC_ABORT_DI_MIA" 1 "APC_ABORT_LOST_ANGLE_CONTROL" 0 "APC_ABORT_NONE" 4 "APC_ABORT_INVALID_SPACE" 17 "APC_ABORT_UI_REQUEST" 7 "APC_ABORT_EPAS_MIA" 22 "APC_ABORT_EPAS_INHIBITED" 2 "APC_ABORT_PARK_GUIDANCE_ENDED" 12 "APC_ABORT_PAUSE_OBSTACLE_TIMEOUT" 18 "APC_ABORT_PRECRUISE_TIMEOUT" 14 "APC_ABORT_RESTART_TIMEOUT" 24 "APC_ABORT_APP_MIA" 3 "APC_ABORT_MCU_REQUEST_MISMATCH" 16 "APC_ABORT_LOST_DI_CONTROL" ;
VAL_ 1465 DAS_alertState 0 "ALERT_CLEARED" 1 "ALERT_SET" ;
VAL_ 1465 DAS_alertID 9 "DAS_w009_aebFault" 133 "DAS_w133_mainCamInitFault" 24 "DAS_w024_ECU_Watchdog_Reset" 35 "DAS_w035_espMia" 205 "DAS_w205_apcFinalRear" 207 "DAS_w207_autosteerUnavailable" 44 "DAS_w044_appMobileyeFailure" 105 "DAS_w105_DEPRECATED" 29 "DAS_w029_spi_tx_error" 135 "DAS_w135_fisheyeCamInitFault" 17 "DAS_w017_Cam_Msg_MIA" 136 "DAS_w136_lPillarCamInitFault" 141 "DAS_w141_ECU_Thermal_Issue" 21 "DAS_w021_ECU_Temperature_Issue" 95 "DAS_w095_DEPRECATED" 68 "DAS_w068_vlInconsistency" 211 "DAS_w211_accNoSeatBelt" 96 "DAS_w096_DEPRECATED" 224 "DAS_w224_accCameraCalibration" 23 "DAS_w023_ECU_Cam_Statemismatc" 134 "DAS_w134_narrowCamInitFault" 206 "DAS_w206_autosteerNotEnabled" 217 "DAS_w217_lcUnavailableSpeeding" 43 "DAS_w043_camLongRunTime" 14 "DAS_w014_swAssert" 93 "DAS_w093_DEPRECATED" 179 "DAS_w179_rPillarCamCalSaved" 49 "DAS_w049_eyeqVersionMismatch" 67 "DAS_w067_steeringAlignment" 56 "DAS_w056_diMia" 6 "DAS_w006_aebCancelled" 83 "DAS_w083_inPathRADObject" 175 "DAS_w175_rRepeatCamExtNotCal" 82 "DAS_w082_inPathFSviolation" 178 "DAS_w178_lPillarCamCalSaved" 77 "DAS_w077_pmmActive" 215 "DAS_w215_contDriverNotIntracting" 225 "DAS_w225_lcDegradedVisSpeedLmt" 52 "DAS_w052_radcSensorIssue" 57 "DAS_w057_mcuMia" 47 "DAS_w047_edrEvent" 38 "DAS_w038_camFailure" 40 "DAS_w040_autopilotAngleSaturated" 204 "DAS_w204_apcFinalFront" 27 "DAS_w027_ECU_Reset_Fault" 226 "DAS_w226_lcCamCalNeededSpeedLmt" 33 "DAS_w033_gtwMia" 99 "DAS_w099_DEPRECATED" 139 "DAS_w139_rRepeatCamInitFault" 78 "DAS_w078_pmmActive2" 228 "DAS_w228_DEPRECATED" 26 "DAS_w026_ECU_timingIssue" 10 "DAS_w010_radcCalibIssue" 19 "DAS_w019_ECU_Stack_Overflow" 25 "DAS_w025_LC_Steering_Override" 230 "DAS_w230_alcUltrasoundBlocked" 15 "DAS_w015_Camera_Failsafes" 216 "DAS_w216_driverOverriding" 66 "DAS_w066_deserializerLockLost" 222 "DAS_w222_accCameraBlind" 36 "DAS_w036_bdyMia" 203 "DAS_w203_apcActivation" 171 "DAS_w171_fisheyeCamExtNotCal" 198 "DAS_w198_tsrUnavailable" 97 "DAS_w097_DEPRECATED" 60 "DAS_w060_fcw_event" 196 "DAS_w196_stopSignWarning" 13 "DAS_w013_Cam_Watchdog" 58 "DAS_w058_epbMia" 81 "DAS_w081_pmmActiveBraking" 208 "DAS_w208_rackDetected" 172 "DAS_w172_lPillarCamExtNotCal" 7 "DAS_w007_ahlbDisabled" 227 "DAS_w227_virtualWallBlocked" 90 "DAS_w090_DEPRECATED" 89 "DAS_w089_DEPRECATED" 173 "DAS_w173_rPillarCamExtNotCal" 8 "DAS_w008_parkDisabled" 50 "DAS_w050_aeb_event" 16 "DAS_w016_aeb_e_event" 130 "DAS_w130_narrowCamExtNotCal" 177 "DAS_w177_fisheyeCamCalSaved" 200 "DAS_w200_lcSlowdown" 72 "DAS_w072_selfparkComplete" 197 "DAS_w197_redLightWarning" 100 "DAS_w100_DEPRECATED" 218 "DAS_w218_lcSpeedExceededLimit" 11 "DAS_w011_scaEvent" 4 "DAS_w004_accDisabled" 61 "DAS_w061_airSuspensionMia" 223 "DAS_w223_accObjectInPath" 229 "DAS_w229_alcUltrasoundDamaged" 70 "DAS_w070_apcIncompleteCal" 48 "DAS_w048_DAS_Features_Disabled" 42 "DAS_w042_autopilotAborting" 12 "DAS_w012_Cam_BootFailure" 2 "DAS_w002_ldwDisabled" 80 "DAS_w080_accFailedActivation" 180 "DAS_w180_lRepeatCamCalSaved" 73 "DAS_w073_issueEscalatedLDW" 87 "DAS_w087_DEPRECATED" 54 "DAS_w054_camAutofix" 143 "DAS_w143_IDF_event" 144 "DAS_w144_selfieCamInitFault" 201 "DAS_w201_lcAborting" 138 "DAS_w138_lRepeatCamInitFault" 22 "DAS_w022_ECU_EEPROM_Failure" 41 "DAS_w041_autopilotRateSaturated" 63 "DAS_w063_parkVersionMismatch" 71 "DAS_w071_selfparkStarted" 132 "DAS_w132_narrowCamCalSaved" 45 "DAS_w045_radMia" 214 "DAS_w214_driverNotIntracting" 74 "DAS_w074_inPathStationaryObst" 140 "DAS_w140_backupCamInitFault" 104 "DAS_w104_DEPRECATED" 131 "DAS_w131_mainCamCalSaved" 213 "DAS_w213_autosteerStruckOut" 69 "DAS_w069_apcSpaceMasked" 37 "DAS_w037_camTacIssue" 94 "DAS_w094_DEPRECATED" 129 "DAS_w129_mainCamExtNotCal" 79 "DAS_w079_edrAvailable" 34 "DAS_w034_sccmMia" 5 "DAS_w005_fcwCancelled" 18 "DAS_w018_ECU_Power_Issue" 76 "DAS_w076_mobilEyeSetC" 174 "DAS_w174_lRepeatCamExtNotCal" 219 "DAS_w219_lcTempUnavailableSpeed" 31 "DAS_w031_canRxError" 193 "DAS_w193_camWindshieldUnclean" 181 "DAS_w181_rRepeatCamCalSaved" 91 "DAS_w091_DEPRECATED" 199 "DAS_w199_apcAbort" 59 "DAS_w059_parkMia" 221 "DAS_w221_accRadarBlind" 220 "DAS_w220_lcTempUnavailableRoad" 65 "DAS_w065_deserializerOvercurrent" 88 "DAS_w088_DEPRECATED" 84 "DAS_w084_pmmIPSO" 39 "DAS_w039_sdm_rcm_Mia" 0 "DAS_ALERT_DO_NOT_USE_ZERO" 32 "DAS_w032_canTxError" 101 "DAS_w101_DEPRECATED" 30 "DAS_w030_Heater_Issue" 137 "DAS_w137_rPillarCamInitFault" 209 "DAS_w209_autoSummonRequest" 28 "DAS_w028_spi_rx_error" 92 "DAS_w092_DEPRECATED" 102 "DAS_w102_DEPRECATED" 55 "DAS_w055_radcVersionMismatch" 210 "DAS_w210_camObstrcted" 51 "DAS_w051_radcEcuIssue" 62 "DAS_w062_radcAlignment" 231 "DAS_w231_idfEvent" 53 "DAS_w053_radcCommIssue" 103 "DAS_w103_robExperimentalAEB" 106 "DAS_w106_torsionBarCalibrated" 86 "DAS_w086_robCollision" 194 "DAS_w194_accDriverResumeRqrd" 75 "DAS_w075_scMia" 3 "DAS_w003_isaDisabled" 64 "DAS_w064_epasMia" 202 "DAS_w202_scwNoisyEnvironment" 46 "DAS_w046_eepromRecordAbsent" 142 "DAS_w142_fwdCamPitchProblem" 98 "DAS_w098_DEPRECATED" 212 "DAS_w212_lcUnavailableStrikeOut" 195 "DAS_w195_scwUnavailable" 20 "DAS_w020_ECU_checkstopError" 85 "DAS_w085_pmmSteering" ;
VAL_ 2043 APB_alertID 0 "APB_ALERT_DO_NOT_USE_ZERO" ;
VAL_ 2043 APB_alertState 0 "ALERT_CLEARED" 1 "ALERT_SET" ;
VAL_ 297 SCCM_steeringAngleValidity 3 "SNA" 2 "INIT" 0 "INVALID" 1 "VALID" ;
VAL_ 297 SCCM_steeringAngleSensorStatus 0 "OK" 1 "INIT" 2 "ERROR" 3 "ERROR_INIT" ;
VAL_ 644 UI_serviceMode 1 "SERVICE_MODE_ENABLED" 0 "SERVICE_MODE_DISABLED" ;
VAL_ 644 UI_showroomMode 1 "SHOWROOM_MODE_ENABLED" 0 "SHOWROOM_MODE_DISABLED" ;
VAL_ 644 UI_transportMode 1 "TRANSPORT_MODE_ENABLED" 0 "TRANSPORT_MODE_DISABLED" ;
VAL_ 644 UI_factoryMode 0 "FACTORY_MODE_DISABLED" 1 "FACTORY_MODE_ENABLED" ;
VAL_ 1025 LRR_lowPowerMode 3 "SNA" 1 "COMMANDED_LOW_POWER" 0 "DEFAULT_LOW_POWER" 2 "NORMAL_POWER" ;
VAL_ 977 EPAS3S_resyncStatus 1 "RESYNC_COMPLETE" 0 "RESYNC_PENDING" ;
VAL_ 1285 ESP_alertState 0 "ALERT_CLEARED" 1 "ALERT_SET" ;
VAL_ 1285 ESP_alertID 160 "ESP_a160_ayRangeExceeded" 13 "ESP_a013_valveRelayUndervoltage" 79 "ESP_a079_ReRWSSSupplyShortToGnd" 140 "ESP_a140_RCMInertial1Timeout" 178 "ESP_a178_IBSTOutputRodActInvalid" 239 "ESP_a239_UIodoDLC" 49 "ESP_a049_FrRWSSDirectionFault" 257 "ESP_a257_epbmStatusChecksum" 124 "ESP_a124_ebrSkidActive" 171 "ESP_a171_axImplausible" 36 "ESP_a036_FrLWSSLargeAirGap" 105 "ESP_a105_ebrFault" 68 "ESP_a068_ReRWSSShortTo12V" 38 "ESP_a038_FrLWSSGeneralFault" 22 "ESP_a022_WSSDirectionFault" 130 "ESP_a130_EPAS3PsysStatusTimeout" 204 "ESP_a204_DItorqueDLC" 116 "ESP_a116_tsmActive" 235 "ESP_a235_PMstate2Counter" 232 "ESP_a232_PMstate2Timeout" 192 "ESP_a192_DIchassiControlDLC" 75 "ESP_a075_ReRWSSSignalNoise" 161 "ESP_a161_ayOffsetExceeded" 19 "ESP_a019_WSSSignRearAxle" 252 "ESP_a252_vdcWhlSlipLimFrLInvalid" 100 "ESP_a100_brakeTempModelDisabled" 206 "ESP_a206_DItorqueCounter" 114 "ESP_a114_tvdcActive" 155 "ESP_a155_ayMaxLatency" 202 "ESP_a202_accelPedalInvalid" 222 "ESP_a222_DIvdcRightDLC" 183 "ESP_a183_IBSTStatusOff" 17 "ESP_a017_netOvervoltage" 57 "ESP_a057_ReLWSSTooManyPulses" 173 "ESP_a173_IBSTparty1DLC" 41 "ESP_a041_FrRWSSLineInterruption" 242 "ESP_a242_LVPowerStateDLC" 190 "ESP_a190_DIbtcRequestCounter" 258 "ESP_a258_epbmStatusDLC" 168 "ESP_a168_axRangeExceeded" 164 "ESP_a164_axInitFault" 23 "ESP_a023_WSSSeveralSuspected" 156 "ESP_a156_ayInitFault" 255 "ESP_a255_vdcWhlSlipLimReRInvalid" 213 "ESP_a213_DIStorqueCounter" 238 "ESP_a238_UIodoTimeout" 154 "ESP_a154_RCMInertial2Counter" 177 "ESP_a177_IBSTOutputRodDrvInvalid" 227 "ESP_a227_bdwRequestActiveInvalid" 76 "ESP_a076_ReRWSSVDiffFault" 223 "ESP_a223_DIvdcRightChecksum" 250 "ESP_a250_vdcBrkeTrqTarReLInvalid" 11 "ESP_a011_12VSystemUndervoltage" 212 "ESP_a212_DIStorqueChecksum" 6 "ESP_a006_USVValvesFault" 71 "ESP_a071_ReRWSSTooManyPulses" 249 "ESP_a249_vdcBrkeTrqTarFrRInvalid" 147 "ESP_a147_yawSensorNotAvailable" 200 "ESP_a200_reverseGearStuckHigh" 139 "ESP_a139_steeringAngleWrongSign" 86 "ESP_a086_BrakeSwitchImplausible1" 240 "ESP_a240_LVPowerStateTimeout" 211 "ESP_a211_DIStorqueDLC" 26 "ESP_a026_FrLWSSShortTo12V" 33 "ESP_a033_FrLWSSSignalNoise" 193 "ESP_a193_DIchassiControlChecksum" 53 "ESP_a053_ReLWSSOpenOrShortToGnd" 42 "ESP_a042_FrRWSSMaxSpeedExceeded" 218 "ESP_a218_DIvdcLeftDLC" 145 "ESP_a145_yawInitFault" 233 "ESP_a233_PMstate2Checksum" 60 "ESP_a060_ReLWSSWrongSensorType" 29 "ESP_a029_FrLWSSTooManyPulses" 185 "ESP_a185_IBSTFeedforwardBackup" 18 "ESP_a018_WSSSignFrontAxle" 107 "ESP_a107_reserved107" 256 "ESP_a256_epbmStatusTimeout" 129 "ESP_a129_reserved129" 108 "ESP_a108_reserved108" 122 "ESP_a122_bdwActive" 127 "ESP_a127_reserved127" 133 "ESP_a133_EPAS3PsysStatusCounter" 125 "ESP_a125_reserved125" 263 "ESP_a263_epblStatusCounter" 37 "ESP_a037_FrLWSSSupplyShortToGnd" 216 "ESP_a216_DISTorqueActualInvalid" 201 "ESP_a201_reverseGearStuckLow" 126 "ESP_a126_reserved126" 128 "ESP_a128_reserved128" 132 "ESP_a132_EPAS3PsysStatusChecksum" 137 "ESP_a137_steeringOffsetTooLarge" 109 "ESP_a109_reserved109" 174 "ESP_a174_IBSTparty1Checksum" 94 "ESP_a094_partyBusPassive" 9 "ESP_a009_12VHardUndervoltage" 102 "ESP_a102_absFault" 163 "ESP_a163_axMaxLatency" 40 "ESP_a040_FrRWSSShortTo12V" 198 "ESP_a198_DIsystemStatusChecksum" 123 "ESP_a123_ebrActive" 209 "ESP_a209_DITorqueActualInvalid" 194 "ESP_a194_DIchassiControlCounter" 169 "ESP_a169_axOffsetExceeded" 3 "ESP_a003_outletValvesFault" 199 "ESP_a199_DIsystemStatusCounter" 159 "ESP_a159_aySignalFault" 5 "ESP_a005_HSVValvesFault" 82 "ESP_a082_PMCSensorOffsetHigh" 101 "ESP_a101_ebdFault" 8 "ESP_a008_pumpMotor12VsupplyLow" 89 "ESP_a089_absNoPressureIncrease" 246 "ESP_a246_VCFRONTsensorTimeout" 39 "ESP_a039_FrRWSSOpenOrShortToGnd" 12 "ESP_a012_netUndervoltage" 10 "ESP_a010_12VUndervoltage" 46 "ESP_a046_FrRWSSWrongSensorType" 215 "ESP_a215_DISRPMInvalid" 231 "ESP_a231_storedVINMismatch" 221 "ESP_a221_DIvdcRightTimeout" 150 "ESP_a150_yawImplausible" 210 "ESP_a210_DIStorqueTimeout" 228 "ESP_a228_GTWvinTimeout" 220 "ESP_a220_DIvdcLeftCounter" 188 "ESP_a188_DIbtcRequestDLC" 152 "ESP_a152_RCMInertial2DLC" 236 "ESP_a236_ebrCommandStateInvalid" 14 "ESP_a014_WSSSupplyUndervoltage" 21 "ESP_a021_WSSGeneralVDiffFault" 243 "ESP_a243_LVPowerStateCounter" 44 "ESP_a044_FrRWSSLostSignal" 191 "ESP_a191_DIchassiControlTimeout" 134 "ESP_a134_steeringAngleInvalid" 170 "ESP_a170_axSignalFrozen" 181 "ESP_a181_IBSTparty2DLC" 16 "ESP_a016_12VSystemOvervoltage" 59 "ESP_a059_ReLWSSNoPulsesDetected" 61 "ESP_a061_ReLWSSSignalNoise" 58 "ESP_a058_ReLWSSLostSignal" 92 "ESP_a092_CANOvervoltage" 27 "ESP_a027_FrLWSSLineInterruption" 225 "ESP_a225_configMismatch" 97 "ESP_a097_tcsRefSpeedNotInit" 45 "ESP_a045_FrRWSSNoPulsesDetected" 32 "ESP_a032_FrLWSSWrongSensorType" 247 "ESP_a247_VCFRONTsensorDLC" 162 "ESP_a162_ayImplausible" 66 "ESP_a066_ReLWSSGeneralFault" 219 "ESP_a219_DIvdcLeftChecksum" 117 "ESP_a117_hbaActive" 112 "ESP_a112_espActive" 230 "ESP_a230_vinNotLearned" 217 "ESP_a217_DIvdcLeftTimeout" 65 "ESP_a065_ReLWSSSupplyShortToGnd" 197 "ESP_a197_DIsystemStatusDLC" 151 "ESP_a151_RCMInertial2Timeout" 24 "ESP_a024_WSSReverseCurrent" 186 "ESP_a186_IBSTBrakeAppliedInvalid" 96 "ESP_a096_chassisBusPassive" 241 "ESP_a241_LVPowerStateChecksum" 260 "ESP_a260_epblStatusTimeout" 81 "ESP_a081_PressureSensorShort" 248 "ESP_a248_vdcBrkeTrqTarFrLInvalid" 25 "ESP_a025_FrLWSSOpenOrShortToGnd" 251 "ESP_a251_vdcBrkeTrqTarReRInvalid" 167 "ESP_a167_axSignalFault" 28 "ESP_a028_FrLWSSMaxSpeedExceeded" 55 "ESP_a055_ReLWSSLineInterruption" 245 "ESP_a245_LVGoingDownStateInvalid" 77 "ESP_a077_ReRWSSDirectionFault" 176 "ESP_a176_IBSTEBRNotAvailable" 70 "ESP_a070_ReRWSSMaxSpeedExceeded" 119 "ESP_a119_hbbActive" 73 "ESP_a073_ReRWSSNoPulsesDetected" 111 "ESP_a111_absActive" 43 "ESP_a043_FrRWSSTooManyPulses" 50 "ESP_a050_FrRWSSLargeAirGap" 72 "ESP_a072_ReRWSSLostSignal" 254 "ESP_a254_vdcWhlSlipLimReLInvalid" 51 "ESP_a051_FrRWSSSupplyShortToGnd" 136 "ESP_a136_steeringAngleFrozen" 20 "ESP_a020_WSSGenericTempFault" 121 "ESP_a121_regenTcActive" 47 "ESP_a047_FrRWSSSignalNoise" 141 "ESP_a141_RCMInertial1DLC" 115 "ESP_a115_ebdActive" 90 "ESP_a090_vdcContinuousControl" 52 "ESP_a052_FrRWSSGeneralFault" 88 "ESP_a088_absContinuousControl" 166 "ESP_a166_axSensorNotAvailable" 103 "ESP_a103_stabilityControlFault" 2 "ESP_a002_valvesGenericFault" 144 "ESP_a144_yawMaxLatency" 262 "ESP_a262_epblStatusDLC" 113 "ESP_a113_btcActive" 99 "ESP_a099_brakeTempModelOverheat" 214 "ESP_a214_DISTorqueCommandInvalid" 182 "ESP_a182_IBSTparty2Counter" 93 "ESP_a093_partyBusOff" 0 "ESP_ALERT_DO_NOT_USE_ZERO" 253 "ESP_a253_vdcWhlSlipLimFrRInvalid" 142 "ESP_a142_RCMInertial1Checksum" 229 "ESP_a229_GTWvinDLC" 261 "ESP_a261_epblStatusChecksum" 184 "ESP_a184_IBSTpRunoutInvalid" 95 "ESP_a095_chassisBusOff" 205 "ESP_a205_DItorqueChecksum" 226 "ESP_a226_bdwRequestInvalid" 203 "ESP_a203_DItorqueTimeout" 64 "ESP_a064_ReLWSSLargeAirGap" 143 "ESP_a143_RCMInertial1Counter" 4 "ESP_a004_inletValvesFault" 56 "ESP_a056_ReLWSSMaxSpeedExceeded" 106 "ESP_a106_vdcActuatorFault" 153 "ESP_a153_RCMInertial2Checksum" 224 "ESP_a224_DIvdcRightCounter" 180 "ESP_a180_IBSTparty2Checksum" 172 "ESP_a172_IBSTparty1Timeout" 87 "ESP_a087_BrakeSwitchImplausible3" 179 "ESP_a179_IBSTparty2Timeout" 175 "ESP_a175_IBSTparty1Counter" 69 "ESP_a069_ReRWSSLineInterruption" 187 "ESP_a187_DIbtcRequestTimeout" 189 "ESP_a189_DIbtcRequestChecksum" 259 "ESP_a259_epbmStatusCounter" 195 "ESP_a195_ptcStateInvalid" 78 "ESP_a078_ReRWSSLargeAirGap" 74 "ESP_a074_ReRWSSWrongSensorType" 84 "ESP_a084_BrakeFluidReservoirLow" 110 "ESP_a110_rollerBenchActive" 85 "ESP_a085_BrakeSwitchStuckHigh" 48 "ESP_a048_FrRWSSVDiffFault" 135 "ESP_a135_steeringAngleNoCenter" 83 "ESP_a083_PMCSensorFault" 98 "ESP_a098_vdcRefSpeedNotInit" 34 "ESP_a034_FrLWSSVDiffFault" 157 "ESP_a157_ayInvalidValue" 120 "ESP_a120_rmiActive" 149 "ESP_a149_yawInvalidSign" 1 "ESP_a001_ecuGenericFault" 118 "ESP_a118_hfcActive" 138 "ESP_a138_steeringAngleImplaus" 62 "ESP_a062_ReLWSSVDiffFault" 104 "ESP_a104_hbcEnabled" 208 "ESP_a208_DIRPMInvalid" 196 "ESP_a196_DIsystemStatusTimeout" 54 "ESP_a054_ReLWSSShortTo12V" 244 "ESP_a244_LVOffStateInvalid" 165 "ESP_a165_axInvalidValue" 131 "ESP_a131_EPAS3PsysStatusDLC" 35 "ESP_a035_FrLWSSDirectionFault" 91 "ESP_a091_CANUndervoltage" 31 "ESP_a031_FrLWSSNoPulsesDetected" 15 "ESP_a015_12VSupplyOvervoltage" 7 "ESP_a007_pumpMotorFault" 63 "ESP_a063_ReLWSSDirectionFault" 207 "ESP_a207_DITorqueCommandInvalid" 30 "ESP_a030_FrLWSSLostSignal" 67 "ESP_a067_ReRWSSOpenOrShortToGnd" 234 "ESP_a234_PMstate2DLC" 146 "ESP_a146_yawInvalidValue" 237 "ESP_a237_vdcCommandStateInvalid" 148 "ESP_a148_yawSignalFault" 80 "ESP_a080_ReRWSSGeneralFault" 158 "ESP_a158_aySensorNotAvailable" ;
VAL_ 258 VCLEFT_mirrorHeatState 2 "HEATER_STATE_OFF" 4 "HEATER_STATE_FAULT" 1 "HEATER_STATE_ON" 0 "HEATER_STATE_SNA" 3 "HEATER_STATE_OFF_UNAVAILABLE" ;
VAL_ 258 VCLEFT_mirrorRecallState 5 "MIRROR_RECALL_STATE_RECALLING_STOPPED" 2 "MIRROR_RECALL_STATE_RECALLING_AXIS_2" 0 "MIRROR_RECALL_STATE_INIT" 3 "MIRROR_RECALL_STATE_RECALLING_COMPLETE" 4 "MIRROR_RECALL_STATE_RECALLING_FAILED" 1 "MIRROR_RECALL_STATE_RECALLING_AXIS_1" ;
VAL_ 258 VCLEFT_mirrorFoldState 4 "MIRROR_FOLD_STATE_UNFOLDING" 1 "MIRROR_FOLD_STATE_FOLDED" 3 "MIRROR_FOLD_STATE_FOLDING" 0 "MIRROR_FOLD_STATE_UNKNOWN" 2 "MIRROR_FOLD_STATE_UNFOLDED" ;
VAL_ 258 VCLEFT_mirrorState 3 "MIRROR_STATE_FOLD_UNFOLD" 1 "MIRROR_STATE_TILT_X" 0 "MIRROR_STATE_IDLE" 2 "MIRROR_STATE_TILT_Y" 4 "MIRROR_STATE_RECALL" ;
VAL_ 258 VCLEFT_rearLatchStatus 8 "LATCH_FAULT" 2 "LATCH_CLOSED" 1 "LATCH_OPENED" 3 "LATCH_CLOSING" 7 "LATCH_DEFAULT" 4 "LATCH_OPENING" 5 "LATCH_AJAR" 6 "LATCH_TIMEOUT" 0 "LATCH_SNA" ;
VAL_ 258 VCLEFT_frontLatchStatus 8 "LATCH_FAULT" 2 "LATCH_CLOSED" 1 "LATCH_OPENED" 3 "LATCH_CLOSING" 7 "LATCH_DEFAULT" 4 "LATCH_OPENING" 5 "LATCH_AJAR" 6 "LATCH_TIMEOUT" 0 "LATCH_SNA" ;
VAL_ 1022 APP_summonState 7 "SNA" 5 "GUIDANCE_FINISHED" 6 "FAULT" 2 "GUIDANCE_LEFT" 0 "NOT_AVAILABLE" 4 "PRE_GUIDANCE" 1 "SEARCHING" 3 "GUIDANCE_RIGHT" ;
VAL_ 1022 APP_summonInstruction 7 "SNA" 2 "DRIVE_FORWARD" 0 "NO_MESSAGE" 1 "STOP" 3 "DRIVE_BACKWARD" 4 "ABORTED" 5 "EXPLORATION" ;
